VERSION "HNNBNNNYNNNNNNNNNNNNNNNNNNNNNNNNNNNNNNNNNN/4/%%%/4/'%**4NNN///"

NS_ :

BS_:

BU_: ADR_PAG_X2 BAP_Tester GW_App_PAG_PF GW_Routing_PAG_PF Klima_PAG_PF Klimakomp_Dash_PAG_PF Kombi_PAG_PF Miko_PAG_X2 OCU_PAG_PF RDK_High_PAG_PF

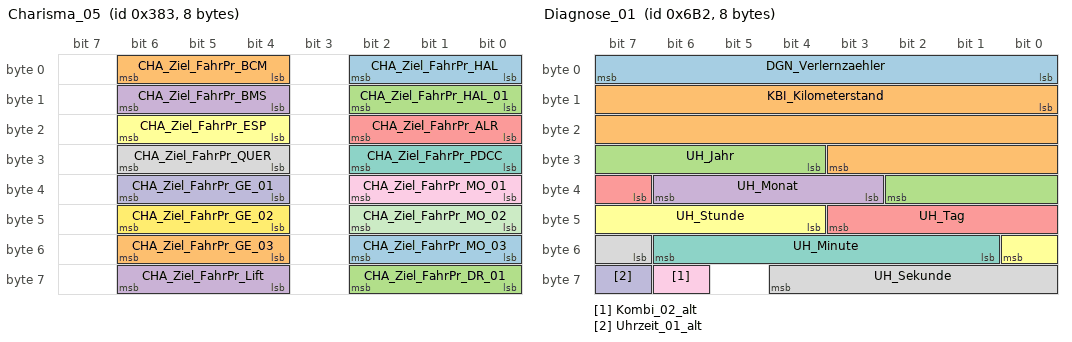
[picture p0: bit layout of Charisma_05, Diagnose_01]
BO_ 899 Charisma_05: 8 Klima_PAG_PF
 SG_ CHA_Ziel_FahrPr_HAL : 0|3@1+ (1,0) [0|7] ""  GW_Routing_PAG_PF
 SG_ CHA_Ziel_FahrPr_BCM : 4|3@1+ (1,0) [0|7] ""  GW_Routing_PAG_PF
 SG_ CHA_Ziel_FahrPr_HAL_01 : 8|3@1+ (1,0) [0|7] ""  GW_Routing_PAG_PF
 SG_ CHA_Ziel_FahrPr_BMS : 12|3@1+ (1,0) [0|7] ""  GW_Routing_PAG_PF
 SG_ CHA_Ziel_FahrPr_ALR : 16|3@1+ (1,0) [0|7] ""  GW_Routing_PAG_PF
 SG_ CHA_Ziel_FahrPr_ESP : 20|3@1+ (1,0) [0|7] ""  GW_Routing_PAG_PF
 SG_ CHA_Ziel_FahrPr_PDCC : 24|3@1+ (1,0) [0|7] ""  GW_Routing_PAG_PF
 SG_ CHA_Ziel_FahrPr_QUER : 28|3@1+ (1,0) [0|7] ""  GW_Routing_PAG_PF
 SG_ CHA_Ziel_FahrPr_MO_01 : 32|3@1+ (1,0) [0|7] ""  GW_Routing_PAG_PF
 SG_ CHA_Ziel_FahrPr_GE_01 : 36|3@1+ (1,0) [0|7] ""  GW_Routing_PAG_PF
 SG_ CHA_Ziel_FahrPr_MO_02 : 40|3@1+ (1,0) [0|7] ""  GW_Routing_PAG_PF
 SG_ CHA_Ziel_FahrPr_GE_02 : 44|3@1+ (1,0) [0|7] ""  GW_Routing_PAG_PF
 SG_ CHA_Ziel_FahrPr_MO_03 : 48|3@1+ (1,0) [0|7] ""  GW_Routing_PAG_PF
 SG_ CHA_Ziel_FahrPr_GE_03 : 52|3@1+ (1,0) [0|7] ""  GW_Routing_PAG_PF
 SG_ CHA_Ziel_FahrPr_DR_01 : 56|3@1+ (1,0) [0|7] ""  GW_Routing_PAG_PF
 SG_ CHA_Ziel_FahrPr_Lift : 60|3@1+ (1,0) [0|7] ""  GW_Routing_PAG_PF

BO_ 1335 Charisma_06: 8 GW_Routing_PAG_PF
 SG_ ALR_Charisma_FahrPr : 0|3@1+ (1,0) [0|7] "" Vector__XXX
 SG_ ALR_Charisma_Status : 3|2@1+ (1,0) [0|3] "" Vector__XXX
 SG_ ALR_Charisma_Umschaltung : 5|2@1+ (1,0) [0|3] "" Vector__XXX
 SG_ Allrad_02_alt : 7|1@1+ (1,0) [0|1] "" Vector__XXX
 SG_ ESP_Charisma_FahrPr : 8|3@1+ (1,0) [0|7] ""  Klima_PAG_PF
 SG_ ESP_Charisma_Status : 11|2@1+ (1,0) [0|3] ""  Klima_PAG_PF
 SG_ ESP_Charisma_Umschaltung : 13|2@1+ (1,0) [0|3] ""  Klima_PAG_PF
 SG_ ESP_11_alt : 15|1@1+ (1,0) [0|1] ""  Klima_PAG_PF
 SG_ PDCC_Charisma_FahrPr : 16|3@1+ (1,0) [0|7] "" Vector__XXX
 SG_ PDCC_Charisma_Status : 19|2@1+ (1,0) [0|3] "" Vector__XXX
 SG_ PDCC_Charisma_Umschaltung : 21|2@1+ (1,0) [0|3] "" Vector__XXX
 SG_ PDCC_01_PAG_alt : 23|1@1+ (1,0) [0|1] "" Vector__XXX
 SG_ QUER_Charisma_FahrPr : 24|3@1+ (1,0) [0|7] "" Vector__XXX
 SG_ QUER_Charisma_Status : 27|2@1+ (1,0) [0|3] "" Vector__XXX
 SG_ QUER_Charisma_Umschaltung : 29|2@1+ (1,0) [0|3] "" Vector__XXX
 SG_ Quersperre_02_PAG_alt : 31|1@1+ (1,0) [0|1] "" Vector__XXX
 SG_ HAL_Charisma_FahrPr : 32|3@1+ (1,0) [0|7] ""  Klima_PAG_PF
 SG_ HAL_Charisma_Status : 35|2@1+ (1,0) [0|3] ""  Klima_PAG_PF
 SG_ HAL_01_alt : 39|1@1+ (1,0) [0|1] ""  Klima_PAG_PF
 SG_ Lift_Charisma_FahrPr : 40|3@1+ (1,0) [0|7] ""  Klima_PAG_PF
 SG_ Lift_Charisma_Status : 43|2@1+ (1,0) [0|3] ""  Klima_PAG_PF
 SG_ Lift_Charisma_Umschaltung : 45|2@1+ (1,0) [0|3] ""  Klima_PAG_PF
 SG_ Lift_01_alt : 47|1@1+ (1,0) [0|1] ""  Klima_PAG_PF

BO_ 1714 Diagnose_01: 8 GW_App_PAG_PF
 SG_ DGN_Verlernzaehler : 0|8@1+ (1,0) [0|254] ""  ADR_PAG_X2,Klima_PAG_PF,Klimakomp_Dash_PAG_PF,Kombi_PAG_PF,Miko_PAG_X2,OCU_PAG_PF,RDK_High_PAG_PF
 SG_ KBI_Kilometerstand : 8|20@1+ (1,0) [0|1048573] "Unit_KiloMeter"  ADR_PAG_X2,Klima_PAG_PF,Klimakomp_Dash_PAG_PF,Miko_PAG_X2,OCU_PAG_PF,RDK_High_PAG_PF
 SG_ UH_Jahr : 28|7@1+ (1,2000) [2000|2127] "Unit_Year"  ADR_PAG_X2,Klima_PAG_PF,Klimakomp_Dash_PAG_PF,Kombi_PAG_PF,Miko_PAG_X2,OCU_PAG_PF,RDK_High_PAG_PF
 SG_ UH_Monat : 35|4@1+ (1,0) [1|12] "Unit_Month"  ADR_PAG_X2,Klima_PAG_PF,Klimakomp_Dash_PAG_PF,Kombi_PAG_PF,Miko_PAG_X2,OCU_PAG_PF,RDK_High_PAG_PF
 SG_ UH_Tag : 39|5@1+ (1,0) [1|31] "Unit_Day"  ADR_PAG_X2,Klima_PAG_PF,Klimakomp_Dash_PAG_PF,Kombi_PAG_PF,Miko_PAG_X2,OCU_PAG_PF,RDK_High_PAG_PF
 SG_ UH_Stunde : 44|5@1+ (1,0) [0|23] "Unit_Hours"  ADR_PAG_X2,Klima_PAG_PF,Klimakomp_Dash_PAG_PF,Kombi_PAG_PF,Miko_PAG_X2,OCU_PAG_PF,RDK_High_PAG_PF
 SG_ UH_Minute : 49|6@1+ (1,0) [0|59] "Unit_Minut"  ADR_PAG_X2,Klima_PAG_PF,Klimakomp_Dash_PAG_PF,Kombi_PAG_PF,Miko_PAG_X2,OCU_PAG_PF,RDK_High_PAG_PF
 SG_ UH_Sekunde : 55|6@1+ (1,0) [0|59] "Unit_Secon"  ADR_PAG_X2,Klima_PAG_PF,Klimakomp_Dash_PAG_PF,Kombi_PAG_PF,Miko_PAG_X2,OCU_PAG_PF,RDK_High_PAG_PF
 SG_ Kombi_02_alt : 62|1@1+ (1,0) [0|1] ""  ADR_PAG_X2,Klima_PAG_PF,Klimakomp_Dash_PAG_PF,Miko_PAG_X2,OCU_PAG_PF,RDK_High_PAG_PF
 SG_ Uhrzeit_01_alt : 63|1@1+ (1,0) [0|1] ""  ADR_PAG_X2,Klima_PAG_PF,Klimakomp_Dash_PAG_PF,Miko_PAG_X2,OCU_PAG_PF,RDK_High_PAG_PF

BO_ 1009 Diagnose_02_PAG: 8 GW_App_PAG_PF
 SG_ GW_STH_Anf : 0|2@1+ (1,0) [0|3] "" Vector__XXX
 SG_ FSAktivBit : 9|1@1+ (1,0) [0|1] "" Vector__XXX

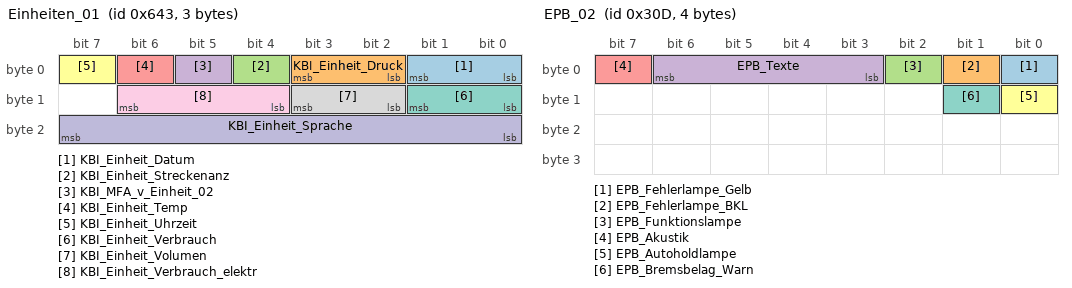
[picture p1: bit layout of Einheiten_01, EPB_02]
BO_ 1603 Einheiten_01: 3 ADR_PAG_X2
 SG_ KBI_Einheit_Datum : 0|2@1+ (1,0) [0|3] ""  GW_Routing_PAG_PF,Kombi_PAG_PF
 SG_ KBI_Einheit_Druck : 2|2@1+ (1,0) [0|3] ""  GW_Routing_PAG_PF,Kombi_PAG_PF
 SG_ KBI_Einheit_Streckenanz : 4|1@1+ (1,0) [0|1] ""  GW_Routing_PAG_PF,Kombi_PAG_PF,OCU_PAG_PF
 SG_ KBI_MFA_v_Einheit_02 : 5|1@1+ (1,0) [0|1] ""  GW_Routing_PAG_PF,Kombi_PAG_PF,OCU_PAG_PF
 SG_ KBI_Einheit_Temp : 6|1@1+ (1,0) [0|1] ""  GW_Routing_PAG_PF,Klima_PAG_PF,Kombi_PAG_PF,Miko_PAG_X2,OCU_PAG_PF
 SG_ KBI_Einheit_Uhrzeit : 7|1@1+ (1,0) [0|1] ""  GW_Routing_PAG_PF,Kombi_PAG_PF
 SG_ KBI_Einheit_Verbrauch : 8|2@1+ (1,0) [0|3] ""  GW_Routing_PAG_PF,Kombi_PAG_PF,OCU_PAG_PF
 SG_ KBI_Einheit_Volumen : 10|2@1+ (1,0) [0|3] ""  GW_Routing_PAG_PF,Kombi_PAG_PF
 SG_ KBI_Einheit_Verbrauch_elektr : 12|3@1+ (1,0) [0|7] ""  GW_Routing_PAG_PF
 SG_ KBI_Einheit_Sprache : 16|8@1+ (1,0) [0|255] ""  GW_Routing_PAG_PF,Kombi_PAG_PF,Miko_PAG_X2

BO_ 781 EPB_02: 4 GW_Routing_PAG_PF
 SG_ EPB_Fehlerlampe_Gelb : 0|1@1+ (1,0) [0|1] ""  Kombi_PAG_PF
 SG_ EPB_Fehlerlampe_BKL : 1|1@1+ (1,0) [0|1] "" Vector__XXX
 SG_ EPB_Funktionslampe : 2|1@1+ (1,0) [0|1] "" Vector__XXX
 SG_ EPB_Texte : 3|4@1+ (1,0) [0|15] ""  Kombi_PAG_PF
 SG_ EPB_Akustik : 7|1@1+ (1,0) [0|1] ""  Kombi_PAG_PF
 SG_ EPB_Autoholdlampe : 8|1@1+ (1,0) [0|1] "" Vector__XXX
 SG_ EPB_Bremsbelag_Warn : 9|1@1+ (1,0) [0|1] "" Vector__XXX

BO_ 256 ESP_01: 8 GW_Routing_PAG_PF
 SG_ ESP_01_CHK : 0|8@1+ (1,0) [0|255] "" Vector__XXX
 SG_ ESP_01_BZ : 8|4@1+ (1,0) [0|15] "" Vector__XXX
 SG_ ASR_Moment_langsam : 12|10@1+ (1,0) [0|1021] "" Vector__XXX
 SG_ ASR_MSR_Moment_schnell : 22|10@1+ (1,0) [0|1021] "" Vector__XXX
 SG_ ESP_v_Signal : 32|16@1+ (0.01,0) [0|655.32] "Unit_KiloMeterPerHour" Vector__XXX
 SG_ ASR_Tastung_passiv : 48|1@1+ (1,0) [0|1] ""  ADR_PAG_X2,Klima_PAG_PF,Kombi_PAG_PF
 SG_ ESP_Tastung_passiv : 49|1@1+ (1,0) [0|1] "" Vector__XXX
 SG_ ESP_Systemstatus : 50|1@1+ (1,0) [0|1] "" Vector__XXX
 SG_ ASR_Schalteingriff : 51|2@1+ (1,0) [0|3] "" Vector__XXX
 SG_ OBD_Schlechtweg : 53|1@1+ (1,0) [0|1] "" Vector__XXX
 SG_ OBD_QBit_Schlechtweg : 54|1@1+ (1,0) [0|1] "" Vector__XXX
 SG_ ESP_QBit_v_Signal : 55|1@1+ (1,0) [0|1] "" Vector__XXX
 SG_ ABS_Bremsung : 56|1@1+ (1,0) [0|1] "" Vector__XXX
 SG_ ASR_Anf : 57|1@1+ (1,0) [0|1] "" Vector__XXX
 SG_ MSR_Anf : 58|1@1+ (1,0) [0|1] "" Vector__XXX
 SG_ EBV_Eingriff : 59|1@1+ (1,0) [0|1] "" Vector__XXX
 SG_ EDS_Eingriff : 60|1@1+ (1,0) [0|1] "" Vector__XXX
 SG_ ESP_Eingriff : 61|1@1+ (1,0) [0|1] "" Vector__XXX
 SG_ ESP_ASP : 62|1@1+ (1,0) [0|1] "" Vector__XXX
 SG_ ESP_KD_Fehler : 63|1@1+ (1,0) [0|1] "" Vector__XXX

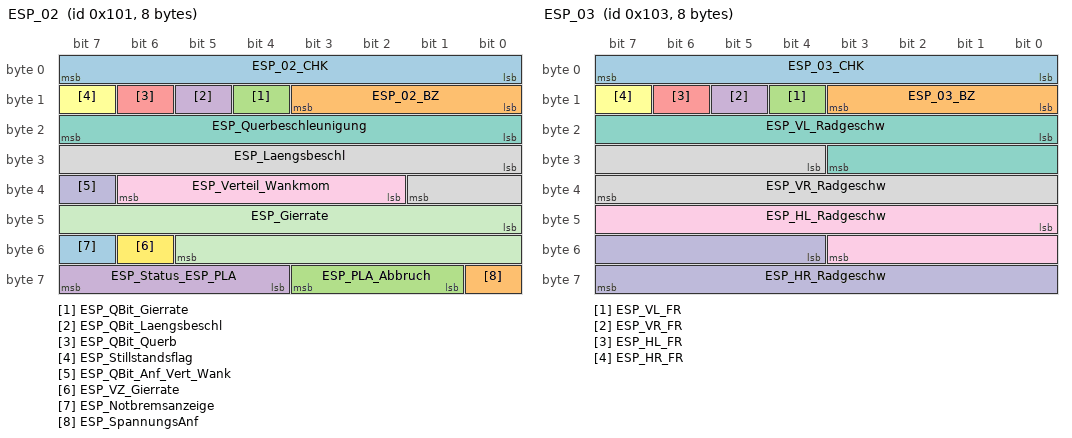
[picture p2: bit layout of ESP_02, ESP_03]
BO_ 257 ESP_02: 8 GW_Routing_PAG_PF
 SG_ ESP_02_CHK : 0|8@1+ (1,0) [0|255] "" Vector__XXX
 SG_ ESP_02_BZ : 8|4@1+ (1,0) [0|15] "" Vector__XXX
 SG_ ESP_QBit_Gierrate : 12|1@1+ (1,0) [0|1] "" Vector__XXX
 SG_ ESP_QBit_Laengsbeschl : 13|1@1+ (1,0) [0|1] "" Vector__XXX
 SG_ ESP_QBit_Querb : 14|1@1+ (1,0) [0|1] "" Vector__XXX
 SG_ ESP_Stillstandsflag : 15|1@1+ (1,0) [0|1] "" Vector__XXX
 SG_ ESP_Querbeschleunigung : 16|8@1+ (0.01,-1.27) [-1.27|1.27] "Unit_ForceOfGravi" Vector__XXX
 SG_ ESP_Laengsbeschl : 24|10@1+ (0.03125,-16) [-16|15.90625] "Unit_MeterPerSeconSquar"  ADR_PAG_X2,Kombi_PAG_PF
 SG_ ESP_Verteil_Wankmom : 34|5@1+ (0.1,-1) [-1|1] "" Vector__XXX
 SG_ ESP_QBit_Anf_Vert_Wank : 39|1@1+ (1,0) [0|1] "" Vector__XXX
 SG_ ESP_Gierrate : 40|14@1+ (0.01,0) [0|163.82] "Unit_DegreOfArcPerSecon" Vector__XXX
 SG_ ESP_VZ_Gierrate : 54|1@1+ (1,0) [0|1] "" Vector__XXX
 SG_ ESP_Notbremsanzeige : 55|1@1+ (1,0) [0|1] "" Vector__XXX
 SG_ ESP_SpannungsAnf : 56|1@1+ (1,0) [0|1] "" Vector__XXX
 SG_ ESP_PLA_Abbruch : 57|3@1+ (1,0) [0|7] "" Vector__XXX
 SG_ ESP_Status_ESP_PLA : 60|4@1+ (1,0) [0|15] "" Vector__XXX

BO_ 259 ESP_03: 8 GW_Routing_PAG_PF
 SG_ ESP_03_CHK : 0|8@1+ (1,0) [0|255] "" Vector__XXX
 SG_ ESP_03_BZ : 8|4@1+ (1,0) [0|15] "" Vector__XXX
 SG_ ESP_VL_FR : 12|1@1+ (1,0) [0|1] "" Vector__XXX
 SG_ ESP_VR_FR : 13|1@1+ (1,0) [0|1] "" Vector__XXX
 SG_ ESP_HL_FR : 14|1@1+ (1,0) [0|1] "" Vector__XXX
 SG_ ESP_HR_FR : 15|1@1+ (1,0) [0|1] "" Vector__XXX
 SG_ ESP_VL_Radgeschw : 16|12@1+ (0.1,0) [0|409.2] "Unit_KiloMeterPerHour"  Kombi_PAG_PF
 SG_ ESP_VR_Radgeschw : 28|12@1+ (0.1,0) [0|409.2] "Unit_KiloMeterPerHour"  Kombi_PAG_PF
 SG_ ESP_HL_Radgeschw : 40|12@1+ (0.1,0) [0|409.2] "Unit_KiloMeterPerHour"  Kombi_PAG_PF
 SG_ ESP_HR_Radgeschw : 52|12@1+ (0.1,0) [0|409.2] "Unit_KiloMeterPerHour"  Kombi_PAG_PF

BO_ 776 ESP_04: 8 GW_Routing_PAG_PF
 SG_ ESP_Meldungen : 0|3@1+ (1,0) [0|7] ""  Kombi_PAG_PF
 SG_ ESP_HDC_FktLampe : 3|1@1+ (1,0) [0|1] "" Vector__XXX
 SG_ ESP_Lampe : 4|1@1+ (1,0) [0|1] ""  Kombi_PAG_PF
 SG_ ABS_Lampe : 5|1@1+ (1,0) [0|1] ""  Kombi_PAG_PF
 SG_ BK_Lampe : 6|1@1+ (1,0) [0|1] ""  Kombi_PAG_PF
 SG_ ESP_Akustik : 7|2@1+ (1,0) [0|3] "" Vector__XXX
 SG_ ESP_Diagnose : 9|1@1+ (1,0) [0|1] ""  Kombi_PAG_PF
 SG_ ESP_Textanzeigen_02 : 10|5@1+ (1,0) [0|31] ""  Kombi_PAG_PF
 SG_ ESP_Off_Lampe : 15|1@1+ (1,0) [0|1] ""  Klima_PAG_PF
 SG_ ESP_m_Raddrehz : 16|15@1+ (0.002,0) [0|65.278] "Unit_Hertz" Vector__XXX
 SG_ ESP_ASR_Lampe : 31|1@1+ (1,0) [0|1] "" Vector__XXX
 SG_ ESP_Wegimp_VA : 32|11@1+ (1,0) [0|2047] ""  Kombi_PAG_PF
 SG_ ESP_Fehlerstatus_Wegimp : 43|1@1+ (1,0) [0|1] "" Vector__XXX
 SG_ ESP_Wegimp_Ueberlauf : 44|1@1+ (1,0) [0|1] ""  Kombi_PAG_PF
 SG_ ESP_QBit_Wegimp_VA : 45|1@1+ (1,0) [0|1] "" Vector__XXX
 SG_ ESP_Displaywarnungen : 46|2@1+ (1,0) [0|3] "" Vector__XXX
 SG_ ESP_HDC_Regelgeschw : 48|7@1+ (0.32,0) [0.32|39.68] "Unit_KiloMeterPerHour" Vector__XXX
 SG_ ESP_BKV_Warnung : 55|1@1+ (1,0) [0|1] ""  Kombi_PAG_PF
 SG_ ESP_Zaehnezahl : 56|8@1+ (1,0) [0|255] ""  Kombi_PAG_PF

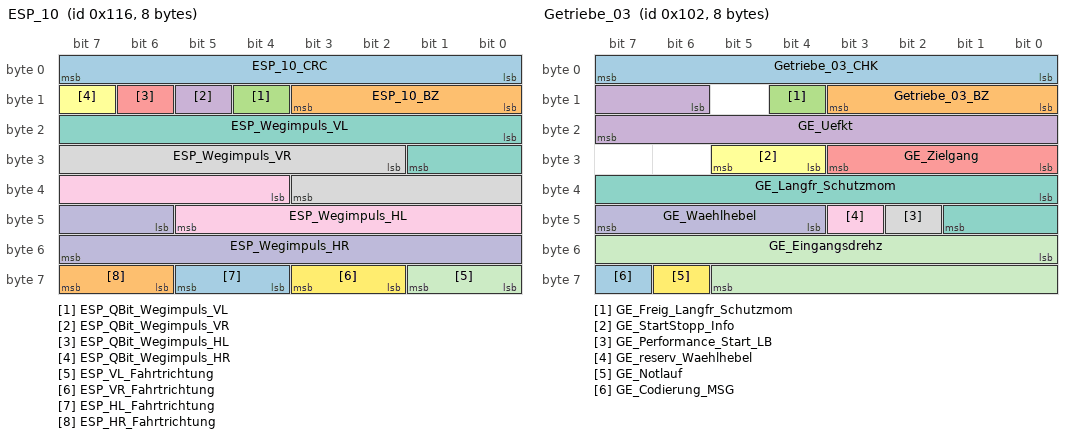
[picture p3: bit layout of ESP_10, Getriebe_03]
BO_ 278 ESP_10: 8 GW_Routing_PAG_PF
 SG_ ESP_10_CRC : 0|8@1+ (1,0) [0|255] "" Vector__XXX
 SG_ ESP_10_BZ : 8|4@1+ (1,0) [0|15] "" Vector__XXX
 SG_ ESP_QBit_Wegimpuls_VL : 12|1@1+ (1,0) [0|1] ""  ADR_PAG_X2
 SG_ ESP_QBit_Wegimpuls_VR : 13|1@1+ (1,0) [0|1] ""  ADR_PAG_X2
 SG_ ESP_QBit_Wegimpuls_HL : 14|1@1+ (1,0) [0|1] ""  ADR_PAG_X2
 SG_ ESP_QBit_Wegimpuls_HR : 15|1@1+ (1,0) [0|1] ""  ADR_PAG_X2
 SG_ ESP_Wegimpuls_VL : 16|10@1+ (1,0) [0|1000] ""  ADR_PAG_X2
 SG_ ESP_Wegimpuls_VR : 26|10@1+ (1,0) [0|1000] ""  ADR_PAG_X2
 SG_ ESP_Wegimpuls_HL : 36|10@1+ (1,0) [0|1000] ""  ADR_PAG_X2
 SG_ ESP_Wegimpuls_HR : 46|10@1+ (1,0) [0|1000] ""  ADR_PAG_X2
 SG_ ESP_VL_Fahrtrichtung : 56|2@1+ (1,0) [0|3] ""  ADR_PAG_X2
 SG_ ESP_VR_Fahrtrichtung : 58|2@1+ (1,0) [0|3] ""  ADR_PAG_X2
 SG_ ESP_HL_Fahrtrichtung : 60|2@1+ (1,0) [0|3] ""  ADR_PAG_X2
 SG_ ESP_HR_Fahrtrichtung : 62|2@1+ (1,0) [0|3] ""  ADR_PAG_X2

BO_ 963 Gateway_01: 8 GW_Routing_PAG_PF
 SG_ Motor_03_alt : 0|1@1+ (1,0) [0|1] ""  ADR_PAG_X2,Klima_PAG_PF,Kombi_PAG_PF,RDK_High_PAG_PF
 SG_ Getriebe_03_alt : 1|1@1+ (1,0) [0|1] ""  ADR_PAG_X2
 SG_ ESP_02_alt : 2|1@1+ (1,0) [0|1] "" Vector__XXX
 SG_ Motor_05_alt : 3|1@1+ (1,0) [0|1] ""  Klima_PAG_PF
 SG_ LWR_AFS_01_alt : 4|1@1+ (1,0) [0|1] "" Vector__XXX
 SG_ EPB_01_alt : 5|1@1+ (1,0) [0|1] ""  ADR_PAG_X2
 SG_ ESP_05_alt : 6|1@1+ (1,0) [0|1] "" Vector__XXX
 SG_ ESP_01_alt : 7|1@1+ (1,0) [0|1] ""  ADR_PAG_X2,Klima_PAG_PF,Kombi_PAG_PF
 SG_ ESP_v_Signal : 8|16@1+ (0.01,0) [0|655.32] "Unit_KiloMeterPerHour"  ADR_PAG_X2,Klima_PAG_PF,Kombi_PAG_PF
 SG_ ESP_Notbremsanzeige : 24|1@1+ (1,0) [0|1] "" Vector__XXX
 SG_ ECD_Bremslicht : 25|1@1+ (1,0) [0|1] "" Vector__XXX
 SG_ EPB_Status : 26|2@1+ (1,0) [0|3] ""  ADR_PAG_X2
 SG_ MO_Anf_KL75 : 28|1@1+ (1,0) [0|1] "" Vector__XXX
 SG_ MO_QBit_Fahrer_bremst : 29|1@1+ (1,0) [0|1] "" Vector__XXX
 SG_ EPB_BCM2_Motor_Wakeup : 30|1@1+ (1,0) [0|1] "" Vector__XXX
 SG_ ESP_QBit_v_Signal : 31|1@1+ (1,0) [0|1] "" Vector__XXX
 SG_ GE_Waehlhebel : 32|4@1+ (1,0) [0|15] ""  ADR_PAG_X2
 SG_ MO_Motor_laeuft : 36|1@1+ (1,0) [0|1] ""  Klima_PAG_PF,Kombi_PAG_PF
 SG_ MO_Verbot_EKP : 37|1@1+ (1,0) [0|1] "" Vector__XXX
 SG_ MO_Anf_Pruefimpuls : 38|1@1+ (1,0) [0|1] "" Vector__XXX
 SG_ LWR_Touristenmodus_aktiv : 39|1@1+ (1,0) [0|1] "" Vector__XXX
 SG_ MO_Drehzahl_01 : 40|16@1+ (0.25,0) [0|16383] "Unit_MinutInver"  ADR_PAG_X2,RDK_High_PAG_PF
 SG_ MO_Klima_Eingr : 56|2@1+ (1,0) [0|3] ""  Klima_PAG_PF
 SG_ MO_BLS : 58|1@1+ (1,0) [0|1] "" Vector__XXX
 SG_ MO_Fahrer_bremst : 59|1@1+ (1,0) [0|1] "" Vector__XXX
 SG_ MO_Aussp_Anlass : 60|1@1+ (1,0) [0|1] "" Vector__XXX
 SG_ MO_Freig_Anlass : 61|1@1+ (1,0) [0|1] "" Vector__XXX
 SG_ MO_Kuppl_schalter : 62|1@1+ (1,0) [0|1] "" Vector__XXX
 SG_ MO_Interlock : 63|1@1+ (1,0) [0|1] "" Vector__XXX

BO_ 1643 Gateway_03: 8 GW_Routing_PAG_PF
 SG_ Motor_07_alt : 0|1@1+ (1,0) [0|1] "" Vector__XXX
 SG_ Motor_Code_01_alt : 1|1@1+ (1,0) [0|1] "" Vector__XXX
 SG_ Kombi_02_alt : 2|1@1+ (1,0) [0|1] ""  RDK_High_PAG_PF
 SG_ Telefon_01_alt : 3|1@1+ (1,0) [0|1] "" Vector__XXX
 SG_ EPB_01_alt : 4|1@1+ (1,0) [0|1] "" Vector__XXX
 SG_ Motor_05_alt : 5|1@1+ (1,0) [0|1] ""  Klima_PAG_PF
 SG_ Motor_06_alt : 6|1@1+ (1,0) [0|1] ""  ADR_PAG_X2,Klima_PAG_PF
 SG_ MO_Kuehlmittel_Temp : 8|8@1+ (0.75,-48) [-48|141.75] "Unit_DegreCelsi" Vector__XXX
 SG_ KBI_Aussen_Temp_gef : 16|8@1+ (0.5,-50) [-50|75] "Unit_DegreCelsi"  RDK_High_PAG_PF
 SG_ MO_Kraftstoffart : 24|4@1+ (1,0) [0|15] "" Vector__XXX
 SG_ MO_Kennfeldk : 28|1@1+ (1,0) [0|1] "" Vector__XXX
 SG_ KBI_QBit_Aussen_Temp_gef : 29|1@1+ (1,0) [0|1] ""  RDK_High_PAG_PF
 SG_ MO_Absperrventil_oeffnen : 30|2@1+ (1,0) [0|3] "" Vector__XXX
 SG_ KBI_Standzeit : 32|15@1+ (4,0) [0|131068] "Unit_Secon" Vector__XXX
 SG_ KBI_Reset_Standzeit : 47|1@1+ (1,0) [0|1] "" Vector__XXX
 SG_ TF_Phone_mute : 48|1@1+ (1,0) [0|1] "" Vector__XXX
 SG_ EPB_QBit_Pedalweg_Kuppl : 49|1@1+ (1,0) [0|1] "" Vector__XXX
 SG_ TF_Mute_Msg_Code : 50|3@1+ (1,0) [0|7] "" Vector__XXX
 SG_ MO_HYB_Fahrbereitschaft : 53|1@1+ (1,0) [0|1] ""  ADR_PAG_X2,Klima_PAG_PF
 SG_ MO_EKlKomLeiRed : 54|2@1+ (1,0) [0|3] ""  Klima_PAG_PF
 SG_ EPB_Pedalweg_Kuppl : 56|8@1+ (0.4,0) [8|92] "Unit_PerCent" Vector__XXX

BO_ 924 Gateway_05: 8 GW_Routing_PAG_PF
 SG_ BCM1_02_alt : 0|1@1+ (1,0) [0|1] "" Vector__XXX
 SG_ Wischer_01_alt : 1|1@1+ (1,0) [0|1] "" Vector__XXX
 SG_ Klima_02_alt : 2|1@1+ (1,0) [0|1] "" Vector__XXX
 SG_ BCM1_01_alt : 3|1@1+ (1,0) [0|1] "" Vector__XXX
 SG_ ESP_07_alt : 4|1@1+ (1,0) [0|1] "" Vector__XXX
 SG_ TSG_BT_1_alt : 5|1@1+ (1,0) [0|1] "" Vector__XXX
 SG_ TSG_HL_1_alt : 6|1@1+ (1,0) [0|1] "" Vector__XXX
 SG_ TSG_HR_1_alt : 7|1@1+ (1,0) [0|1] "" Vector__XXX
 SG_ Motor_02_alt : 8|1@1+ (1,0) [0|1] "" Vector__XXX
 SG_ Klima_Sensor_02_alt : 9|1@1+ (1,0) [0|1] "" Vector__XXX
 SG_ TSG_FT_1_alt : 10|1@1+ (1,0) [0|1] "" Vector__XXX
 SG_ Motor_05_alt : 11|1@1+ (1,0) [0|1] ""  Klima_PAG_PF
 SG_ QSP_01_alt : 12|1@1+ (1,0) [0|1] "" Vector__XXX
 SG_ Parkhilfe_01_alt : 13|1@1+ (1,0) [0|1] "" Vector__XXX
 SG_ Fahrwerk_02_alt : 14|1@1+ (1,0) [0|1] "" Vector__XXX
 SG_ GW_05_va_27 : 15|1@1+ (1,0) [0|1] "" Vector__XXX
 SG_ BCM1_MH_WIV_Schalter : 16|1@1+ (1,0) [0|1] "" Vector__XXX
 SG_ Wischer_vorne_aktiv : 17|1@1+ (1,0) [0|1] "" Vector__XXX
 SG_ BCM1_Rueckfahrlicht_Schalter : 18|1@1+ (1,0) [0|1] "" Vector__XXX
 SG_ MO_Status_Normalbetrieb_01 : 19|1@1+ (1,0) [0|1] "" Vector__XXX
 SG_ KL_Zuheizer_Freigabe : 20|1@1+ (1,0) [0|1] "" Vector__XXX
 SG_ BCM1_Vorwaertsgang_eingelegt : 21|1@1+ (1,0) [0|1] "" Vector__XXX
 SG_ ESP_Codierung_ADS : 22|2@1+ (1,0) [0|3] "" Vector__XXX
 SG_ QSP_StartStopp_Info : 24|2@1+ (1,0) [0|3] "" Vector__XXX
 SG_ FA_StartStopp_Info : 26|2@1+ (1,0) [0|3] "" Vector__XXX
 SG_ PH_StartStopp_Info : 28|2@1+ (1,0) [0|3] "" Vector__XXX
 SG_ KL_Beschlagsgefahr : 30|1@1+ (1,0) [0|1] "" Vector__XXX
 SG_ BCM1_GLW_Fernlicht_Anf : 31|1@1+ (1,0) [0|1] "" Vector__XXX
 SG_ BCM1_RFahrlicht_Fzg_Anf : 32|1@1+ (1,0) [0|1] "" Vector__XXX
 SG_ FT_Tuer_geoeffnet : 33|1@1+ (1,0) [0|1] "" Vector__XXX
 SG_ MO_Handshake_STH : 34|1@1+ (1,0) [0|1] "" Vector__XXX
 SG_ FT_Sperrklinke : 35|1@1+ (1,0) [0|1] "" Vector__XXX
 SG_ BCM1_OBD_FStatus_ATemp : 36|4@1+ (1,0) [0|15] "" Vector__XXX
 SG_ BCM1_Aussen_Temp_ungef : 40|8@1+ (0.5,-50) [-50|76] "Unit_DegreCelsi" Vector__XXX
 SG_ BCM1_Oeldruck_Schalter : 48|1@1+ (1,0) [0|1] "" Vector__XXX
 SG_ BCM1_Oeldruck_Schalter_2 : 49|1@1+ (1,0) [0|1] "" Vector__XXX
 SG_ BT_Tuer_geoeffnet : 50|1@1+ (1,0) [0|1] "" Vector__XXX
 SG_ HL_Tuer_geoeffnet : 51|1@1+ (1,0) [0|1] "" Vector__XXX
 SG_ HR_Tuer_geoeffnet : 52|1@1+ (1,0) [0|1] "" Vector__XXX
 SG_ BCM1_Adaptive_Lichtvert_Anf : 53|1@1+ (1,0) [0|1] "" Vector__XXX
 SG_ BCM1_Gleitende_Leuchtw_Anf : 54|1@1+ (1,0) [0|1] "" Vector__XXX
 SG_ BCM1_Schalter_StartStopp : 55|1@1+ (1,0) [0|1] "" Vector__XXX
 SG_ ESP_Offroad_Modus : 56|1@1+ (1,0) [0|1] "" Vector__XXX
 SG_ MO_Freig_Reku : 57|2@1+ (1,0) [0|3] ""  Klima_PAG_PF
 SG_ KL_HSH_ein_Soll : 59|1@1+ (1,0) [0|1] "" Vector__XXX
 SG_ FT_Tuerkontakt_Rohsignal : 60|1@1+ (1,0) [0|1] "" Vector__XXX

BO_ 1318 Gateway_07: 8 GW_Routing_PAG_PF
 SG_ Klima_Sensor_02_alt : 0|1@1+ (1,0) [0|1] "" Vector__XXX
 SG_ Wischer_01_alt : 1|1@1+ (1,0) [0|1] "" Vector__XXX
 SG_ SMLS_01_alt : 2|1@1+ (1,0) [0|1] "" Vector__XXX
 SG_ Kessy_02_alt : 3|1@1+ (1,0) [0|1] "" Vector__XXX
 SG_ Blinkmodi_01_inaktiv : 4|1@1+ (1,0) [0|1] "" Vector__XXX
 SG_ Anhaenger_01_alt : 5|1@1+ (1,0) [0|1] "" Vector__XXX
 SG_ BCM1_01_alt : 6|1@1+ (1,0) [0|1] "" Vector__XXX
 SG_ BCM1_02_alt : 7|1@1+ (1,0) [0|1] "" Vector__XXX
 SG_ Innenlicht_01_alt : 8|1@1+ (1,0) [0|1] "" Vector__XXX
 SG_ BCM2_02_alt : 9|1@1+ (1,0) [0|1] "" Vector__XXX
 SG_ Motor_06_alt : 10|1@1+ (1,0) [0|1] ""  Klimakomp_Dash_PAG_PF
 SG_ HUD_01_alt : 11|1@1+ (1,0) [0|1] "" Vector__XXX
 SG_ TSG_FT_01_alt : 12|1@1+ (1,0) [0|1] "" Vector__XXX
 SG_ GW_07_va_25 : 13|1@1+ (1,0) [0|1] "" Vector__XXX
 SG_ GW_07_va_26 : 14|1@1+ (1,0) [0|1] "" Vector__XXX
 SG_ GW_07_va_27 : 15|1@1+ (1,0) [0|1] "" Vector__XXX
 SG_ BCM1_Aussen_Temp_ungef : 16|8@1+ (0.5,-50) [-50|76] "Unit_DegreCelsi" Vector__XXX
 SG_ BCM1_FStatus_Aussentemp_ungef : 24|1@1+ (1,0) [0|1] "" Vector__XXX
 SG_ Wischer_vorne_aktiv : 25|1@1+ (1,0) [0|1] "" Vector__XXX
 SG_ BH_Blinker_li : 26|1@1+ (1,0) [0|1] "" Vector__XXX
 SG_ BH_Blinker_re : 27|1@1+ (1,0) [0|1] "" Vector__XXX
 SG_ KY_Funkschl_Nr : 28|4@1+ (1,0) [0|15] "" Vector__XXX
 SG_ BCM1_Rueckfahrlicht_Schalter : 32|1@1+ (1,0) [0|1] "" Vector__XXX
 SG_ AAG_Anhaenger_erkannt : 33|1@1+ (1,0) [0|1] "" Vector__XXX
 SG_ BM_links : 34|1@1+ (1,0) [0|1] "" Vector__XXX
 SG_ BM_rechts : 35|1@1+ (1,0) [0|1] "" Vector__XXX
 SG_ BH_Fernlicht : 36|1@1+ (1,0) [0|1] "" Vector__XXX
 SG_ LDW_Taster : 37|1@1+ (1,0) [0|1] "" Vector__XXX
 SG_ LDW_Taster_Fehler : 38|1@1+ (1,0) [0|1] "" Vector__XXX
 SG_ LDW_Vib_Lenkrad_Fehler : 39|1@1+ (1,0) [0|1] "" Vector__XXX
 SG_ LV_Fernlicht_Anzeige : 40|1@1+ (1,0) [0|1] "" Vector__XXX
 SG_ LV_Abblendlicht_Anzeige : 41|1@1+ (1,0) [0|1] "" Vector__XXX
 SG_ LV_Nebellicht_Anzeige : 42|1@1+ (1,0) [0|1] "" Vector__XXX
 SG_ IL_Innenlicht_aktiv : 43|1@1+ (1,0) [0|1] "" Vector__XXX
 SG_ BCM1_MH_Schalter : 44|1@1+ (1,0) [0|1] "" Vector__XXX
 SG_ ZV_FT_offen : 45|1@1+ (1,0) [0|1] "" Vector__XXX
 SG_ ZV_BT_offen : 46|1@1+ (1,0) [0|1] "" Vector__XXX
 SG_ ZV_HL_offen : 47|1@1+ (1,0) [0|1] "" Vector__XXX
 SG_ ZV_HR_offen : 48|1@1+ (1,0) [0|1] "" Vector__XXX
 SG_ ZV_HD_offen : 49|1@1+ (1,0) [0|1] "" Vector__XXX
 SG_ ZV_verriegelt_extern_ist : 50|1@1+ (1,0) [0|1] "" Vector__XXX
 SG_ ZV_ist_Zustand_verfuegbar : 51|1@1+ (1,0) [0|1] "" Vector__XXX
 SG_ BCM1_NV_Taster : 52|1@1+ (1,0) [0|1] "" Vector__XXX
 SG_ MO_HYB_Fahrbereitschaft : 53|1@1+ (1,0) [0|1] ""  Klimakomp_Dash_PAG_PF
 SG_ HUD_VZE_in_Anzeige : 54|1@1+ (1,0) [0|1] "" Vector__XXX
 SG_ FT_SWA_Taster : 56|1@1+ (1,0) [0|1] "" Vector__XXX
 SG_ FT_SWA_Tasterdiagnose : 57|1@1+ (1,0) [0|1] "" Vector__XXX

BO_ 258 Getriebe_03: 8 GW_Routing_PAG_PF
 SG_ Getriebe_03_CHK : 0|8@1+ (1,0) [0|255] "" Vector__XXX
 SG_ Getriebe_03_BZ : 8|4@1+ (1,0) [0|15] "" Vector__XXX
 SG_ GE_Freig_Langfr_Schutzmom : 12|1@1+ (1,0) [0|1] "" Vector__XXX
 SG_ GE_Uefkt : 14|10@1+ (0.1,0) [0|102.2] "" Vector__XXX
 SG_ GE_Zielgang : 24|4@1+ (1,0) [0|15] ""  ADR_PAG_X2
 SG_ GE_StartStopp_Info : 28|2@1+ (1,0) [0|3] "" Vector__XXX
 SG_ GE_Langfr_Schutzmom : 32|10@1+ (1,0) [0|1021] "" Vector__XXX
 SG_ GE_Performance_Start_LB : 42|1@1+ (1,0) [0|1] "" Vector__XXX
 SG_ GE_reserv_Waehlhebel : 43|1@1+ (1,0) [0|1] "" Vector__XXX
 SG_ GE_Waehlhebel : 44|4@1+ (1,0) [0|15] "" Vector__XXX
 SG_ GE_Eingangsdrehz : 48|14@1+ (1,0) [0|16381] "Unit_MinutInver" Vector__XXX
 SG_ GE_Notlauf : 62|1@1+ (1,0) [0|1] "" Vector__XXX
 SG_ GE_Codierung_MSG : 63|1@1+ (1,0) [0|1] "" Vector__XXX

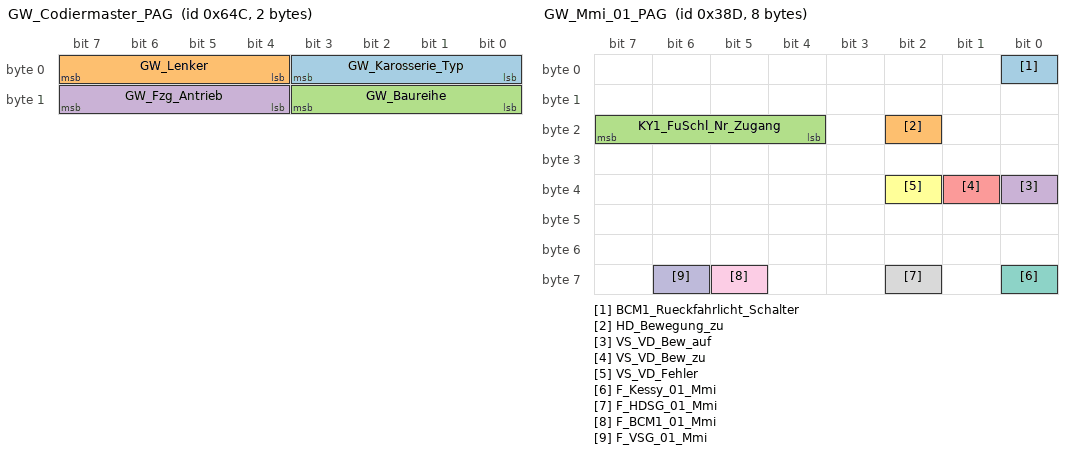
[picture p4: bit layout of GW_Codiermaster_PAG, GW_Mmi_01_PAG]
BO_ 1612 GW_Codiermaster_PAG: 2 GW_App_PAG_PF
 SG_ GW_Karosserie_Typ : 0|4@1+ (1,0) [0|15] ""  Klima_PAG_PF,OCU_PAG_PF
 SG_ GW_Lenker : 4|4@1+ (1,0) [0|15] ""  Klima_PAG_PF,OCU_PAG_PF
 SG_ GW_Baureihe : 8|4@1+ (1,0) [0|15] ""  Klima_PAG_PF,OCU_PAG_PF
 SG_ GW_Fzg_Antrieb : 12|4@1+ (1,0) [0|15] ""  OCU_PAG_PF

BO_ 909 GW_Mmi_01_PAG: 8 GW_Routing_PAG_PF
 SG_ BCM1_Rueckfahrlicht_Schalter : 0|1@1+ (1,0) [0|1] ""  ADR_PAG_X2,Klima_PAG_PF,Kombi_PAG_PF
 SG_ HD_Bewegung_zu : 18|1@1+ (1,0) [0|1] "" Vector__XXX
 SG_ KY1_FuSchl_Nr_Zugang : 20|4@1+ (1,0) [0|15] ""  Klima_PAG_PF
 SG_ VS_VD_Bew_auf : 32|1@1+ (1,0) [0|1] "" Vector__XXX
 SG_ VS_VD_Bew_zu : 33|1@1+ (1,0) [0|1] "" Vector__XXX
 SG_ VS_VD_Fehler : 34|1@1+ (1,0) [0|1] "" Vector__XXX
 SG_ F_Kessy_01_Mmi : 56|1@1+ (1,0) [0|1] ""  Klima_PAG_PF
 SG_ F_HDSG_01_Mmi : 58|1@1+ (1,0) [0|1] "" Vector__XXX
 SG_ F_BCM1_01_Mmi : 61|1@1+ (1,0) [0|1] ""  ADR_PAG_X2,Klima_PAG_PF,Kombi_PAG_PF
 SG_ F_VSG_01_Mmi : 62|1@1+ (1,0) [0|1] "" Vector__XXX

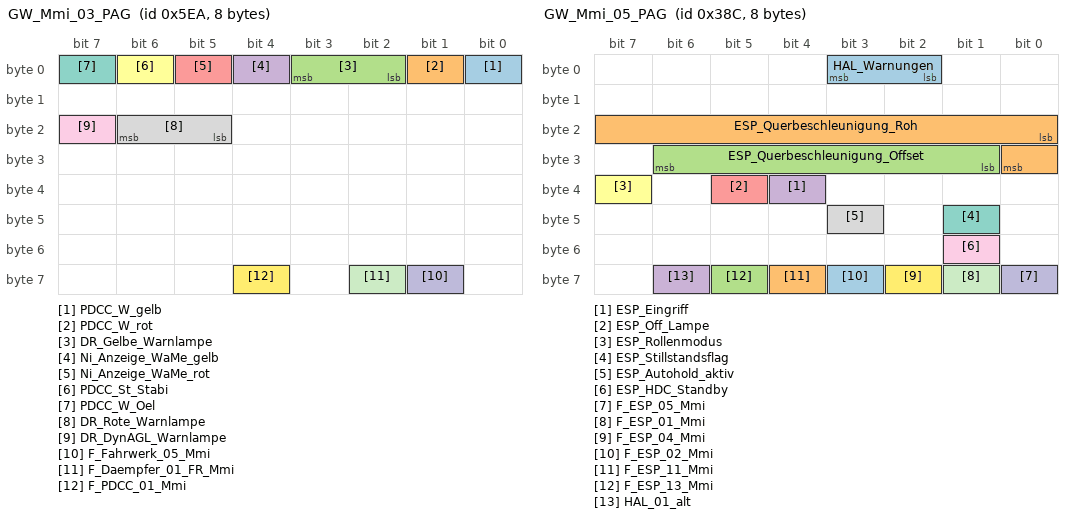
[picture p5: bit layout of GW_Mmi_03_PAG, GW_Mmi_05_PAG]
BO_ 1514 GW_Mmi_03_PAG: 8 GW_Routing_PAG_PF
 SG_ PDCC_W_gelb : 0|1@1+ (1,0) [0|1] "" Vector__XXX
 SG_ PDCC_W_rot : 1|1@1+ (1,0) [0|1] "" Vector__XXX
 SG_ DR_Gelbe_Warnlampe : 2|2@1+ (1,0) [0|3] ""  Kombi_PAG_PF
 SG_ Ni_Anzeige_WaMe_gelb : 4|1@1+ (1,0) [0|1] "" Vector__XXX
 SG_ Ni_Anzeige_WaMe_rot : 5|1@1+ (1,0) [0|1] "" Vector__XXX
 SG_ PDCC_St_Stabi : 6|1@1+ (1,0) [0|1] "" Vector__XXX
 SG_ PDCC_W_Oel : 7|1@1+ (1,0) [0|1] "" Vector__XXX
 SG_ DR_Rote_Warnlampe : 21|2@1+ (1,0) [0|3] ""  Kombi_PAG_PF
 SG_ DR_DynAGL_Warnlampe : 23|1@1+ (1,0) [0|1] ""  Kombi_PAG_PF
 SG_ F_Fahrwerk_05_Mmi : 57|1@1+ (1,0) [0|1] "" Vector__XXX
 SG_ F_Daempfer_01_FR_Mmi : 58|1@1+ (1,0) [0|1] ""  Kombi_PAG_PF
 SG_ F_PDCC_01_Mmi : 60|1@1+ (1,0) [0|1] "" Vector__XXX

BO_ 796 GW_Mmi_04_PAG: 8 GW_Routing_PAG_PF
 SG_ MO_Drehzahl_01 : 0|16@1+ (0.25,0) [0|16383] "Unit_MinutInver"  Klima_PAG_PF
 SG_ MO_Kuehlmittel_Temp : 16|8@1+ (0.75,-48) [-48|141.75] "Unit_DegreCelsi"  Klima_PAG_PF
 SG_ DR_Daempferreg_Texte : 24|4@1+ (1,0) [0|15] ""  ADR_PAG_X2,Kombi_PAG_PF
 SG_ MO_Ext_E_Fahrt_aktiv : 28|1@1+ (1,0) [0|1] "" Vector__XXX
 SG_ MO_HYB_VM_aktiv : 29|1@1+ (1,0) [0|1] ""  ADR_PAG_X2
 SG_ MO_Fehler_MSpG : 30|1@1+ (1,0) [0|1] "" Vector__XXX
 SG_ MO_Overboost : 31|1@1+ (1,0) [0|1] "" Vector__XXX
 SG_ DR_Systemstatus : 32|3@1+ (1,0) [0|7] ""  Klima_PAG_PF
 SG_ FA_Reglerstatus_Niveau : 35|4@1+ (1,0) [0|15] "" Vector__XXX
 SG_ GE_Segel_Status : 40|2@1+ (1,0) [0|3] ""  Klima_PAG_PF,Kombi_PAG_PF
 SG_ GE_Status_PaddleNeutral : 42|2@1+ (1,0) [0|3] ""  Kombi_PAG_PF
 SG_ F_Daempfer_01_FR_Mmi : 50|1@1+ (1,0) [0|1] ""  ADR_PAG_X2,Klima_PAG_PF,Kombi_PAG_PF
 SG_ F_Fahrwerk_02_Mmi : 55|1@1+ (1,0) [0|1] "" Vector__XXX
 SG_ F_Motor_03_Mmi : 56|1@1+ (1,0) [0|1] ""  Klima_PAG_PF
 SG_ F_Motor_07_Mmi : 57|1@1+ (1,0) [0|1] ""  Klima_PAG_PF
 SG_ F_Motor_15_PAG_Mmi : 60|1@1+ (1,0) [0|1] "" Vector__XXX
 SG_ F_Motor_02_Mmi : 61|1@1+ (1,0) [0|1] "" Vector__XXX
 SG_ F_Motor_Hybrid_01_Mmi : 62|1@1+ (1,0) [0|1] ""  ADR_PAG_X2
 SG_ F_Getriebe_07_PAG : 63|1@1+ (1,0) [0|1] ""  Klima_PAG_PF,Kombi_PAG_PF

BO_ 908 GW_Mmi_05_PAG: 8 GW_Routing_PAG_PF
 SG_ HAL_Warnungen : 2|2@1+ (1,0) [0|3] ""  Kombi_PAG_PF
 SG_ ESP_Querbeschleunigung_Roh : 16|9@1+ (0.01,-2.55) [-2.55|2.55] "Unit_ForceOfGravi"  ADR_PAG_X2,Kombi_PAG_PF
 SG_ ESP_Querbeschleunigung_Offset : 25|6@1+ (0.01,-0.3) [-0.3|0.31] "Unit_ForceOfGravi"  ADR_PAG_X2,Kombi_PAG_PF
 SG_ ESP_Eingriff : 36|1@1+ (1,0) [0|1] "" Vector__XXX
 SG_ ESP_Off_Lampe : 37|1@1+ (1,0) [0|1] ""  ADR_PAG_X2,Kombi_PAG_PF
 SG_ ESP_Rollenmodus : 39|1@1+ (1,0) [0|1] ""  Kombi_PAG_PF
 SG_ ESP_Stillstandsflag : 41|1@1+ (1,0) [0|1] ""  ADR_PAG_X2
 SG_ ESP_Autohold_aktiv : 43|1@1+ (1,0) [0|1] ""  Kombi_PAG_PF
 SG_ ESP_HDC_Standby : 49|1@1+ (1,0) [0|1] ""  Klima_PAG_PF
 SG_ F_ESP_05_Mmi : 56|1@1+ (1,0) [0|1] ""  Klima_PAG_PF,Kombi_PAG_PF
 SG_ F_ESP_01_Mmi : 57|1@1+ (1,0) [0|1] "" Vector__XXX
 SG_ F_ESP_04_Mmi : 58|1@1+ (1,0) [0|1] ""  ADR_PAG_X2,Kombi_PAG_PF
 SG_ F_ESP_02_Mmi : 59|1@1+ (1,0) [0|1] ""  ADR_PAG_X2
 SG_ F_ESP_11_Mmi : 60|1@1+ (1,0) [0|1] ""  Kombi_PAG_PF
 SG_ F_ESP_13_Mmi : 61|1@1+ (1,0) [0|1] ""  ADR_PAG_X2,Kombi_PAG_PF
 SG_ HAL_01_alt : 62|1@1+ (1,0) [0|1] ""  Kombi_PAG_PF

BO_ 1515 GW_Mmi_06_PAG: 8 GW_Routing_PAG_PF
 SG_ FS_MMB_storage : 0|4@1+ (1,0) [0|15] "" Vector__XXX
 SG_ FS_MMB_storage_beep : 4|1@1+ (1,0) [0|1] "" Vector__XXX
 SG_ FS_MMB_store : 5|1@1+ (1,0) [0|1] "" Vector__XXX
 SG_ FS_MMB_tipp : 6|1@1+ (1,0) [0|1] "" Vector__XXX
 SG_ FS_MMB_tast : 7|1@1+ (1,0) [0|1] "" Vector__XXX
 SG_ BFS_MMB_storage : 8|4@1+ (1,0) [0|15] "" Vector__XXX
 SG_ BFS_MMB_storage_beep : 12|1@1+ (1,0) [0|1] "" Vector__XXX
 SG_ BFS_MMB_store : 13|1@1+ (1,0) [0|1] "" Vector__XXX
 SG_ BFS_MMB_tipp : 14|1@1+ (1,0) [0|1] "" Vector__XXX
 SG_ BFS_MMB_tast : 15|1@1+ (1,0) [0|1] "" Vector__XXX
 SG_ BFS_MMB_store_LED_on : 17|1@1+ (1,0) [0|1] "" Vector__XXX
 SG_ LWI_Lenkradwinkel : 40|13@1+ (0.1,0) [0|800] "Unit_DegreOfArc"  ADR_PAG_X2,Klima_PAG_PF
 SG_ LWI_VZ_Lenkradwinkel : 53|1@1+ (1,0) [0|1] ""  ADR_PAG_X2,Klima_PAG_PF
 SG_ LWI_Sensorstatus : 54|1@1+ (1,0) [0|1] "" Vector__XXX
 SG_ LWI_QBit_Lenkradwinkel : 55|1@1+ (1,0) [0|1] "" Vector__XXX
 SG_ F_LWI_01_Mmi : 56|1@1+ (1,0) [0|1] ""  ADR_PAG_X2,Klima_PAG_PF
 SG_ F_Mem_BFS_01_Mmi : 57|1@1+ (1,0) [0|1] "" Vector__XXX
 SG_ F_Mem_FS_01_Mmi : 58|1@1+ (1,0) [0|1] "" Vector__XXX

BO_TX_BU_ 1603 : ADR_PAG_X2,Kombi_PAG_PF;
CM_ SG_ 899 CHA_Ziel_FahrPr_HAL "Anforderung Ziel-Fahrprogramm HAL (nähere Spezifikation siehe Charisma-LH PAG)";
CM_ SG_ 899 CHA_Ziel_FahrPr_BCM "Anforderung Ziel-Fahrprogramm BCM (nähere Spezifikation siehe Charisma-LH PAG)";
CM_ SG_ 899 CHA_Ziel_FahrPr_HAL_01 "Anforderung Ziel-Fahrprogramm Unterfunktion HAL_01 (nähere Spezifikation siehe Charisma-LH PAG)";
CM_ SG_ 899 CHA_Ziel_FahrPr_BMS "Anforderung Ziel-Fahrprogramm BMS (nähere Spezifikation siehe Charisma-LH PAG)";
CM_ SG_ 899 CHA_Ziel_FahrPr_ALR "Anforderung Ziel-Fahrprogramm-Allrad";
CM_ SG_ 899 CHA_Ziel_FahrPr_ESP "Anforderung Ziel-Fahrprogramm-ESP";
CM_ SG_ 899 CHA_Ziel_FahrPr_PDCC "Anforderung Ziel-Fahrprogramm-PDCC";
CM_ SG_ 899 CHA_Ziel_FahrPr_QUER "Anforderung Ziel-Fahrprogramm-Quersperre";
CM_ SG_ 899 CHA_Ziel_FahrPr_MO_01 "Anforderung Ziel-Fahrprogramm Unterfunktion MO_01 (nähere Spezifikation siehe Charisma-LH PAG)";
CM_ SG_ 899 CHA_Ziel_FahrPr_GE_01 "Anforderung Ziel-Fahrprogramm Unterfunktion GE_01 (nähere Spezifikation siehe Charisma-LH PAG)";
CM_ SG_ 899 CHA_Ziel_FahrPr_MO_02 "Anforderung Ziel-Fahrprogramm Unterfunktion MO_02 (nähere Spezifikation siehe Charisma-LH PAG)";
CM_ SG_ 899 CHA_Ziel_FahrPr_GE_02 "Anforderung Ziel-Fahrprogramm Unterfunktion GE_02 (nähere Spezifikation siehe Charisma-LH PAG)";
CM_ SG_ 899 CHA_Ziel_FahrPr_MO_03 "Anforderung Ziel-Fahrprogramm Unterfunktion MO_03 (nähere Spezifikation siehe Charisma-LH PAG)";
CM_ SG_ 899 CHA_Ziel_FahrPr_GE_03 "Anforderung Ziel-Fahrprogramm Unterfunktion GE_03 (nähere Spezifikation siehe Charisma-LH PAG)";
CM_ SG_ 899 CHA_Ziel_FahrPr_DR_01 "Anforderung Ziel-Fahrprogramm Unterfunktion DR_01 (nähere Spezifikation siehe Charisma-LH PAG)";
CM_ SG_ 899 CHA_Ziel_FahrPr_Lift "Anforderung Ziel-Fahrprogramm Lift (nähere Spezifikation siehe Charisma-LH PAG)";
CM_ SG_ 1335 ALR_Charisma_FahrPr "MLB: Aktuelles Fahrprogramm des Charisma-Teilnehmers (siehe Systemlastenheft Drive Select)
MQB: Istwert der Kennlinie (siehe Systemlastenheft MQB Charisma)";
CM_ SG_ 1335 ALR_Charisma_Status "Systemstatus des Charismateilnehmers

Wert 0x3 ist nur für Fahrzeuge ab MQB relevant
";
CM_ SG_ 1335 ALR_Charisma_Umschaltung "Erkennung  Umschaltaufforderung des Charisma-Teilnehmers";
CM_ SG_ 1335 Allrad_02_alt "Veraltet-Bit für die Signale:

Botschaft Charisma_06_PAG:
ALR_Charisma_FahrPr
ALR_Charisma_Status
ALR_Charisma_Umschaltung
";
CM_ SG_ 1335 ESP_Charisma_FahrPr "MLB: Aktuelles Fahrprogramm des Charisma-Teilnehmers (siehe Systemlastenheft Drive Select)
MQB: Istwert der Kennlinie (siehe Systemlastenheft MQB Charisma)

";
CM_ SG_ 1335 ESP_Charisma_Status "Systemstatus des Charismateilnehmers

Wert 0x3 ist nur für Fahrzeuge ab MQB relevant";
CM_ SG_ 1335 ESP_Charisma_Umschaltung "Erkennung  Umschaltaufforderung des Charisma-Teilnehmers";
CM_ SG_ 1335 ESP_11_alt "Veraltet-Bit für die Signale:

Botschaft Charisma_06_PAG:
ESP_Charisma_FahrPr
ESP_Charisma_Status
ESP_Charisma_Umschaltung
";
CM_ SG_ 1335 PDCC_Charisma_FahrPr "MLB: Aktuelles Fahrprogramm des Charisma-Teilnehmers (siehe Systemlastenheft Drive Select)
MQB: Istwert der Kennlinie (siehe Systemlastenheft MQB Charisma)

";
CM_ SG_ 1335 PDCC_Charisma_Status "Systemstatus des Charismateilnehmers

Wert 0x3 ist nur für Fahrzeuge ab MQB relevant";
CM_ SG_ 1335 PDCC_Charisma_Umschaltung "Erkennung  Umschaltaufforderung des Charisma-Teilnehmers";
CM_ SG_ 1335 PDCC_01_PAG_alt "Veraltet-Bit für die Signale:

Botschaft Charisma_06_PAG:
PDCC_Charisma_FahrPr
PDCC_Charisma_Status
PDCC_Charisma_Umschaltung
";
CM_ SG_ 1335 QUER_Charisma_FahrPr "MLB: Aktuelles Fahrprogramm des Charisma-Teilnehmers (siehe Systemlastenheft Drive Select)
MQB: Istwert der Kennlinie (siehe Systemlastenheft MQB Charisma)


";
CM_ SG_ 1335 QUER_Charisma_Status "Systemstatus des Charismateilnehmers

Wert 0x3 ist nur für Fahrzeuge ab MQB relevant
";
CM_ SG_ 1335 QUER_Charisma_Umschaltung "Erkennung Umschaltaufforderung des Charisma-Teilnehmers";
CM_ SG_ 1335 Quersperre_02_PAG_alt "Veraltet-Bit für die Signale:

Botschaft Charisma_06_PAG:
QUER_Charisma_FahrPr
QUER_Charisma_Status
QUER_Charisma_Umschaltung
";
CM_ SG_ 1335 HAL_Charisma_FahrPr "Rückmeldung des aktuellen Charisma-Status der HAL";
CM_ SG_ 1335 HAL_Charisma_Status "Rückmeldung an den Charisma-Master";
CM_ SG_ 1335 HAL_01_alt "Veraltet-Bit für die Signale:

Botschaft Charisma_06_PAG:
HAL_Charisma_FahrPr
HAL_Charisma_Status

Botschaft GW_Mmi_05_PAG:
HAL_Warnungen
";
CM_ SG_ 1335 Lift_Charisma_FahrPr "


";
CM_ SG_ 1335 Lift_Charisma_Status "Systemstatus des Charismateilnehmers

";
CM_ SG_ 1335 Lift_Charisma_Umschaltung "Erkennung Umschaltaufforderung des Charisma-Teilnehmers";
CM_ SG_ 1335 Lift_01_alt "Veraltet-Bit für die Signale:

Botschaft Charisma_06_PAG:
Lift_Charisma_FahrPr
Lift_Charisma_Status
Lift_Charisma_Umschaltung

Botschaft GW_Mmi_05_PAG:

";
CM_ SG_ 1714 DGN_Verlernzaehler "wrap around 254 --> 0";
CM_ SG_ 1714 KBI_Kilometerstand "Fehler wird ausgegeben, falls Kilometerstand nicht restaurierbar
";
CM_ SG_ 1714 UH_Monat "0x0D, 0xF =  Werte ungültig
0x0E = reserviert (nur VW)";
CM_ SG_ 1714 UH_Tag "0x0: reserviert bei VW";
CM_ SG_ 1714 UH_Stunde "0x18 - 0x1F = Werte ungültig";
CM_ SG_ 1714 UH_Minute "0x3C- 0x3f = Werte ungültig";
CM_ SG_ 1714 UH_Sekunde "0x3C- 0x3f = Werte ungültig";
CM_ SG_ 1714 Kombi_02_alt "Veraltet Bit für die Signale:

Botschaft Diagnose_01:
KBI_Kilometerstand

Botschaft Gateway_03:
KBI_Aussen_Temp_gef
KBI_QBit_Aussen_Temp_gef
KBI_Standzeit
KBI_Reset_Standzeit
";
CM_ SG_ 1714 Uhrzeit_01_alt "Veraltet Bit für die Signale:

Botschaft Diagnose_01:
UH_Jahr
UH_Monat
UH_Tag
UH_Stunde
UH_Minute
UH_Sekunde
";
CM_ SG_ 1009 GW_STH_Anf "Anforerung 'EIN/AUS' bzw. Wecken der Standheizung durch Gateway
";
CM_ SG_ 1009 FSAktivBit "Fehlerspeicheraktivierungsbit
";
CM_ BO_ 1603 "MLB 3Byte";
CM_ SG_ 1603 KBI_Einheit_Datum "Anzeigevariante des Datums";
CM_ SG_ 1603 KBI_Einheit_Druck "Einheit des Druckes";
CM_ SG_ 1603 KBI_Einheit_Streckenanz "Einheit der Streckenanzeige";
CM_ SG_ 1603 KBI_MFA_v_Einheit_02 "Einheit der Geschwindigkeit, die vom Fahrer im Car-Menü gewählt wurde. Veränderliche Grösse, im Gegensatz zur Einheit des Tachokranzes.

Redundant in der Einheiten_01 Botschaft definiert, um Konsistenz zur BAP-Festlegung zu haben.";
CM_ SG_ 1603 KBI_Einheit_Temp "Einheit der Temperatur";
CM_ SG_ 1603 KBI_Einheit_Uhrzeit "Anzeigevariante der Uhrzeit";
CM_ SG_ 1603 KBI_Einheit_Verbrauch "Einheit der Verbrauchs";
CM_ SG_ 1603 KBI_Einheit_Volumen "Einheit des Volumens";
CM_ SG_ 1603 KBI_Einheit_Verbrauch_elektr "Einheit elektrischer Verbrauch";
CM_ SG_ 1603 KBI_Einheit_Sprache "Siehe BAP-Datenfestlegung UnitMaster";
CM_ SG_ 781 EPB_Fehlerlampe_Gelb "Fehlerlampe für nicht liegenbleiberreleavante Fehler";
CM_ SG_ 781 EPB_Fehlerlampe_BKL "Die BKL dient als rote Fehlerlampe für die EPB. Sie wird vom EPB-SG aktiv ausgeschaltet.";
CM_ SG_ 781 EPB_Funktionslampe "Bit wird nur gesetzt, wenn volle Spannkraft auf beiden Seiten erreicht. PQ46: Bit wird gesetzt, wenn BKL direkt vom EPB-SG als Funktionslampe angesteuert wird.

Bei Audi: Rote Lampe (rotes P) im Kombiinstrument
";
CM_ SG_ 781 EPB_Texte "EPB-Texte für Kombi
0x9 bei Audi nicht bedient.
0xA - 0xF = tbd.";
CM_ SG_ 781 EPB_Akustik "Bit wird gesetzt, wenn bei v > 0 eine Fahreran-forderung schließen vorhanden ist (ECD angefordert). PQ46-Kombi sendet Warnton (600Hz) solange dieses Bit gesetzt ist.
Anzeige eines Warntextes
";
CM_ SG_ 781 EPB_Autoholdlampe "Autoholdlampe im Kombi, grünes P
";
CM_ SG_ 781 EPB_Bremsbelag_Warn "Mindestens ein Bremsbelag an der Hinterachse am Fahrzeug ist unter Minimum";
CM_ SG_ 256 ESP_01_CHK "Berechnung siehe Lastenheft 'Kommunikationsabsicherung für FlexRay und CAN'
Endwerte siehe 'Kommunikationsabsicherung für FlexRay und CAN / Anhang C: Tabelle S-PDU Kennungen'";
CM_ SG_ 256 ASR_Moment_langsam "Achtung:
Einheitenloser CAN-Wert.
Faktor in MO_Faktor_Momente in Motor_Code_01 beachten!

Langsame reduzierende (ASR) Momentenanforderung an der Motor";
CM_ SG_ 256 ASR_MSR_Moment_schnell "Achtung:
Einheitenloser CAN-Wert.
Faktor in MO_Faktor_Momente in Motor_Code_01 beachten!

Schnelle reduzierende (ASR) oder erhöhende (MSR) Momentanforderung an den Motor, Eingriffsart wird über das Signal 'ASR_MSR_Eingriffsart' qualifiziert";
CM_ SG_ 256 ESP_v_Signal "Geschwindigkeitssignal vom ABS/ASR oder ESP. Mittelwert der angetriebenen Räder.
Bei MSR oder ABS Eingriffen wird die ABS-Referenzgeschwindigkeit für >= 200ms eingespiegelt (Zeit wird mit Aktiv-Flanke der Funktionsbits getriggert)

MQB: Bei Frontantrie";
CM_ SG_ 256 ASR_Tastung_passiv "ASR deaktiviert oder Schwellen geändert (projektabhängig)
Weiterführende Informationen im Lastenheft spezifiziert und in der entsprechenden Fachabteilung zu erfragen.
";
CM_ SG_ 256 ESP_Tastung_passiv "ESP deaktiviert oder Schwellen geändert (projektabhängig)
Weiterführende Informationen im Lastenheft spezifiziert und in der entsprechenden Fachabteilung zu erfragen.";
CM_ SG_ 256 ESP_Systemstatus "Fehler steht für Stillegung ESP mit Fehlereintrag.

MLB: Flag wird bei Unterspannung im Stand bis einmalig 6km/h (AU48x) oder 10 km/h (AU641, AU57x) überschritten nicht gesetzt (Ausblendung Startvorgang)
Im AU64x, AU57x gilt ESP D4 Funktionsanforderung";
CM_ SG_ 256 ASR_Schalteingriff "Wunsch an das Getriebe während einer ASR Regelung

MLB: Es wird nur 0x0 und 0x1 genutzt

";
CM_ SG_ 256 OBD_Schlechtweg "Für Ausblendung der Zündaussetzererkennung im Motorsteuergerät (Otto). Bit wird gesetzt, wenn Rad-Drehbeschleunigung im ESP > Grenzwert ist. Vorteil gegenüber Radgeschwindigkeiten, dass ESP alle 2 ms dynamisch die Rad-Drehbeschleunigung errechnet und dem ";
CM_ SG_ 256 ESP_QBit_v_Signal "Geschwindigkeit wird vom ABS/ASR oder ESP aus Ersatzwerten errechnet, wenn Bit gesetzt ist. Güte des Signals ist verändert.";
CM_ SG_ 256 ABS_Bremsung "Antiblockiersystem, Bit zeigt auch Druckabbau an (z.B. ESP hat zuviel Druck aufgebaut oder ungebremste Regelung auf Bahnübergang)
Weiterführende Informationen im Lastenheft spezifiziert und in der entsprechenden Fachabteilung zu erfragen.";
CM_ SG_ 256 ASR_Anf "MLB: Die Momentenanforderung 'ASR_MSR_Moment_schnell' und 'ASR_Moment_langsam' sind auszuführen
MQB: Die Momentenanforderung 'BR_Eingriffsmoment' ist auszuführen";
CM_ SG_ 256 MSR_Anf "MLB: Die Momentenanforderung 'ASR_MSR_Moment_schnell' ist auszuführen.
MQB: Die Momentenanforderung 'BR_Eingriffsmoment' ist auszuführen";
CM_ SG_ 256 EBV_Eingriff "Elektronische Bremskraftverteilung, aktueller Eingriff (Druckhalten, Druckabbau)

Im MLB: kein ABS / ESP-Eingriff ???";
CM_ SG_ 256 EDS_Eingriff "Elektronische Differentialsperre";
CM_ SG_ 256 ESP_Eingriff "Eingriff des Fahrdynamikreglers";
CM_ SG_ 256 ESP_ASP "MLB: Anhaenger-Stabilisierungs-Programm
MQB: Gespannstabilisierung";
CM_ SG_ 257 ESP_02_CHK "Berechnung siehe Lastenheft 'Kommunikationsabsicherung für FlexRay und CAN'
Endwerte siehe 'Kommunikationsabsicherung für FlexRay und CAN / Anhang C: Tabelle S-PDU Kennungen'";
CM_ SG_ 257 ESP_QBit_Gierrate "QBit der Gierrate. Gesetzt bei Ersatzwert, Init oder Fehler. 
";
CM_ SG_ 257 ESP_QBit_Laengsbeschl "QBit der Längsbeschleunigung. Gesetzt bei Ersatzwert, Init oder Fehler. 
";
CM_ SG_ 257 ESP_QBit_Querb "QBit der Querbeschleunigung. Gesetzt bei Ersatzwert, Init oder Fehler. ";
CM_ SG_ 257 ESP_Stillstandsflag "Bei RB-Projekten wird das Stillstandsflag gesetzt, wenn der absolute Stillstand der Raddrehzahlsensoren erkannt wurde, d.h. kein Zahn bewegt sich mehr. Dieses Bit wird bspw. im MOST für TV-Tuner-Abschaltung Australien verwendet, d.h. leichte Erschütterung";
CM_ SG_ 257 ESP_Querbeschleunigung "Beschleunigungswert in y-Achse

MLB: Gemessener Wert
0xFF = Fehler (wie bereits im Wertebereich spezifizert)
Bei ESP-Abschaltung durch modellgestützte Überwachung wird das Signal weiterhin ausgegeben.
Im AU64x und AU57x erfolgt die Bereitstellung der";
CM_ SG_ 257 ESP_Laengsbeschl "Beschleunigungswert in x-Achse

MLB: Im AU64x und AU57x erfolgt die Bereitstellung der Sensorwerte durch SARA-SG! Im AU64x und AU57x wird bei ESP-Abschaltung durch modellgestützte Überwachung das Signal weiterhin ausgegeben.

MQB: Sensorrohwert Längsb";
CM_ SG_ 257 ESP_Verteil_Wankmom "Anforderung einer Wankmomentenverteilung an CDC (Exklusivnutzung!)

-1...-0,1 = Fahrzeug untersteuernd (Anforderung Dämpfer vorne weich / hinten hart)
0 = Fahrzeug neutral, keine Dämpferansteuerung erforderlich
+0,1...+1 = Fahrzeug übersteuernd: Anfor";
CM_ SG_ 257 ESP_QBit_Anf_Vert_Wank "QBit der Wankmomentenverteilung. Gesetzt bei Ersatzwert, Init oder Fehler.";
CM_ SG_ 257 ESP_Gierrate "Winkelgeschwindigkeit um die z-Achse, ESP_VZ_Gierrate & ESP_QBit_Gierrate beachten !!!

MLB: gemessener Wert
tatsächliche Auflösung Bosch ESP: 0,27 Grad/s

Ab AU64x Auflösung wie die tatsächliche Skalierung 0,01. Im AU64x und AU57x wird bei ESP-Absch";
CM_ SG_ 257 ESP_VZ_Gierrate "Vorzeichen der Gierrate";
CM_ SG_ 257 ESP_Notbremsanzeige "ABS/ASR oder ESP hat Notbremssituation erkannt.
Weiterführende Informationen im Lastenheft spezifiziert und in der entsprechenden Fachabteilung zu erfragen.

";
CM_ SG_ 257 ESP_SpannungsAnf "Die Rekuperation kann mit der Anforderung einer höheren Spannung eingeschränkt werden.";
CM_ SG_ 257 ESP_PLA_Abbruch "Wenn der Bremseingriff abgebrochen wurde, wird in diesem Signal der Grund des Abbruchs dargestellt.
Dies ist nur gültig, wenn der Status ESP_Status_ESP_PLA = '0xA' ist.";
CM_ SG_ 257 ESP_Status_ESP_PLA "Zustand der Statusmaschine der Bremse für die korrespondierende Statusmaschine in dem PLA-SG";
CM_ SG_ 259 ESP_03_CHK "Berechnung siehe Lastenheft 'Kommunikationsabsicherung für FlexRay und CAN'
Endwerte siehe 'Kommunikationsabsicherung für FlexRay und CAN / Anhang C: Tabelle S-PDU Kennungen'";
CM_ SG_ 259 ESP_VL_FR "Fahrtrichtungserkennung Rad Vorne Links
";
CM_ SG_ 259 ESP_VR_FR "Fahrtrichtungserkennung Rad Vorne Rechts

";
CM_ SG_ 259 ESP_HL_FR "Fahrtrichtungserkennung Rad Hinten Links
";
CM_ SG_ 259 ESP_HR_FR "Fahrtrichtungserkennung Rad Hinten Rechts
";
CM_ SG_ 259 ESP_VL_Radgeschw "Radgeschwindigkeit vorne links";
CM_ SG_ 259 ESP_VR_Radgeschw "Radgeschwindigkeit vorne rechts";
CM_ SG_ 259 ESP_HL_Radgeschw "Radgeschwindigkeit hinten links";
CM_ SG_ 259 ESP_HR_Radgeschw "Radgeschwindigkeit hinten rechts";
CM_ BO_ 776 "im B8 mit 50ms
";
CM_ SG_ 776 ESP_Meldungen "Verwendung/Bedienung ab D4
ESP sendet im Hinweis- /Störungsfall an das Kombi Informationen zum Anzeigen (Text + Akustik)

- die Signalinhalte wurden aus dem Signal ESP_Textanzeigen_02 (Wert 0x10, 0xE, 0x9) extrahiert 
und werden zukünftig über dieses ";
CM_ SG_ 776 ESP_HDC_FktLampe "Funktionslampe Bergabfahrassistent.
(Sender blinkt mit dem Bit 3,3Hz)";
CM_ SG_ 776 ESP_Lampe "Zustand der Fahrdynamikregelungslampe (MLB: ASR und/oder ESP, MQB: nur ESP)

Weiterführende Informationen im Lastenheft spezifiziert und in der entsprechenden Fachabteilung zu erfragen.";
CM_ SG_ 776 ABS_Lampe "Sicherheitswarnlampe

Weiterführende Informationen im Lastenheft spezifiziert und in der entsprechenden Fachabteilung zu erfragen.";
CM_ SG_ 776 BK_Lampe "Sicherheitswarnlampe signalisiert EBV-Ausfall

MLB: 
Blinktakt wird vom Kombi generiert. Separate Bremskontroll-Lampe wird als Sicherheitswarnlampe aufgeprüft.

MQB: wird auch bei HBV-Ausfall verwendet

Weiterführende Informationen im Lastenheft sp";
CM_ SG_ 776 ESP_Akustik "Akustik der Fahrdynamikregelung im Kombiinstrument

Im B8 gilt LAH 8T0.907.B.pdf - Warn-Anzeigekonzept Bremssysteme

Im D4 gilt die Spezifikation Warn-Anzeige-LH D4

Im MQB wird dieses Signal nicht unterstützt!
";
CM_ SG_ 776 ESP_Diagnose "MLB: Nach Diagnoseende wird ein SW-Reset ausgelöst welcher einen Kommunikatiosausfall für max. 150ms verursacht. Dies ist bei SG mit verschärfter Timeoutüberwachung (nicht nach Konzern-LH) zu beachten.

MQB: Weiterführende Informationen im Lastenheft sp";
CM_ SG_ 776 ESP_Textanzeigen_02 "Textanzeigen der Fahrdynamikregelung im Kombiinstrument

Weiterführende Informationen im Lastenheft spezifiziert und in der entsprechenden Fachabteilung zu erfragen.

Nur im VW526 werden die Werte 0x15 und 0x17 für die Verlassenswarnung (1. Anlauf) ge";
CM_ SG_ 776 ESP_Off_Lampe "Bit zur Ansteuerung der separaten ESP-off-Lampe im Kombi (Gesetzesforderung USA)

MLB:
Verwendung/Bedienung ab D4";
CM_ SG_ 776 ESP_m_Raddrehz "Radumdrehungen pro Sekunde sind Eingangsgröße für die Geschwindigkeitsberechnung im Kombi. Aus dieser Raddrehzahl und dem Radumfang wird die Fahrzeuggeschwindigkeit errechnet.

MLB: Exklusiver Empfänger ist das Kombiinstrument!
MQB: Bei Frontantrieb un";
CM_ SG_ 776 ESP_ASR_Lampe "Signal wir nur im B8/Q5 verwendet um den Fehlerzustand des ESPs darzustellen.
In allen nachfolge Projekten werden für diese Funktion die alten Signale verwendet und dieses Signal ist ungültig. 

ESP_ASR_Lampe == 0
kein Stabilisierungseingriff, kein Fe";
CM_ SG_ 776 ESP_Wegimp_VA "Weiterführende Informationen im Lastenheft spezifiziert und in der entsprechenden Fachabteilung zu erfragen.

MLB: Die Wegimpulse Vorderachse sind die gemittelten Werte (reine mathematische Operation: Addition und Division durch zwei, keine Filterung) d";
CM_ SG_ 776 ESP_Fehlerstatus_Wegimp "Weiterführende Informationen im Lastenheft spezifiziert und in der entsprechenden Fachabteilung zu erfragen.

MLB: Fehler wird gesetzt, wenn beide ESP-Drehzahlfühler an der Vorderachse defekt sind.

MQB: Fehler wird gesetzt, wenn beide Raddrehzahlfühl";
CM_ SG_ 776 ESP_Wegimp_Ueberlauf "Der Wegimpulszähler ist pro Zündungslauf mindestens einmal übergelaufen

Weiterführende Informationen im Lastenheft spezifiziert und in der entsprechenden Fachabteilung zu erfragen.";
CM_ SG_ 776 ESP_QBit_Wegimp_VA "Gesetzt bei Ersatzwert, Init oder Fehler.";
CM_ SG_ 776 ESP_Displaywarnungen "Prio1-Warnungen
Automatisch gekoppelt an diese Bremsenwarnung ist ein dreimaliger Warnton, der durch das Kombi selbstständig angesteuert wird, sobald eines der belegten Bits gesetzt ist (nicht VW526!).

Im B8 gilt LAH 8T0.907.B.pdf - Warn-Anzeigekonzep";
CM_ SG_ 776 ESP_HDC_Regelgeschw "Verwendung/Bedienung nur im AU57x Allroad:
HDC-Geschwindigkeit
Dient der Anzeige der HDC-Geschwindigkeit und eines Bergabfahrsymbols im Kombi.
HDC-Standby wird gesetzt sobald der Fahrer den HDC-Taster aktiviert hat.
Bei HDC-Off oder während der Initia";
CM_ SG_ 776 ESP_BKV_Warnung "Verwendung/Bedienung ab D4
ESP sendet im Hinweis- /Störungsfall an das Kombi Informationen zum Anzeigen (Text + Akustik)

- der Signalwert 1 wurde aus dem Signal ESP_Textanzeigen_02 (Wert 0xA) extrahiert und soll 
zukünftig über dieses Signal angezeig";
CM_ SG_ 776 ESP_Zaehnezahl "Konstanter Wert der Zähnezahl des verwendeten Impulsrades wird ausgegeben, jeder Empfänger der Wegimpulse muss die Zähnezahl einlesen, um eine volle Umdrehung des Rades zu erkennen. 

Weiterführende Informationen im Lastenheft spezifiziert und in der en";
CM_ SG_ 278 ESP_10_CRC "Für MLB:
'Berechnung siehe Lastenheft 'Kommunikationsabsicherung für FlexRay und CAN''

Ab MQB und MLBevo:
'Berechnung siehe Lastenheft 'End-to-End Kommunikationsabsicherung''

Endwerte siehe Begleitdokument 'S-PDU Kennungsfolgen'

Wird im Projekt";
CM_ SG_ 278 ESP_10_BZ "MQB: ACHTUNG: Systematische Botschaftszählersprünge im I- und KCAN durch asynchrones Routing der ESP_10 (Originalsender 20ms zyklisch) vom FCAN

Wird im Projekt D4 und D4Hybrid nicht verwendet!  Wird im D4 PA verwendet";
CM_ SG_ 278 ESP_QBit_Wegimpuls_VL "Qualifizierungsbit Wegimpulszähler VL

Wird im Projekt D4 und D4Hybrid nicht verwendet!  Wird im D4 PA verwendet";
CM_ SG_ 278 ESP_QBit_Wegimpuls_VR "Qualifizierungsbit Wegimpulszähler VR

Wird im Projekt D4 und D4Hybrid nicht verwendet!  Wird im D4 PA verwendet";
CM_ SG_ 278 ESP_QBit_Wegimpuls_HL "Qualifizierungsbit Wegimpulszähler HL

Wird im Projekt D4 und D4Hybrid nicht verwendet!  Wird im D4 PA verwendet";
CM_ SG_ 278 ESP_QBit_Wegimpuls_HR "Qualifizierungsbit Wegimpulszähler HR

Wird im Projekt D4 und D4Hybrid nicht verwendet!  Wird im D4 PA verwendet";
CM_ SG_ 278 ESP_Wegimpuls_VL "Wegimpulszähler VL.
Anzahl der Wegimpulse Vorderrad links (steigende und fallende Flanke)
Zähler läuft grundsätzlich vorwärts, auch bei Rückwärtsfahrt.
Nach SG-Reset ist immer, ohne Ausnahme, 1mal der Init Wert 1021 zu senden.

Wird im Projekt D4 und";
CM_ SG_ 278 ESP_Wegimpuls_VR "Wegimpulszähler VR.
Anzahl der Wegimpulse Vorderrad rechts (steigende und fallende Flanke)
Zähler läuft grundsätzlich vorwärts, auch bei Rückwärtsfahrt.
Nach SG-Reset ist immer, ohne Ausnahme, 1mal der Init Wert 1021 zu senden.

Wird im Projekt D4 un";
CM_ SG_ 278 ESP_Wegimpuls_HL "Wegimpulszähler HL.
Anzahl der Wegimpulse Hinterrad links (steigende und fallende Flanke)
Zähler läuft grundsätzlich vorwärts, auch bei Rückwärtsfahrt.
Nach SG-Reset ist immer, ohne Ausnahme, 1mal der Init Wert 1021 zu senden.

Wird im Projekt D4 und";
CM_ SG_ 278 ESP_Wegimpuls_HR "Wegimpulszähler HR.
Anzahl der Wegimpulse Hinterrad rechts (steigende und fallende Flanke)
Zähler läuft grundsätzlich vorwärts, auch bei Rückwärtsfahrt.
Nach SG-Reset ist immer, ohne Ausnahme, 1mal der Init Wert 1021 zu senden.

Wird im Projekt D4 un";
CM_ SG_ 278 ESP_VL_Fahrtrichtung "Drehrichtung Rad VL

Weiterführende Informationen im Lastenheft spezifiziert und in der entsprechenden Fachabteilung zu erfragen.

Wird im Projekt D4 und D4Hybrid nicht verwendet!  Wird im D4 PA verwendet";
CM_ SG_ 278 ESP_VR_Fahrtrichtung "Drehrichtung Rad VR

Weiterführende Informationen im Lastenheft spezifiziert und in der entsprechenden Fachabteilung zu erfragen.

Wird im Projekt D4 und D4Hybrid nicht verwendet!  Wird im D4 PA verwendet";
CM_ SG_ 278 ESP_HL_Fahrtrichtung "Drehrichtung Rad HL

Weiterführende Informationen im Lastenheft spezifiziert und in der entsprechenden Fachabteilung zu erfragen.

Wird im Projekt D4 und D4Hybrid nicht verwendet!  Wird im D4 PA verwendet";
CM_ SG_ 278 ESP_HR_Fahrtrichtung "Drehrichtung Rad HR

Weiterführende Informationen im Lastenheft spezifiziert und in der entsprechenden Fachabteilung zu erfragen.

Wird im Projekt D4 und D4Hybrid nicht verwendet!  Wird im D4 PA verwendet";
CM_ BO_ 963 "Schnelle Gateway-Botschaft für schnelle Größen aus dem High-Speed";
CM_ SG_ 963 Motor_03_alt "Veraltet Bit für die Signale:

Botschaft Gateway_01:
MO_QBit_Fahrer_bremst
MO_Motor_laeuft
MO_Drehzahl_01
MO_BLS
MO_Fahrer_bremst
MO_Kuppl_schalter
MO_Interlock

Botschaft Gateway_09:
MO_Drehzahl_01
";
CM_ SG_ 963 Getriebe_03_alt "Veraltet Bit für die Signale:

Botschaft Gateway_01:
GE_Waehlhebel
";
CM_ SG_ 963 ESP_02_alt "Veraltet Bit für die Signale:

Botschaft Gateway_01:
ESP_Notbremsanzeige

Botschaft Gateway_02:
ESP_Stillstandsflag

";
CM_ SG_ 963 Motor_05_alt "Veraltet-Bit für die Signale:

Botschaft Gateway_01:
MO_Anf_KL75
MO_Verbot_EKP
MO_Anf_Pruefimpuls
MO_Klima_Eingr
MO_Aussp_Anlass
MO_Freig_Anlass

Botschaft Gateway_03:
MO_EKlKomLeiRed

Botschaft Gateway_05:
MO_Handshake_STH
MO_Freig_Reku
";
CM_ SG_ 963 LWR_AFS_01_alt "Veraltet-Bit für die Signale:

Botschaft Gateway_01:
LWR_Touristenmodus_aktiv

Botschaft Gateway_02:
AFS_Allwetterlicht
AFS_Abbiegelicht_li_Anf
AFS_Abbiegelicht_re_Anf
AFS_Abbiegelicht_Dimm_Anf
AFS_Verfuegbarkeit_GLW
AFS_Status_Adaptive_LV
AFS";
CM_ SG_ 963 EPB_01_alt "Veraltet-Bit für die Signale:

Botschaft Gateway_01:
EPB_Status
EPB_BCM2_Motor_Wakeup

Botschaft Gateway_03:
EPB_QBit_Pedalweg_Kuppl
EPB_Pedalweg_Kuppl

Botschaft Gateway_71:
EPB_Status
EPB_BCM2_Motor_Wakeup
EPB_QBit_Pedalweg_Kuppl
EPB_Pedal";
CM_ SG_ 963 ESP_05_alt "Veraltet-Bit für die Signale:

Botschaft Gateway_01:
ECD_Bremslicht

Botschaft Gateway_04:
ESP_HDC_Standby

Botschaft Gateway_71:
ECD_Bremslicht";
CM_ SG_ 963 ESP_01_alt "Veraltet-Bit für die Signale:

Botschaft Gateway_01:
ESP_v_Signal
ESP_QBit_v_Signal

Botschaft Gateway_09:
ESP_v_Signal
";
CM_ SG_ 963 ESP_v_Signal "Geschwindigkeitssignal vom ABS/ASR oder ESP. Mittelwert der angetriebenen Räder.
Bei MSR oder ABS Eingriffen wird die ABS-Referenzgeschwindigkeit für >= 200ms eingespiegelt (Zeit wird mit Aktiv-Flanke der Funktionsbits getriggert)

MQB: Bei Frontantrie";
CM_ SG_ 963 ESP_Notbremsanzeige "ABS/ASR oder ESP hat Notbremssituation erkannt.
Weiterführende Informationen im Lastenheft spezifiziert und in der entsprechenden Fachabteilung zu erfragen.

";
CM_ SG_ 963 ECD_Bremslicht "Bremslichtansteuerung durch ECD-Funktion";
CM_ SG_ 963 EPB_Status "Gibt den Zustand der EPB-Aktuatoren an.

Nur VW526/PAG E2: Wert 0x3 bedeutet 'unbekannt'

";
CM_ SG_ 963 MO_Anf_KL75 "Information wann die Kl. 75 während des Startvorgangs abgeschaltet werden soll. Umsetzung durch BCM2.";
CM_ SG_ 963 MO_QBit_Fahrer_bremst "AUDI D4: Zykluszeit: 10ms (siehe Zykluszeit schnell/Cycletime Fast)

Achtung:
Reduktion der Zykluszeit Motor_03 auf 10ms geplant.
Projektabhängig soll künftig mit 10ms gesendet werden.
Empfänger die in weiteren Konzern-Projekten eingesetzt werden müs";
CM_ SG_ 963 EPB_BCM2_Motor_Wakeup "EPB setzt dieses Bit, wenn EPB ein Nachwecken des ACAN fordert. Die Wakeup-Ursache des Car-Wakeup wird im NM high von den SG nicht ausgewertet, weswegen die Car-Wakeup-Information in einer konventionellen Applikationsbotschaft zum BCM2 gesendet werden. Da";
CM_ SG_ 963 ESP_QBit_v_Signal "Geschwindigkeit wird vom ABS/ASR oder ESP aus Ersatzwerten errechnet, wenn Bit gesetzt ist. Güte des Signals ist verändert.";
CM_ SG_ 963 GE_Waehlhebel "Fahrprogramm des Getriebes
0xD: Bedienung AL ab D4";
CM_ SG_ 963 MO_Motor_laeuft "Das Motorsteuergerät gibt die Information aus, ab wann der Motor verbrennungsbedingt autark läuft und durch zuschaltbare Nebenaggregate mechanisch belastbar ist (z.B. durch Generator, Klimakompressor, etc.).

Die 'Motor läuft' Information wird ausgegebe";
CM_ SG_ 963 MO_Verbot_EKP "Es gilt: Signalspec MO_Verbot_EKP V1.1

MSG sendet Verbot der EKP-Ansteuerung an das BCM";
CM_ SG_ 963 MO_Anf_Pruefimpuls "Es gilt: Signalspec MO_Anf_Pruefimpuls v1.1

Anforderung des MSG an das BCM  zum Senden eines Prüfimpulses zur Diagnose der Wakeup-Leitung auf Dauerlow";
CM_ SG_ 963 LWR_Touristenmodus_aktiv "Über MMI sendet BCM1 eine Anforderung Touristenmodus an die LWR. Diese sendet als Rückmeldung an BCM1, dass der Touristenmodus aktiv geschaltet wurde";
CM_ SG_ 963 MO_Drehzahl_01 "Im Fehlerfall wird die Motordrehzahl über die Nockenwellendrehzahl als Ersatzgrösse ausgegeben

Bei Parallelhybrid: Getriebeeingangsdrehzahl (=E-Maschinen Drehzahl)";
CM_ SG_ 963 MO_Klima_Eingr "Eingriffe des Motor bei der Klima";
CM_ SG_ 963 MO_BLS "AUDI D4: Zykluszeit: 10ms (siehe Zykluszeit schnell/Cycletime Fast)

Ungefiltertes Rohsignal des Bremslichtschalters, nur wenn HW-Eingang bestückt und ausgewertet wird. Bei Motoren ohne genutzten HW-Eingang wird kein Ersatzwert (bspw. SW-Signal über CAN";
CM_ SG_ 963 MO_Fahrer_bremst "AUDI D4: Zykluszeit: 10ms (siehe Zykluszeit schnell/Cycletime Fast)

Redundante Bremsinformation vom Motor. Im B8 wird in diesem Bit der Wert der ESP-CAN-Information 'ESP_Fahrer_bremst' ausgegeben.

Achtung:
Reduktion der Zykluszeit Motor_03 auf 10ms";
CM_ SG_ 963 MO_Aussp_Anlass "Das Signal zeigt an, ob die Wiederholstartsperre aktiv ist. D. h. eine Ansteuerung des Anlassers wird auch bei erfüllten Startvoraussetzungen (HS: Interlock betätigt bzw. AT: P/N eingelegt und Bremse betätigt) nicht erfolgen.";
CM_ SG_ 963 MO_Freig_Anlass "Bit wird gesetzt, wenn der Motor beim Automatikstart gestartet werden darf (Motorstillstand, Emissionsmaßnahmen sind erfüllt).";
CM_ SG_ 963 MO_Kuppl_schalter "Das Motorsteuergerät gibt die Information aus, ab wann der Kupplungsschalter durch das Motorsteuergerät als getreten gesehen wird";
CM_ SG_ 963 MO_Interlock "Das Motorsteuergerät gibt die Information aus, ab wann der Kupplungsschalter durch das Motorsteuergerät als getreten gesehen wird.
Bei Systemen für Start Stopp muss das Interlocksignal für einen Start durch das MSG generiert werden, sobald der Schalthebe";
CM_ BO_ 1643 "Langsame Gateway-Botschaft für Konstanten und Temperaturen";
CM_ SG_ 1643 Motor_07_alt "Veraltet Bit für die Signale:

Botschaft Gateway_03:
MO_Kuehlmittel_Temp
MO_Kennfeldk
MO_Absperrventil_oeffnen";
CM_ SG_ 1643 Motor_Code_01_alt "Veraltet Bit für die Signale:

Botschaft Gateway_03:
MO_Kraftstoffart
";
CM_ SG_ 1643 Kombi_02_alt "Veraltet Bit für die Signale:

Botschaft Diagnose_01:
KBI_Kilometerstand

Botschaft Gateway_03:
KBI_Aussen_Temp_gef
KBI_QBit_Aussen_Temp_gef
KBI_Standzeit
KBI_Reset_Standzeit
";
CM_ SG_ 1643 Telefon_01_alt "Veraltet Bit für die Signale:

Botschaft Gateway_03:
TF_Phone_mute";
CM_ SG_ 1643 EPB_01_alt "Veraltet-Bit für die Signale:

Botschaft Gateway_01:
EPB_Status
EPB_BCM2_Motor_Wakeup

Botschaft Gateway_03:
EPB_QBit_Pedalweg_Kuppl
EPB_Pedalweg_Kuppl

Botschaft Gateway_71:
EPB_Status
EPB_BCM2_Motor_Wakeup
EPB_QBit_Pedalweg_Kuppl
EPB_Pedal";
CM_ SG_ 1643 Motor_05_alt "Veraltet-Bit für die Signale:

Botschaft Gateway_01:
MO_Anf_KL75
MO_Verbot_EKP
MO_Anf_Pruefimpuls
MO_Klima_Eingr
MO_Aussp_Anlass
MO_Freig_Anlass

Botschaft Gateway_03:
MO_EKlKomLeiRed

Botschaft Gateway_05:
MO_Handshake_STH
MO_Freig_Reku
";
CM_ SG_ 1643 Motor_06_alt "Veraltet-Bit für die Signale:

Botschaft Gateway_03:
MO_HYB_Fahrbereitschaft

Botschaft Gateway_07:
MO_HYB_Fahrbereitschaft

Botschaft Gateway_10:
WIV_Unterfuell_Warn
WIV_Oelstand_nicht_vorhanden
WIV_Oil_ok
WIV_Check_Oil
WIV_Oelmenge
WIV_nic";
CM_ SG_ 1643 MO_Kuehlmittel_Temp "Kuehlmitteltemperatur";
CM_ SG_ 1643 MO_Kraftstoffart "Primärkraftstoff zum Antrieb des Fahrzeugs";
CM_ SG_ 1643 MO_Kennfeldk "Die Kennfeldkühlung ist in diesem Fahrzeug verbaut und hat keinen Systemfehler";
CM_ SG_ 1643 KBI_QBit_Aussen_Temp_gef "0x0 = gültiger Wert
0x1 = Ersatz-, Init- oder Fehlerwert";
CM_ SG_ 1643 MO_Absperrventil_oeffnen "Signal an Klima-SG das Absperrrventil anzusteuern. Ab D4 auch 0x3 Ventil_schließen.

Im MQB wird hier der Soll-Status des Absperrventils ausgegeben.
Achtung: bei z. B. klemmendem Ventil entspricht das Signal nicht dem tatsächlichen Status!";
CM_ SG_ 1643 KBI_Standzeit "Low Byte 4, High Byte 5;
Standzeit in 4 Sekunden Auflösung; mit diesen 15 Bits läßt sich eine Zeit bis 36 Stunden, 24 Minuten und 28 Sekunden darstellen; 
Der Standzeitzähler wird mit KL15_Aus gestartet, er bleibt 2 Minuten vor einem Überlauf stehen, di";
CM_ SG_ 1643 TF_Phone_mute "Request to mute audio
0 = Audio active 
1 = Mute (TF_Mute_Msg_Code tells the reason) 
";
CM_ SG_ 1643 TF_Mute_Msg_Code "Tells the mute reason
0 = Phonecall (Telephone voive)
1 = Speech Recognition active (SDS active e.g. voice prompts)
2 = Emergency Call
3 = beep-signal (Signal tone)
4 = Operator Call
5 = Ringing
6 = Phonecall wideband voice
    (e.g. UMTS min 100H";
CM_ SG_ 1643 MO_HYB_Fahrbereitschaft "Signal steuert u.a. in der Lenkhilfe zusammen mit weiteren Informationen den Modewechsel in den 'Drivemode'
Grüne Anzeige im Kombiinstrument zur Signalisierung der Bereitschaft des Hybridsystems.";
CM_ SG_ 1643 MO_EKlKomLeiRed "Anforderung an die Klimasteuerung, die Leistungsaufnahme des E-Kompressors bei schlechtem SOC und in bestimmten Fahrsituationen zu begrenzen. (Das bereits bestehende Signal 'Klimakompressor aus' als stets umzusetzende Anforderung bleibt unverändert besteh";
CM_ SG_ 1643 EPB_Pedalweg_Kuppl "Signal entspricht Tastverhältnis des PWM. Gesamtweg Kupplungspedal 10% bis 90%, damit zu erwartende Werte 25 bis 225. 25 bei Kupplungspedal nicht getreten, 225 bei Kupplungspedal voll durchgetreten.
2% Toleranz wird im Wertebereich ermöglicht (8%-92%).
";
CM_ BO_ 924 "
Botschaft für Antriebs- und Fahrwerks-/Kombi-CAN";
CM_ SG_ 924 BCM1_02_alt "Veraltet Bit für die Signale:

Botschaft Gateway_05:
BCM1_MH_WIV_Schalter
BCM1_Oeldruck_Schalter
BCM1_Oeldruck_Schalter_2

Botschaft Gateway_11:
LV_Abblendlicht_Anzeige
LV_Abblendlicht_li_def
LV_Abblendlicht_re_def

Botschaft Gateway_07:
LV_F";
CM_ SG_ 924 Wischer_01_alt "Veraltet Bit für die Signale:

Botschaft Gateway_04:
Wischer_vorne_defekt

Botschaft Gateway_05:
Wischer_vorne_aktiv

Botschaft Gateway_07:
Wischer_vorne_aktiv

Botschaft Gateway_72:
Wischer_vorne_aktiv
Waschen_vorne_aktiv
WWSs_01_alt";
CM_ SG_ 924 Klima_02_alt "Veraltet Bit für die Signale:

Botschaft Gateway_05:
KL_Zuheizer_Freigabe
KL_HSH_ein_Soll 

Botschaft Gateway_09:
KL_I_Geblaese";
CM_ SG_ 924 BCM1_01_alt "Veraltet Bit für die Signale:

Botschaft Gateway_04:
BCM1_Charisma_Text_1
BCM1_Charisma_Text_2

Botschaft Gateway_05:
BCM1_Rueckfahrlicht_Schalter
BCM1_Vorwaertsgang_eingelegt
BCM1_RFahrlicht_Fzg_Anf
BCM1_Schalter_StartStopp

Botschaft Gateway";
CM_ SG_ 924 ESP_07_alt "Veraltet Bit für die Signale:

Botschaft Gateway_05:
ESP_Codierung_ADS
ESP_Offroad_Modus

Botschaft Gateway_06:
ESP_Codierung_ADS
ESP_Rollenmodus_deaktivieren

Botschaft Gateway_73:
ESP_Rollenmodus_Deaktivieren
";
CM_ SG_ 924 TSG_BT_1_alt "Veraltet Bit für die Signale:

Botschaft Gateway_05:
BT_Tuer_geoeffnet";
CM_ SG_ 924 TSG_HL_1_alt "Veraltet Bit für die Signale:

Botschaft Gateway_05:
HL_Tuer_geoeffnet";
CM_ SG_ 924 TSG_HR_1_alt "Veraltet Bit für die Signale:

Botschaft Gateway_05:
HR_Tuer_geoeffnet

MOST:";
CM_ SG_ 924 Motor_02_alt "Veraltet Bit für die Signale:

Botschaft Gateway_05:
MO_Status_Normalbetrieb_01";
CM_ SG_ 924 Klima_Sensor_02_alt "Veraltet Bit für die Signale:

Botschaft Gateway_04:
BCM1_FStatus_Aussentemp_ungef
BCM1_Aussen_Temp_ungef

Botschaft Gateway_05:
BCM1_FStatus_Aussentemp_ungef
BCM1_Aussen_Temp_ungef
BCM1_OBD_FStatus_ATemp

Botschaft Gateway_07:
BCM1_Aussen_Tem";
CM_ SG_ 924 TSG_FT_1_alt "Veraltet Bit für die Signale:

Botschaft Gateway_04:
FT_Kisi_Fehler

Botschaft Gateway_05:
FT_Tuer_geoeffnet
FT_Sperrklinke

Botschaft Gateway_09:
FT_Tuer_geoeffnet";
CM_ SG_ 924 Motor_05_alt "Veraltet-Bit für die Signale:

Botschaft Gateway_01:
MO_Anf_KL75
MO_Verbot_EKP
MO_Anf_Pruefimpuls
MO_Klima_Eingr
MO_Aussp_Anlass
MO_Freig_Anlass

Botschaft Gateway_03:
MO_EKlKomLeiRed

Botschaft Gateway_05:
MO_Handshake_STH
MO_Freig_Reku
";
CM_ SG_ 924 QSP_01_alt "Veraltet-Bit für die Signale:

Botschaft Charisma_02:
QS_Charisma_FahrPr
QS_Charisma_Status
QS_Charisma_Umschaltung

Botschaft Gateway_05:
QSP_StartStopp_Info

Botschaft Gateway_13:
QSP_Warnlampe";
CM_ SG_ 924 Parkhilfe_01_alt "Veraltet Bit für die Signale:

Botschaft Gateway_09:
PH_Anf_Audioabsenkung

Botschaft Gateway_05:
PH_StartStopp_Info

Botschaft Gateway_71:
PH_Anf_Audioabsenkung
PH_Systemzustand
PH_Taster

Botschaft Gateway_74:
PH_StartStopp_Info
PH_nachtr";
CM_ SG_ 924 Fahrwerk_02_alt "Veraltet-Bit für die Signale:

Botschaft Charisma_02:
QS_Charisma_FahrPr
QS_Charisma_Status
QS_Charisma_Umschaltung";
CM_ SG_ 924 GW_05_va_27 "
Platzhalter für veraltet Bit in Gatewaybotschaften

GWxx_va_yz

xx: Index der Gatewaybotschaft
y: Byteposition des veraltet Bits
z: Bitposition des veraltet Bits";
CM_ SG_ 924 BCM1_MH_WIV_Schalter "Bewerteter Motorhaubenkontakt fuer WIV";
CM_ SG_ 924 Wischer_vorne_aktiv "Status: Wischer vorne ";
CM_ SG_ 924 BCM1_Rueckfahrlicht_Schalter "Rückfahrlichtschalter
";
CM_ SG_ 924 MO_Status_Normalbetrieb_01 "Das Motorsteuergerät sendet das Informationsbit, wenn die Initialisierungsphase des Steuergerätes abgeschlossen ist. Zusätzlich muss die Klemme 15 eingeschalten sein und eine applizierbare Mindestdrehzahlschwelle (Kennlinie in Abh. von der Kühlwassertempe";
CM_ SG_ 924 KL_Zuheizer_Freigabe "Freigabe Zuheizer
";
CM_ SG_ 924 BCM1_Vorwaertsgang_eingelegt "Erkennung Vorwärtsgang eingelegt (1. / 2. Gang)";
CM_ SG_ 924 ESP_Codierung_ADS "ESP gibt für Empfänger im Fahrzeug aus, ob ADS verbaut/nicht verbaut ist.

Im MQB wird das Signal nicht unterstützt!
";
CM_ SG_ 924 QSP_StartStopp_Info "Stopp-Freigabe und Start-Anforderung an den Start-Stopp-Koordinator";
CM_ SG_ 924 FA_StartStopp_Info "Stopp-Freigabe und Start-Anforderung an den Start-Stopp-Koordinator";
CM_ SG_ 924 PH_StartStopp_Info "Stopp-Freigabe und Start-Anforderung an den Start-Stopp-Koordinator";
CM_ SG_ 924 KL_Beschlagsgefahr "Beschlagsgefahr auf der Frontscheibe im Bereich des Spiegelfusses. Dient zur präventiven Ansteuerung der  Kamera-Scheibenheizung, um Kamera-Blindheit zu vermeiden
PHEV: volle Leistungsfreigabe 
HV Heizer und HV EKK bei Scheibenbeschlag ";
CM_ SG_ 924 BCM1_GLW_Fernlicht_Anf "Harte Fernlichtanforderung von BCM1 an die Funktion 'gleitende Leuchtweite' im AFS-SG";
CM_ SG_ 924 BCM1_RFahrlicht_Fzg_Anf "Anforderung: Rückfahrlicht Fahrzeug (Sollzustand)";
CM_ SG_ 924 MO_Handshake_STH "Es gilt: Signalspec MO_Handshake v1.0

Handshake zwischen MSG und STH. Wenn das MSG die EKP aufgrund einer STH-Anforderung ansteuert und kein Fehlereintrag bzgl. EKP/KPE/NDR vorliegt, wird das Bit gesetzt.";
CM_ SG_ 924 FT_Sperrklinke "Vorraste für Schloß

zwischen Vor- und Hauptraste Signal kurz auf 1, danach wieder auf 0 wenn Tür in Hauptraste (Tür ist sicher zu wenn Sperrklinke und Türkontakt auf 0 sind)";
CM_ SG_ 924 BCM1_OBD_FStatus_ATemp "Fehlerstatus Umgebungstemperatursensor (OBD relevanter Sensor)
";
CM_ SG_ 924 BCM1_Aussen_Temp_ungef "ungefilterter Wert des Aussentemperatursensors
";
CM_ SG_ 924 BCM1_Oeldruck_Schalter "Schalter Oeldruck vorhanden --> nur im B8, nicht im D4 verwendet


";
CM_ SG_ 924 BCM1_Oeldruck_Schalter_2 "Vorhalt Schalter Oeldruck 

nicht im B8 und D4 verwendet

";
CM_ SG_ 924 BT_Tuer_geoeffnet "
";
CM_ SG_ 924 BCM1_Adaptive_Lichtvert_Anf "Funktion 'Adaptive Lichtverteilung' im AFS-SG  Ein- und Ausschalten";
CM_ SG_ 924 BCM1_Gleitende_Leuchtw_Anf "Funktion 'Gleitende Leuchtweite' im AFS-SG  freischalten";
CM_ SG_ 924 BCM1_Schalter_StartStopp "Deaktivierung Start/Stopp über Fahrer";
CM_ SG_ 924 ESP_Offroad_Modus "Nur VW526: Bei Offroad-Fahrzeugen kann über einen Schalter ein Offroadmodus gewählt werden, dieser wird hier angezeigt. Bei Offroad Plus- Fahrzeugen wird hier der Offroadmodus indirekt durch das Verteilergetriebe vorgegeben (ALR_Offroad = 1) und eingespie";
CM_ SG_ 924 MO_Freig_Reku "Empfehlung des Motor-SG's zur Spannungsabsenkung/-anhebung für den Rekuperationsbetrieb";
CM_ SG_ 924 KL_HSH_ein_Soll "Fahrerwunsch (Anforderung) Heckscheibenheizung
";
CM_ SG_ 924 FT_Tuerkontakt_Rohsignal "Logischer Pegel der HW-Leitung des Türkontaktes, welche vom TSG eingelesen wird.
0 > Schalter geschlossen (Tür  auf) 
1 > Schalter offen (Tür zu)

Ungefilterter und unplausibilisierter Status der HW-Leitung vom Türkontakt Fahrertür.";
CM_ SG_ 1318 Klima_Sensor_02_alt "Veraltet Bit für die Signale:

Botschaft Gateway_04:
BCM1_FStatus_Aussentemp_ungef
BCM1_Aussen_Temp_ungef

Botschaft Gateway_05:
BCM1_FStatus_Aussentemp_ungef
BCM1_Aussen_Temp_ungef
BCM1_OBD_FStatus_ATemp

Botschaft Gateway_07:
BCM1_Aussen_Tem";
CM_ SG_ 1318 Wischer_01_alt "Veraltet Bit für die Signale:

Botschaft Gateway_04:
Wischer_vorne_defekt

Botschaft Gateway_05:
Wischer_vorne_aktiv

Botschaft Gateway_07:
Wischer_vorne_aktiv

Botschaft Gateway_72:
Wischer_vorne_aktiv
Waschen_vorne_aktiv
WWSs_01_alt";
CM_ SG_ 1318 SMLS_01_alt "Veraltet Bit für die Signale:

Botschaft Gateway_07:
BH_Blinker_li
BH_Blinker_re
LDW_Taster
LDW_Taster_Fehler
LDW_Vib_Lenkrad_Fehler
BH_Fernlicht

Botschaft Gateway_11:
BH_Blinker_li
BH_Blinker_re

Botschaft Gateway_72:
BH_Blinker_li
BH_Bl";
CM_ SG_ 1318 Kessy_02_alt "Veraltet Bit für die Signale:

Botschaft Gateway_07:
KY_Funkschl_Nr";
CM_ SG_ 1318 Blinkmodi_01_inaktiv "
ACHTUNG: Signal funktioniert wie ein veraltet Bit, ist jedoch auf eine BAF Botschaft bezogen => NICHT FÜR NEUE ROUTINGS ZULASSEN

Veraltet Bit für die Signale:

Botschaft Gateway_07:
BM_links
BM_rechts";
CM_ SG_ 1318 Anhaenger_01_alt "Veraltet Bit für die Signale:

Botschaft Gateway_MED9_01:
AAG_Botschaftszaehler
AAG_Bremsl_durch_ECD
AAG_Bremslicht_H_def

MOST Botschaft K_Gateway_01:
AAG_Anhaenger_erkannt

Botschaft Gateway_72:
AAG_Anhaenger_erkannt

Botschaft Gateway_76:";
CM_ SG_ 1318 BCM1_01_alt "Veraltet Bit für die Signale:

Botschaft Gateway_04:
BCM1_Charisma_Text_1
BCM1_Charisma_Text_2

Botschaft Gateway_05:
BCM1_Rueckfahrlicht_Schalter
BCM1_Vorwaertsgang_eingelegt
BCM1_RFahrlicht_Fzg_Anf
BCM1_Schalter_StartStopp

Botschaft Gateway";
CM_ SG_ 1318 BCM1_02_alt "Veraltet Bit für die Signale:

Botschaft Gateway_05:
BCM1_MH_WIV_Schalter
BCM1_Oeldruck_Schalter
BCM1_Oeldruck_Schalter_2

Botschaft Gateway_11:
LV_Abblendlicht_Anzeige
LV_Abblendlicht_li_def
LV_Abblendlicht_re_def

Botschaft Gateway_07:
LV_F";
CM_ SG_ 1318 Innenlicht_01_alt "Veraltet Bit für die Signale:

Botschaft Gateway_07:
IL_Innenlicht_aktiv";
CM_ SG_ 1318 BCM2_02_alt "Veraltet Bit für die Signale:

Botschaft Gateway_11:
BCM2_P_verriegelt
ZV_verriegelt_extern_ist
BCM_Tankwunsch
ZV_Tankklappe_offen               ";
CM_ SG_ 1318 Motor_06_alt "Veraltet-Bit für die Signale:

Botschaft Gateway_03:
MO_HYB_Fahrbereitschaft

Botschaft Gateway_07:
MO_HYB_Fahrbereitschaft

Botschaft Gateway_10:
WIV_Unterfuell_Warn
WIV_Oelstand_nicht_vorhanden
WIV_Oil_ok
WIV_Check_Oil
WIV_Oelmenge
WIV_nic";
CM_ SG_ 1318 HUD_01_alt "veraltet Bit für Botschaft HUD_01 
	in Gateway_11 & Gateway_07

Folgende Signale sind damit auf Botschaftsempfang überwacht:
	HUD_NV_in_Anzeige 
	HUD_Anzeigefehler_NV";
CM_ SG_ 1318 TSG_FT_01_alt "Veraltet Bit für Signale der Botschaft TSG_FT_01
      HSP: 
            - (HSPe_01): FT_Schluesselschalter_auf, FT_Schluesselschalter_zu
      LIM: 
            - (LIMe_02): FT_Kisi_li_aktiv, FT_Kisi_re_aktiv
      MD1, MD3, MRollo, MRollo2:
      ";
CM_ SG_ 1318 GW_07_va_25 "
Platzhalter für veraltet Bit in Gatewaybotschaften

GWxx_va_yz

xx: Index der Gatewaybotschaft
y: Byteposition des veraltet Bits
z: Bitposition des veraltet Bits";
CM_ SG_ 1318 GW_07_va_26 "
Platzhalter für veraltet Bit in Gatewaybotschaften

GWxx_va_yz

xx: Index der Gatewaybotschaft
y: Byteposition des veraltet Bits
z: Bitposition des veraltet Bits";
CM_ SG_ 1318 GW_07_va_27 "
Platzhalter für veraltet Bit in Gatewaybotschaften

GWxx_va_yz

xx: Index der Gatewaybotschaft
y: Byteposition des veraltet Bits
z: Bitposition des veraltet Bits";
CM_ SG_ 1318 BCM1_Aussen_Temp_ungef "ungefilterter Wert des Aussentemperatursensors
";
CM_ SG_ 1318 BCM1_FStatus_Aussentemp_ungef "Fehlerstatus für Aussentemperatur (Kombianzeige)";
CM_ SG_ 1318 Wischer_vorne_aktiv "Status: Wischer vorne ";
CM_ SG_ 1318 BH_Blinker_li "Blinkerhebel Richtung links
";
CM_ SG_ 1318 BH_Blinker_re "Blinkerhebel Richtung rechts
";
CM_ SG_ 1318 KY_Funkschl_Nr "Funkschlüsselnummer gültig für die Fahrerberechtigung
";
CM_ SG_ 1318 BCM1_Rueckfahrlicht_Schalter "Rückfahrlichtschalter
";
CM_ SG_ 1318 AAG_Anhaenger_erkannt "Erkennung Anhaenger ";
CM_ SG_ 1318 BM_links "Richtungsblinken links

";
CM_ SG_ 1318 BM_rechts "Richtungsblinken rechts

";
CM_ SG_ 1318 BH_Fernlicht "Betaetigung Fernlicht
";
CM_ SG_ 1318 LDW_Taster "Betaetigung LDW Taster
";
CM_ SG_ 1318 LDW_Taster_Fehler "Fehlerstatus LDW Taster
";
CM_ SG_ 1318 LDW_Vib_Lenkrad_Fehler "Fehler Vibrationslenkrad LDW
";
CM_ SG_ 1318 LV_Fernlicht_Anzeige "Fernlicht_aktiv";
CM_ SG_ 1318 LV_Abblendlicht_Anzeige "Abblendlicht aktiv";
CM_ SG_ 1318 LV_Nebellicht_Anzeige "Nebellicht_aktiv
";
CM_ SG_ 1318 IL_Innenlicht_aktiv "Status Innenlicht";
CM_ SG_ 1318 BCM1_MH_Schalter "Motorhaubenkontakt";
CM_ SG_ 1318 ZV_FT_offen "gespiegeltes Bit FT_Tuer_geoeffnet TSG_FT_1 Botschaft";
CM_ SG_ 1318 ZV_BT_offen "gespiegeltes Bit BT_Tuer_geoeffnet TSG_BT_1 Botschaft";
CM_ SG_ 1318 ZV_HL_offen "gespiegeltes Bit HL_Tuer_geoeffnet TSG_HL_1 Botschaft";
CM_ SG_ 1318 ZV_HR_offen "gespiegeltes Bit HR_Tuer_geoeffnet TSG_HR_1 Botschaft";
CM_ SG_ 1318 ZV_HD_offen "Status Heckdeckel
";
CM_ SG_ 1318 ZV_verriegelt_extern_ist "Istzustand: Verriegelung Fahrzeug aussen
";
CM_ SG_ 1318 ZV_ist_Zustand_verfuegbar "Verfügbarkeit IST-Zustand ZV

";
CM_ SG_ 1318 BCM1_NV_Taster "BCM1_NV_Taster gibt an, ob der NightVision-Taster im Lichtdrehschalter-Modul aktuell betaetigt wird.";
CM_ SG_ 1318 MO_HYB_Fahrbereitschaft "Signal steuert u.a. in der Lenkhilfe zusammen mit weiteren Informationen den Modewechsel in den 'Drivemode'
Grüne Anzeige im Kombiinstrument zur Signalisierung der Bereitschaft des Hybridsystems.";
CM_ SG_ 1318 HUD_VZE_in_Anzeige "Rückmeldung,ob VZE-Inhalte im HUD angezeigt werden.";
CM_ SG_ 1318 FT_SWA_Taster "SWA Taster Fahrertür";
CM_ SG_ 1318 FT_SWA_Tasterdiagnose "SWA Taster Diagnose - Kontrolle auf gültigen Wert";
CM_ SG_ 258 Getriebe_03_CHK "Berechnung siehe Lastenheft 'Kommunikationsabsicherung für FlexRay und CAN'
Endwerte siehe 'Kommunikationsabsicherung für FlexRay und CAN / Anhang C: Tabelle S-PDU Kennungen'";
CM_ SG_ 258 GE_Freig_Langfr_Schutzmom "Freigabeflag für das langfristige Schutzmoment für
MLB: GE_Langfr_Schutzmom
MQB: GE_Langfr_Schutzmom_02";
CM_ SG_ 258 GE_Uefkt "Übertragungsfunktion des Getriebes
Drehzahlverhältnis = Eingangsdrehzahl / Ausgangsdrehzahl

AL: Wandlerverstärkung x Drehzahlverhältnis
VL: Drehzahlverhältnis
DL: Drehzahlverhältnis der aktiven und kraftschluß führenden Welle zum Abtrieb, bei Schalt";
CM_ SG_ 258 GE_Zielgang "VL-Getriebe:
Signalisiert den Zielgang im manuellen Modus während eines Schaltvorgangs bzw. die momentane simulierte Gangstufe wenn kein Schaltvorgang aktiv ist. In den Fahrprogrammen 'D' und 'S' ist die Übersetzung variabel und somit wird dauerhaft 'Ist";
CM_ SG_ 258 GE_StartStopp_Info "Stopp-Freigabe und Start-Anforderung an den Start-Stopp-Koordinator";
CM_ SG_ 258 GE_Langfr_Schutzmom "Begrenzung des Motormomentes aus Getriebeschutzgründen. Der langzeitige Motormomenteneingriff ist nur negativ (reduzierend), positiver Mmo-Eingriff wird nicht unterstützt. Ist kein Motormomenteneingriff erforderlich wird der Initwert gesendet. Das Signal ";
CM_ SG_ 258 GE_Performance_Start_LB "Die Bereitschaft zum 'Jump Start' wird mit diesem Signal signalisiert. ";
CM_ SG_ 258 GE_reserv_Waehlhebel "reserviert falls künftig Erweiterung von GE_Waehlhebel nötig";
CM_ SG_ 258 GE_Waehlhebel "Fahrprogramm des Getriebes
0xD: Bedienung AL ab D4";
CM_ SG_ 258 GE_Eingangsdrehz "Wird gesendet, um das Lastschlagverhalten bei Schaltvorgängen zu verbessern.";
CM_ SG_ 258 GE_Notlauf "AL/DL: Signalisiert wenn sich das Getriebe (bei DL ein Teilgetriebe) im Notlauf befindet.
VL: Wird gesetzt wenn kein Kraftschluss möglich ist.";
CM_ SG_ 258 GE_Codierung_MSG "Statusausgabe der Diagnose für Falschverbau. Plausibilisierung der empfangenen Motor- und Getriebevariante mit der erwarteten Motor- und Getriebevarianten.";
CM_ SG_ 1612 GW_Lenker "Rechts-/Linkslenkerinfo
";
CM_ SG_ 1612 GW_Baureihe "Baureihe
";
CM_ SG_ 909 BCM1_Rueckfahrlicht_Schalter "Rückfahrlichtschalter
";
CM_ SG_ 909 HD_Bewegung_zu "Bewegung HD (schließen)
";
CM_ SG_ 909 KY1_FuSchl_Nr_Zugang "Funkschlüsselnummer gueltig für den Fahrzeugzugang

";
CM_ SG_ 909 VS_VD_Bew_auf "



";
CM_ SG_ 909 VS_VD_Bew_zu "


";
CM_ SG_ 909 VS_VD_Fehler "

";
CM_ SG_ 909 F_Kessy_01_Mmi "Ungueltige Signale: KY1_FuSchl_Nr_Zugang";
CM_ SG_ 909 F_HDSG_01_Mmi "Ungueltige Signale: HD_Endstellung_unten, HD_Endstellung_zu
";
CM_ SG_ 909 F_BCM1_01_Mmi "Ungueltige Signale: BCM1_Rueckfahrlicht_Schalter";
CM_ SG_ 909 F_VSG_01_Mmi "Ungueltige Signale: VS_Bew_auf, VS_Bew_zu, VS_VD_Fehler";
CM_ SG_ 1514 PDCC_W_gelb "Anforderung Kombiwarnlampe gelb";
CM_ SG_ 1514 PDCC_W_rot "Anforderung Warnlampe rot
";
CM_ SG_ 1514 DR_Gelbe_Warnlampe "Bit wird gesetzt, wenn während des Betriebes ein Fehler erkannt wird.";
CM_ SG_ 1514 Ni_Anzeige_WaMe_gelb "Eingeschraenkte Funktion: Gelbe Warnmeldung Niveauregelanlage ";
CM_ SG_ 1514 Ni_Anzeige_WaMe_rot "Funktionsausfall: Rote Warnmeldung Niveauregelanlage";
CM_ SG_ 1514 PDCC_St_Stabi "Warntext: 'PDCC Stabilisator passiv'";
CM_ SG_ 1514 DR_Rote_Warnlampe "Bit wird gesetzt, wenn während des Betriebes ein schwerwiegender Fehler erkannt wird.
Darf im VW526 nicht verwendet werden";
CM_ SG_ 1514 DR_DynAGL_Warnlampe "Warnlampe für dynamische Aggregate-Lagerung
Darf im VW526 und PAG E2 nicht verwendet werden";
CM_ SG_ 1514 F_Fahrwerk_05_Mmi "ungueltige Signale: Ni_Anzeige_WaMe_rot,Ni_Anzeige_WaMe_gelb
";
CM_ SG_ 1514 F_Daempfer_01_FR_Mmi "ungueltige Signale: DR_Systemstatus, DR_Gelbe_Warnlampe, DR_Rote_Warnlampe, DR_DynAGL_Warnlampe, DR_Daempferreg_Texte";
CM_ SG_ 1514 F_PDCC_01_Mmi "Ungueltige Signale: PDCC_WaLa_gelb,PDCC_WaLa_rot, PDCC_W_Oel";
CM_ SG_ 796 MO_Drehzahl_01 "Im Fehlerfall wird die Motordrehzahl über die Nockenwellendrehzahl als Ersatzgrösse ausgegeben

Bei Parallelhybrid: Getriebeeingangsdrehzahl (=E-Maschinen Drehzahl)";
CM_ SG_ 796 MO_Kuehlmittel_Temp "Kuehlmitteltemperatur";
CM_ SG_ 796 DR_Daempferreg_Texte "Die Textbits werden verwendet, um im Kombi Texte oder Bilder für die Dämpferregelung darzustellen

0x4 - 0xE tbd.

";
CM_ SG_ 796 MO_Ext_E_Fahrt_aktiv "MLB: Funktionsrückmeldung zum erw. E-Fahr-Betrieb über Lampe/LED im E-Mode-Taster";
CM_ SG_ 796 MO_HYB_VM_aktiv "0 = VMotor wird nicht aktiv gehalten (nVM < n_min und keine LL-Regelung aktiv)
1 = VMotor aktiv (ab der ersten Einspritzung; gilt auch für Schubbetrieb, wenn VMotor spätestens durch LLRegelung befeuert würde)
Verwendet zur Bestimmung des Ist-Zustandes";
CM_ SG_ 796 MO_Fehler_MSpG "Wenn das Motorraumspülgebläse defekt ist, oder die Motorraumtemperatur zu hoch sendet die DME Info ans Kombiinstrument. Dieses gibt Textmeldung aus. Und blinkende Heissleuchte.";
CM_ SG_ 796 MO_Overboost "Nur Turbo. Anzeige eines Overboostpfeils im Kombi während Overboostzustand der Ladedruckregelung.";
CM_ SG_ 796 DR_Systemstatus "Bei Statusänderung wird der Soll-Zustand ausgegeben. Der Status beschreibt einen Parametersatz: Temporäre Änderung der Dämpfereinstellungen werden hier nicht abgebildet. 
";
CM_ SG_ 796 FA_Reglerstatus_Niveau "Anzeige des auszuregelnden Sollniveaus (wird bei Beginn der Regelung auf entsprechenden Wert gesetzt)";
CM_ SG_ 796 GE_Segel_Status "Aktivitätsstatus Segel-Koordinator
HYBRID:
Wenn MO_Hybridfahrzeug = 1 gilt:
Signal bezieht sich nur auf den Verbrennungsmotor, nicht auf den Hybridantrieb";
CM_ SG_ 796 GE_Status_PaddleNeutral "Status Ablauf der Paddle Neutral Funktion";
CM_ SG_ 796 F_Daempfer_01_FR_Mmi "ungueltige Signale: DR_Systemstatus, DR_Gelbe_Warnlampe, DR_Rote_Warnlampe, DR_DynAGL_Warnlampe, DR_Daempferreg_Texte";
CM_ SG_ 796 F_Fahrwerk_02_Mmi "ungueltige Signale: FA_Reglerstatus_Niveau

";
CM_ SG_ 796 F_Motor_03_Mmi "ungueltiges Signal fuer: Mo_Drehzahl_01";
CM_ SG_ 796 F_Motor_07_Mmi "ungueltiges Signal fuer: MO_Kuehlmittel_Temp";
CM_ SG_ 796 F_Motor_15_PAG_Mmi "ungueltiges Signal fuer: MO_Fehler_MSpG, MO_Overboost";
CM_ SG_ 796 F_Motor_02_Mmi "ungueltige Signale: MO_ext_E_Fahrt_aktiv


";
CM_ SG_ 796 F_Motor_Hybrid_01_Mmi "ungueltiges Signal fuer: Mo_HYB_VM_aktiv

";
CM_ SG_ 796 F_Getriebe_07_PAG "ungueltiges Signal fuer:
GE_Segel_Status
GE_Status_PaddleNeutral";
CM_ SG_ 908 HAL_Warnungen "Warnmeldungsanforderung von der Hinterachslenkung an das Kombiinstrumnent";
CM_ SG_ 908 ESP_Querbeschleunigung_Roh "Rohwert der Querbeschleunigung
In ESP-Projekten bspw. ContiTEVES und RB wird ein Sensor-Cluster verwendet, welcher den gemessenen Sensorwert ausgibt. 0x1FF bedeutet hier die Größe kann nicht errechnet werden.
Im D4 erfolgt die Bereitstellung der Sensorw";
CM_ SG_ 908 ESP_Querbeschleunigung_Offset "Offset der Querbeschleunigung
Querbeschleunigung = Rohwert - Offset
";
CM_ SG_ 908 ESP_Eingriff "Eingriff des Fahrdynamikreglers";
CM_ SG_ 908 ESP_Off_Lampe "Bit zur Ansteuerung der separaten ESP-off-Lampe im Kombi (Gesetzesforderung USA)

MLB:
Verwendung/Bedienung ab D4";
CM_ SG_ 908 ESP_Rollenmodus "Signal zeigt an ob sich das ESP im Rollenmodus befindet. Für Porsche gilt: ESP stellt diese Info als Master SG zur Verfügung. 

";
CM_ SG_ 908 ESP_Stillstandsflag "Bei RB-Projekten wird das Stillstandsflag gesetzt, wenn der absolute Stillstand der Raddrehzahlsensoren erkannt wurde, d.h. kein Zahn bewegt sich mehr. Dieses Bit wird bspw. im MOST für TV-Tuner-Abschaltung Australien verwendet, d.h. leichte Erschütterung";
CM_ SG_ 908 ESP_Autohold_aktiv "Rückmeldung an EPB, dass Autohold aktiv ist.";
CM_ SG_ 908 ESP_HDC_Standby "Verwendung/Bedienung im MQB und AU57x Allroad:
Flag wird vom ESP gesetzt, wenn über den HDC-Taster die HDC-Funktion eingeschalten wurde";
CM_ SG_ 908 F_ESP_05_Mmi "ungültige Signale: ESP_autohold_activ, ESP_HDC_Standby
";
CM_ SG_ 908 F_ESP_01_Mmi "ungültige Signale: ESP_Eingriff

";
CM_ SG_ 908 F_ESP_04_Mmi "ungültige Signale: ESP_off_Lampe

";
CM_ SG_ 908 F_ESP_02_Mmi "ungueltige Signale: ESP_Stillstandsflag
";
CM_ SG_ 908 F_ESP_11_Mmi "ungueltige Signale: ESP_Rollenmodus, ESP_F_Sport
";
CM_ SG_ 908 F_ESP_13_Mmi "ungueltige Signale: ESP_Querbeschleunigung_Roh, ESP_Querbeschleunigung_Offset
";
CM_ SG_ 908 HAL_01_alt "Veraltet-Bit für die Signale:

Botschaft Charisma_06_PAG:
HAL_Charisma_FahrPr
HAL_Charisma_Status

Botschaft GW_Mmi_05_PAG:
HAL_Warnungen
";
CM_ SG_ 1515 FS_MMB_storage_beep "Quittierungston Sitzmemory FS (Anforderung Kombi)";
CM_ SG_ 1515 BFS_MMB_storage_beep "Quittierungston Sitzmemory BFS (Anforderung Kombi)

";
CM_ SG_ 1515 BFS_MMB_store "Speichern der Sitzposition
";
CM_ SG_ 1515 BFS_MMB_tast "
";
CM_ SG_ 1515 BFS_MMB_store_LED_on "LED für Speichern
";
CM_ SG_ 1515 LWI_Lenkradwinkel "Wertebereich = +/- 800 Grad
Auflösung = 0,1 Grad
ACHTUNG: spezifizierte Interne Auflösung des Sensors beträgt aber nur Schrittweite 0,5 Grad!

Hinweis:
MLB: Zusätzlich gestellte Winkel bei Dynamiklenkung beachten !
MQB: Nicht konstante Lenkübersetzu";
CM_ SG_ 1515 LWI_VZ_Lenkradwinkel "Vorzeichen Lenkradwinkel gemäss DIN70000; 
Nullstellung = +0";
CM_ SG_ 1515 LWI_QBit_Lenkradwinkel "Das QBit wird auch bei nicht abgeglichenem Lenkradwinkelsensor gesetzt";
CM_ SG_ 1515 F_LWI_01_Mmi "Ungueltige Signale: LWI_Lenkradwinkel, LWI_VZ_Lenkradwinkel,LWI_Sensorstatus,LWI_QBit_Lenkradwinkel";
CM_ SG_ 1515 F_Mem_BFS_01_Mmi "Ungueltige Signale: BFS_Fond_Bed_Ack, BFS_MBB_storage_beep, BFS_MMB_storage,BFS_MMB_store,BFS_MMB_store_LED_on,BFS_MMB_tipp,BFS_MMB_tast";
CM_ SG_ 1515 F_Mem_FS_01_Mmi "Ungueltige Signale: FS_MBB_storage_beep, FS_MMB_storage,FS_MMB_store,FS_MMB_tipp,FS_MMB_tast";
BA_DEF_ BO_  "DiagRequest" ENUM  "No","Yes";
BA_DEF_ BO_  "DiagResponse" ENUM  "No","Yes";
BA_DEF_ BO_  "DiagState" ENUM  "No","Yes";
BA_DEF_ BO_  "GenMsgChkConstant" HEX 0 4095;
BA_DEF_ BO_  "GenMsgCycleTime" INT 0 65535;
BA_DEF_ BO_  "GenMsgCycleTimeFast" INT 0 65535;
BA_DEF_ BO_  "GenMsgDelayTime" INT 0 100000;
BA_DEF_ BO_  "GenMsgILSupport" ENUM  "No","Yes";
BA_DEF_ BO_  "GenMsgNrOfRepetition" INT 0 100;
BA_DEF_ BO_  "GenMsgPDUConstants" STRING ;
BA_DEF_ BO_  "GenMsgSendType" ENUM  "Cyclic","not_used","not_used","not_used","not_used","not_used","not_used","IfActive","NoMsgSendType";
BA_DEF_ BO_  "GenMsgStartDelayTime" INT 0 100000;
BA_DEF_ BO_  "NmMessage" ENUM  "No","Yes";
BA_DEF_ BO_  "NmhMessage" ENUM  "No","Yes";
BA_DEF_ BO_  "MsgType" ENUM  "Application","NM ","NMH","TP2.0","ISO-TP ","BAP","EID";
BA_DEF_ BO_  "VAGTP20_API" HEX 0 255;
BA_DEF_ BO_  "VAGTP20_DynConnection" ENUM  "No","Yes";
BA_DEF_ BO_  "VAGTP20_DynSetup" ENUM  "No","Yes";
BA_DEF_ BO_  "VAGTP20_StatConnection" ENUM  "No","Yes";
BA_DEF_ SG_  "GenSigActiveRepetitions" INT -2147483648 2147483647;
BA_DEF_ SG_  "GenSigInactiveValue" INT -2147483648 2147483647;
BA_DEF_ SG_  "GenSigSendType" ENUM  "Cyclic","OnWrite","OnWriteWithRepetition","OnChange","OnChangeWithRepetition","IfActive","IfActiveWithRepetition","NoSigSendType","OnChangeAndIfActive","OnChangeAndIfActiveWithRepetition";
BA_DEF_ SG_  "GenSigStartValue" INT -2147483648 2147483647;
BA_DEF_ SG_  "NWM-WakeupAllowed" ENUM  "No","Yes";
BA_DEF_ SG_  "GenSigFuncType" ENUM  "NoFunction","MsgCounter","CRC-8","XOR","XOR-2","DatedBit","SW-Kl15","CHK","Constant","Protocol","CRC-8-SAE_J1850";
BA_DEF_ SG_  "GenSigSwitchedByIgnition" ENUM  "No","Yes";
BA_DEF_ SG_  "Fehlerwert" HEX 0 2147483647;
BA_DEF_ SG_  "GenSigMissingSourceValue" HEX 0 2147483647;
BA_DEF_REL_ BU_SG_REL_  "GenSigTimeoutTime" INT 0 65535;
BA_DEF_DEF_REL_ "GenSigTimeoutTime" 0;
BA_DEF_DEF_  "DiagRequest" "No";
BA_DEF_DEF_  "DiagResponse" "No";
BA_DEF_DEF_  "DiagState" "No";
BA_DEF_DEF_  "GenMsgChkConstant" 0;
BA_DEF_DEF_  "GenMsgCycleTime" 0;
BA_DEF_DEF_  "GenMsgCycleTimeFast" 0;
BA_DEF_DEF_  "GenMsgDelayTime" 0;
BA_DEF_DEF_  "GenMsgILSupport" "No";
BA_DEF_DEF_  "GenMsgNrOfRepetition" 0;
BA_DEF_DEF_  "GenMsgPDUConstants" "";
BA_DEF_DEF_  "GenMsgSendType" "NoMsgSendType";
BA_DEF_DEF_  "GenMsgStartDelayTime" 0;
BA_DEF_DEF_  "NmMessage" "No";
BA_DEF_DEF_  "NmhMessage" "No";
BA_DEF_DEF_  "MsgType" "Application";
BA_DEF_DEF_  "VAGTP20_API" 0;
BA_DEF_DEF_  "VAGTP20_DynConnection" "No";
BA_DEF_DEF_  "VAGTP20_DynSetup" "No";
BA_DEF_DEF_  "VAGTP20_StatConnection" "No";
BA_DEF_DEF_  "GenSigActiveRepetitions" 0;
BA_DEF_DEF_  "GenSigInactiveValue" 0;
BA_DEF_DEF_  "GenSigSendType" "NoSigSendType";
BA_DEF_DEF_  "GenSigStartValue" 0;
BA_DEF_DEF_  "NWM-WakeupAllowed" "No";
BA_DEF_DEF_  "GenSigFuncType" "NoFunction";
BA_DEF_DEF_  "GenSigSwitchedByIgnition" "Yes";
BA_DEF_DEF_  "Fehlerwert" 0;
BA_DEF_DEF_  "GenSigMissingSourceValue" 0;
BA_ "GenMsgNrOfRepetition" BO_ 899 5;
BA_ "GenMsgILSupport" BO_ 899 1;
BA_ "GenMsgDelayTime" BO_ 899 10;
BA_ "GenMsgCycleTimeFast" BO_ 899 100;
BA_ "GenMsgSendType" BO_ 1335 0;
BA_ "GenMsgILSupport" BO_ 1335 1;
BA_ "GenMsgCycleTime" BO_ 1335 200;
BA_ "GenMsgSendType" BO_ 1714 0;
BA_ "GenMsgILSupport" BO_ 1714 1;
BA_ "GenMsgCycleTime" BO_ 1714 1000;
BA_ "GenMsgSendType" BO_ 1009 0;
BA_ "GenMsgILSupport" BO_ 1009 1;
BA_ "GenMsgDelayTime" BO_ 1009 10;
BA_ "GenMsgCycleTime" BO_ 1009 100;
BA_ "GenMsgSendType" BO_ 1603 0;
BA_ "GenMsgILSupport" BO_ 1603 1;
BA_ "GenMsgDelayTime" BO_ 1603 100;
BA_ "GenMsgCycleTime" BO_ 1603 1000;
BA_ "GenMsgSendType" BO_ 781 0;
BA_ "GenMsgILSupport" BO_ 781 1;
BA_ "GenMsgDelayTime" BO_ 781 5;
BA_ "GenMsgCycleTime" BO_ 781 50;
BA_ "GenMsgSendType" BO_ 256 0;
BA_ "GenMsgILSupport" BO_ 256 1;
BA_ "GenMsgCycleTime" BO_ 256 20;
BA_ "GenMsgChkConstant" BO_ 256 171;
BA_ "GenMsgSendType" BO_ 257 0;
BA_ "GenMsgILSupport" BO_ 257 1;
BA_ "GenMsgCycleTime" BO_ 257 20;
BA_ "GenMsgChkConstant" BO_ 257 170;
BA_ "GenMsgSendType" BO_ 259 0;
BA_ "GenMsgILSupport" BO_ 259 1;
BA_ "GenMsgCycleTime" BO_ 259 20;
BA_ "GenMsgChkConstant" BO_ 259 2;
BA_ "GenMsgSendType" BO_ 776 0;
BA_ "GenMsgILSupport" BO_ 776 1;
BA_ "GenMsgCycleTime" BO_ 776 50;
BA_ "GenMsgSendType" BO_ 278 0;
BA_ "GenMsgPDUConstants" BO_ 278 "0xac,0xac,0xac,0xac,0xac,0xac,0xac,0xac,0xac,0xac,0xac,0xac,0xac,0xac,0xac,0xac";
BA_ "GenMsgILSupport" BO_ 278 1;
BA_ "GenMsgCycleTime" BO_ 278 20;
BA_ "GenMsgChkConstant" BO_ 278 172;
BA_ "GenMsgSendType" BO_ 963 0;
BA_ "GenMsgILSupport" BO_ 963 1;
BA_ "GenMsgCycleTime" BO_ 963 100;
BA_ "GenMsgSendType" BO_ 1643 0;
BA_ "GenMsgILSupport" BO_ 1643 1;
BA_ "GenMsgDelayTime" BO_ 1643 50;
BA_ "GenMsgCycleTime" BO_ 1643 500;
BA_ "GenMsgSendType" BO_ 924 0;
BA_ "GenMsgILSupport" BO_ 924 1;
BA_ "GenMsgDelayTime" BO_ 924 10;
BA_ "GenMsgCycleTime" BO_ 924 100;
BA_ "GenMsgSendType" BO_ 1318 0;
BA_ "GenMsgNrOfRepetition" BO_ 1318 5;
BA_ "GenMsgILSupport" BO_ 1318 1;
BA_ "GenMsgDelayTime" BO_ 1318 20;
BA_ "GenMsgCycleTimeFast" BO_ 1318 50;
BA_ "GenMsgCycleTime" BO_ 1318 200;
BA_ "GenMsgSendType" BO_ 258 0;
BA_ "GenMsgILSupport" BO_ 258 1;
BA_ "GenMsgCycleTime" BO_ 258 20;
BA_ "GenMsgChkConstant" BO_ 258 3;
BA_ "GenMsgSendType" BO_ 1612 0;
BA_ "GenMsgILSupport" BO_ 1612 1;
BA_ "GenMsgCycleTime" BO_ 1612 1000;
BA_ "GenMsgSendType" BO_ 909 0;
BA_ "GenMsgILSupport" BO_ 909 1;
BA_ "GenMsgDelayTime" BO_ 909 10;
BA_ "GenMsgCycleTime" BO_ 909 100;
BA_ "GenMsgSendType" BO_ 1514 0;
BA_ "GenMsgILSupport" BO_ 1514 1;
BA_ "GenMsgDelayTime" BO_ 1514 50;
BA_ "GenMsgCycleTime" BO_ 1514 500;
BA_ "GenMsgSendType" BO_ 796 0;
BA_ "GenMsgILSupport" BO_ 796 1;
BA_ "GenMsgCycleTime" BO_ 796 50;
BA_ "GenMsgSendType" BO_ 908 0;
BA_ "GenMsgILSupport" BO_ 908 1;
BA_ "GenMsgCycleTime" BO_ 908 100;
BA_ "GenMsgSendType" BO_ 1515 0;
BA_ "GenMsgILSupport" BO_ 1515 1;
BA_ "GenMsgDelayTime" BO_ 1515 50;
BA_ "GenMsgCycleTime" BO_ 1515 500;
BA_ "GenSigSwitchedByIgnition" SG_ 899 CHA_Ziel_FahrPr_HAL 0;
BA_ "GenSigSendType" SG_ 899 CHA_Ziel_FahrPr_HAL 2;
BA_ "GenSigActiveRepetitions" SG_ 899 CHA_Ziel_FahrPr_HAL 5;
BA_ "GenSigSwitchedByIgnition" SG_ 899 CHA_Ziel_FahrPr_BCM 0;
BA_ "GenSigSendType" SG_ 899 CHA_Ziel_FahrPr_BCM 2;
BA_ "GenSigActiveRepetitions" SG_ 899 CHA_Ziel_FahrPr_BCM 5;
BA_ "GenSigSwitchedByIgnition" SG_ 899 CHA_Ziel_FahrPr_HAL_01 0;
BA_ "GenSigSendType" SG_ 899 CHA_Ziel_FahrPr_HAL_01 2;
BA_ "GenSigActiveRepetitions" SG_ 899 CHA_Ziel_FahrPr_HAL_01 5;
BA_ "GenSigSwitchedByIgnition" SG_ 899 CHA_Ziel_FahrPr_BMS 0;
BA_ "GenSigSendType" SG_ 899 CHA_Ziel_FahrPr_BMS 2;
BA_ "GenSigActiveRepetitions" SG_ 899 CHA_Ziel_FahrPr_BMS 5;
BA_ "GenSigSwitchedByIgnition" SG_ 899 CHA_Ziel_FahrPr_ALR 0;
BA_ "GenSigSendType" SG_ 899 CHA_Ziel_FahrPr_ALR 2;
BA_ "GenSigActiveRepetitions" SG_ 899 CHA_Ziel_FahrPr_ALR 5;
BA_ "GenSigSwitchedByIgnition" SG_ 899 CHA_Ziel_FahrPr_ESP 0;
BA_ "GenSigSendType" SG_ 899 CHA_Ziel_FahrPr_ESP 2;
BA_ "GenSigActiveRepetitions" SG_ 899 CHA_Ziel_FahrPr_ESP 5;
BA_ "GenSigSwitchedByIgnition" SG_ 899 CHA_Ziel_FahrPr_PDCC 0;
BA_ "GenSigSendType" SG_ 899 CHA_Ziel_FahrPr_PDCC 2;
BA_ "GenSigActiveRepetitions" SG_ 899 CHA_Ziel_FahrPr_PDCC 5;
BA_ "GenSigSwitchedByIgnition" SG_ 899 CHA_Ziel_FahrPr_QUER 0;
BA_ "GenSigSendType" SG_ 899 CHA_Ziel_FahrPr_QUER 2;
BA_ "GenSigActiveRepetitions" SG_ 899 CHA_Ziel_FahrPr_QUER 5;
BA_ "GenSigSwitchedByIgnition" SG_ 899 CHA_Ziel_FahrPr_MO_01 0;
BA_ "GenSigSendType" SG_ 899 CHA_Ziel_FahrPr_MO_01 2;
BA_ "GenSigActiveRepetitions" SG_ 899 CHA_Ziel_FahrPr_MO_01 5;
BA_ "GenSigSwitchedByIgnition" SG_ 899 CHA_Ziel_FahrPr_GE_01 0;
BA_ "GenSigSendType" SG_ 899 CHA_Ziel_FahrPr_GE_01 2;
BA_ "GenSigActiveRepetitions" SG_ 899 CHA_Ziel_FahrPr_GE_01 5;
BA_ "GenSigSwitchedByIgnition" SG_ 899 CHA_Ziel_FahrPr_MO_02 0;
BA_ "GenSigSendType" SG_ 899 CHA_Ziel_FahrPr_MO_02 2;
BA_ "GenSigActiveRepetitions" SG_ 899 CHA_Ziel_FahrPr_MO_02 5;
BA_ "GenSigSwitchedByIgnition" SG_ 899 CHA_Ziel_FahrPr_GE_02 0;
BA_ "GenSigSendType" SG_ 899 CHA_Ziel_FahrPr_GE_02 2;
BA_ "GenSigActiveRepetitions" SG_ 899 CHA_Ziel_FahrPr_GE_02 5;
BA_ "GenSigSwitchedByIgnition" SG_ 899 CHA_Ziel_FahrPr_MO_03 0;
BA_ "GenSigSendType" SG_ 899 CHA_Ziel_FahrPr_MO_03 2;
BA_ "GenSigActiveRepetitions" SG_ 899 CHA_Ziel_FahrPr_MO_03 5;
BA_ "GenSigSwitchedByIgnition" SG_ 899 CHA_Ziel_FahrPr_GE_03 0;
BA_ "GenSigSendType" SG_ 899 CHA_Ziel_FahrPr_GE_03 2;
BA_ "GenSigActiveRepetitions" SG_ 899 CHA_Ziel_FahrPr_GE_03 5;
BA_ "GenSigSwitchedByIgnition" SG_ 899 CHA_Ziel_FahrPr_DR_01 0;
BA_ "GenSigSendType" SG_ 899 CHA_Ziel_FahrPr_DR_01 2;
BA_ "GenSigActiveRepetitions" SG_ 899 CHA_Ziel_FahrPr_DR_01 5;
BA_ "GenSigSwitchedByIgnition" SG_ 899 CHA_Ziel_FahrPr_Lift 0;
BA_ "GenSigSendType" SG_ 899 CHA_Ziel_FahrPr_Lift 2;
BA_ "GenSigActiveRepetitions" SG_ 899 CHA_Ziel_FahrPr_Lift 5;
BA_ "GenSigSendType" SG_ 1335 ALR_Charisma_FahrPr 0;
BA_ "GenSigSendType" SG_ 1335 ALR_Charisma_Status 0;
BA_ "GenSigSendType" SG_ 1335 ALR_Charisma_Umschaltung 0;
BA_ "GenSigFuncType" SG_ 1335 Allrad_02_alt 5;
BA_ "GenSigStartValue" SG_ 1335 Allrad_02_alt 1;
BA_ "GenSigSendType" SG_ 1335 Allrad_02_alt 0;
BA_ "GenSigSwitchedByIgnition" SG_ 1335 ESP_Charisma_FahrPr 0;
BA_ "GenSigSendType" SG_ 1335 ESP_Charisma_FahrPr 3;
BA_ "GenSigSwitchedByIgnition" SG_ 1335 ESP_Charisma_Status 0;
BA_ "GenSigSendType" SG_ 1335 ESP_Charisma_Status 0;
BA_ "GenSigSwitchedByIgnition" SG_ 1335 ESP_Charisma_Umschaltung 0;
BA_ "GenSigSendType" SG_ 1335 ESP_Charisma_Umschaltung 3;
BA_ "GenSigSwitchedByIgnition" SG_ 1335 ESP_11_alt 0;
BA_ "GenSigFuncType" SG_ 1335 ESP_11_alt 5;
BA_ "GenSigStartValue" SG_ 1335 ESP_11_alt 1;
BA_ "GenSigSendType" SG_ 1335 ESP_11_alt 0;
BA_ "GenSigSendType" SG_ 1335 PDCC_Charisma_FahrPr 3;
BA_ "GenSigSendType" SG_ 1335 PDCC_Charisma_Status 0;
BA_ "GenSigSendType" SG_ 1335 PDCC_Charisma_Umschaltung 3;
BA_ "GenSigFuncType" SG_ 1335 PDCC_01_PAG_alt 5;
BA_ "GenSigStartValue" SG_ 1335 PDCC_01_PAG_alt 1;
BA_ "GenSigSendType" SG_ 1335 PDCC_01_PAG_alt 0;
BA_ "GenSigSwitchedByIgnition" SG_ 1335 QUER_Charisma_FahrPr 0;
BA_ "GenSigSendType" SG_ 1335 QUER_Charisma_FahrPr 3;
BA_ "GenSigSwitchedByIgnition" SG_ 1335 QUER_Charisma_Status 0;
BA_ "GenSigSendType" SG_ 1335 QUER_Charisma_Status 0;
BA_ "GenSigSwitchedByIgnition" SG_ 1335 QUER_Charisma_Umschaltung 0;
BA_ "GenSigSendType" SG_ 1335 QUER_Charisma_Umschaltung 3;
BA_ "GenSigSwitchedByIgnition" SG_ 1335 Quersperre_02_PAG_alt 0;
BA_ "GenSigFuncType" SG_ 1335 Quersperre_02_PAG_alt 5;
BA_ "GenSigStartValue" SG_ 1335 Quersperre_02_PAG_alt 1;
BA_ "GenSigSendType" SG_ 1335 Quersperre_02_PAG_alt 0;
BA_ "GenSigSwitchedByIgnition" SG_ 1335 HAL_Charisma_FahrPr 0;
BA_ "GenSigSendType" SG_ 1335 HAL_Charisma_FahrPr 3;
BA_ "GenSigSwitchedByIgnition" SG_ 1335 HAL_Charisma_Status 0;
BA_ "GenSigSendType" SG_ 1335 HAL_Charisma_Status 0;
BA_ "GenSigSwitchedByIgnition" SG_ 1335 HAL_01_alt 0;
BA_ "GenSigFuncType" SG_ 1335 HAL_01_alt 5;
BA_ "GenSigStartValue" SG_ 1335 HAL_01_alt 1;
BA_ "GenSigSendType" SG_ 1335 HAL_01_alt 0;
BA_ "GenSigSwitchedByIgnition" SG_ 1335 Lift_Charisma_FahrPr 0;
BA_ "GenSigSendType" SG_ 1335 Lift_Charisma_FahrPr 3;
BA_ "GenSigSwitchedByIgnition" SG_ 1335 Lift_Charisma_Status 0;
BA_ "GenSigSendType" SG_ 1335 Lift_Charisma_Status 0;
BA_ "GenSigSwitchedByIgnition" SG_ 1335 Lift_Charisma_Umschaltung 0;
BA_ "GenSigSendType" SG_ 1335 Lift_Charisma_Umschaltung 3;
BA_ "GenSigSwitchedByIgnition" SG_ 1335 Lift_01_alt 0;
BA_ "GenSigFuncType" SG_ 1335 Lift_01_alt 5;
BA_ "GenSigStartValue" SG_ 1335 Lift_01_alt 1;
BA_ "GenSigSendType" SG_ 1335 Lift_01_alt 0;
BA_ "GenSigSwitchedByIgnition" SG_ 1714 DGN_Verlernzaehler 0;
BA_ "GenSigSendType" SG_ 1714 DGN_Verlernzaehler 0;
BA_ "Fehlerwert" SG_ 1714 KBI_Kilometerstand 1048575;
BA_ "GenSigSwitchedByIgnition" SG_ 1714 KBI_Kilometerstand 0;
BA_ "GenSigStartValue" SG_ 1714 KBI_Kilometerstand 1048574;
BA_ "GenSigSendType" SG_ 1714 KBI_Kilometerstand 0;
BA_ "GenSigSwitchedByIgnition" SG_ 1714 UH_Jahr 0;
BA_ "GenSigSendType" SG_ 1714 UH_Jahr 0;
BA_ "GenSigSwitchedByIgnition" SG_ 1714 UH_Monat 0;
BA_ "GenSigSendType" SG_ 1714 UH_Monat 0;
BA_ "GenSigSwitchedByIgnition" SG_ 1714 UH_Tag 0;
BA_ "GenSigSendType" SG_ 1714 UH_Tag 0;
BA_ "GenSigSwitchedByIgnition" SG_ 1714 UH_Stunde 0;
BA_ "GenSigSendType" SG_ 1714 UH_Stunde 0;
BA_ "GenSigSwitchedByIgnition" SG_ 1714 UH_Minute 0;
BA_ "GenSigSendType" SG_ 1714 UH_Minute 0;
BA_ "GenSigSwitchedByIgnition" SG_ 1714 UH_Sekunde 0;
BA_ "GenSigSendType" SG_ 1714 UH_Sekunde 0;
BA_ "GenSigSwitchedByIgnition" SG_ 1714 Kombi_02_alt 0;
BA_ "GenSigFuncType" SG_ 1714 Kombi_02_alt 5;
BA_ "GenSigStartValue" SG_ 1714 Kombi_02_alt 1;
BA_ "GenSigSendType" SG_ 1714 Kombi_02_alt 0;
BA_ "GenSigSwitchedByIgnition" SG_ 1714 Uhrzeit_01_alt 0;
BA_ "GenSigFuncType" SG_ 1714 Uhrzeit_01_alt 5;
BA_ "GenSigStartValue" SG_ 1714 Uhrzeit_01_alt 1;
BA_ "GenSigSendType" SG_ 1714 Uhrzeit_01_alt 0;
BA_ "GenSigSwitchedByIgnition" SG_ 1009 GW_STH_Anf 0;
BA_ "NWM-WakeupAllowed" SG_ 1009 GW_STH_Anf 1;
BA_ "GenSigSendType" SG_ 1009 GW_STH_Anf 0;
BA_ "GenSigSwitchedByIgnition" SG_ 1009 FSAktivBit 0;
BA_ "NWM-WakeupAllowed" SG_ 1009 FSAktivBit 1;
BA_ "GenSigSendType" SG_ 1009 FSAktivBit 3;
BA_ "GenSigSwitchedByIgnition" SG_ 1603 KBI_Einheit_Datum 0;
BA_ "GenSigSendType" SG_ 1603 KBI_Einheit_Datum 3;
BA_ "GenSigSwitchedByIgnition" SG_ 1603 KBI_Einheit_Druck 0;
BA_ "GenSigSendType" SG_ 1603 KBI_Einheit_Druck 3;
BA_ "GenSigSwitchedByIgnition" SG_ 1603 KBI_Einheit_Streckenanz 0;
BA_ "GenSigSendType" SG_ 1603 KBI_Einheit_Streckenanz 3;
BA_ "GenSigSwitchedByIgnition" SG_ 1603 KBI_MFA_v_Einheit_02 0;
BA_ "GenSigSendType" SG_ 1603 KBI_MFA_v_Einheit_02 3;
BA_ "GenSigSwitchedByIgnition" SG_ 1603 KBI_Einheit_Temp 0;
BA_ "GenSigSendType" SG_ 1603 KBI_Einheit_Temp 3;
BA_ "GenSigSwitchedByIgnition" SG_ 1603 KBI_Einheit_Uhrzeit 0;
BA_ "GenSigSendType" SG_ 1603 KBI_Einheit_Uhrzeit 3;
BA_ "GenSigSwitchedByIgnition" SG_ 1603 KBI_Einheit_Verbrauch 0;
BA_ "GenSigSendType" SG_ 1603 KBI_Einheit_Verbrauch 3;
BA_ "GenSigSwitchedByIgnition" SG_ 1603 KBI_Einheit_Volumen 0;
BA_ "GenSigSendType" SG_ 1603 KBI_Einheit_Volumen 3;
BA_ "GenSigSwitchedByIgnition" SG_ 1603 KBI_Einheit_Verbrauch_elektr 0;
BA_ "GenSigSendType" SG_ 1603 KBI_Einheit_Verbrauch_elektr 3;
BA_ "GenSigSwitchedByIgnition" SG_ 1603 KBI_Einheit_Sprache 0;
BA_ "GenSigSendType" SG_ 1603 KBI_Einheit_Sprache 3;
BA_ "GenSigSwitchedByIgnition" SG_ 781 EPB_Fehlerlampe_Gelb 0;
BA_ "GenSigSendType" SG_ 781 EPB_Fehlerlampe_Gelb 3;
BA_ "GenSigSwitchedByIgnition" SG_ 781 EPB_Fehlerlampe_BKL 0;
BA_ "GenSigSendType" SG_ 781 EPB_Fehlerlampe_BKL 3;
BA_ "GenSigSwitchedByIgnition" SG_ 781 EPB_Funktionslampe 0;
BA_ "GenSigSendType" SG_ 781 EPB_Funktionslampe 3;
BA_ "GenSigSwitchedByIgnition" SG_ 781 EPB_Texte 0;
BA_ "GenSigSendType" SG_ 781 EPB_Texte 3;
BA_ "GenSigSwitchedByIgnition" SG_ 781 EPB_Akustik 0;
BA_ "GenSigSendType" SG_ 781 EPB_Akustik 3;
BA_ "GenSigSwitchedByIgnition" SG_ 781 EPB_Autoholdlampe 0;
BA_ "GenSigSendType" SG_ 781 EPB_Autoholdlampe 3;
BA_ "GenSigSwitchedByIgnition" SG_ 781 EPB_Bremsbelag_Warn 0;
BA_ "GenSigSendType" SG_ 781 EPB_Bremsbelag_Warn 0;
BA_ "GenSigSwitchedByIgnition" SG_ 256 ESP_01_CHK 0;
BA_ "GenSigFuncType" SG_ 256 ESP_01_CHK 4;
BA_ "GenSigSendType" SG_ 256 ESP_01_CHK 0;
BA_ "GenSigSwitchedByIgnition" SG_ 256 ESP_01_BZ 0;
BA_ "GenSigFuncType" SG_ 256 ESP_01_BZ 1;
BA_ "GenSigSendType" SG_ 256 ESP_01_BZ 0;
BA_ "Fehlerwert" SG_ 256 ASR_Moment_langsam 1023;
BA_ "GenSigSwitchedByIgnition" SG_ 256 ASR_Moment_langsam 0;
BA_ "GenSigStartValue" SG_ 256 ASR_Moment_langsam 1022;
BA_ "GenSigSendType" SG_ 256 ASR_Moment_langsam 0;
BA_ "Fehlerwert" SG_ 256 ASR_MSR_Moment_schnell 1023;
BA_ "GenSigSwitchedByIgnition" SG_ 256 ASR_MSR_Moment_schnell 0;
BA_ "GenSigStartValue" SG_ 256 ASR_MSR_Moment_schnell 1022;
BA_ "GenSigSendType" SG_ 256 ASR_MSR_Moment_schnell 0;
BA_ "GenSigMissingSourceValue" SG_ 256 ESP_v_Signal 65534;
BA_ "Fehlerwert" SG_ 256 ESP_v_Signal 65535;
BA_ "GenSigSwitchedByIgnition" SG_ 256 ESP_v_Signal 0;
BA_ "GenSigStartValue" SG_ 256 ESP_v_Signal 65534;
BA_ "GenSigSendType" SG_ 256 ESP_v_Signal 0;
BA_ "GenSigSwitchedByIgnition" SG_ 256 ASR_Tastung_passiv 0;
BA_ "GenSigSendType" SG_ 256 ASR_Tastung_passiv 0;
BA_ "GenSigSwitchedByIgnition" SG_ 256 ESP_Tastung_passiv 0;
BA_ "GenSigSendType" SG_ 256 ESP_Tastung_passiv 0;
BA_ "GenSigSwitchedByIgnition" SG_ 256 ESP_Systemstatus 0;
BA_ "GenSigSendType" SG_ 256 ESP_Systemstatus 0;
BA_ "GenSigSwitchedByIgnition" SG_ 256 ASR_Schalteingriff 0;
BA_ "GenSigSendType" SG_ 256 ASR_Schalteingriff 0;
BA_ "GenSigSwitchedByIgnition" SG_ 256 OBD_Schlechtweg 0;
BA_ "GenSigSendType" SG_ 256 OBD_Schlechtweg 0;
BA_ "GenSigSwitchedByIgnition" SG_ 256 OBD_QBit_Schlechtweg 0;
BA_ "GenSigStartValue" SG_ 256 OBD_QBit_Schlechtweg 1;
BA_ "GenSigSendType" SG_ 256 OBD_QBit_Schlechtweg 0;
BA_ "GenSigSwitchedByIgnition" SG_ 256 ESP_QBit_v_Signal 0;
BA_ "GenSigStartValue" SG_ 256 ESP_QBit_v_Signal 1;
BA_ "GenSigSendType" SG_ 256 ESP_QBit_v_Signal 0;
BA_ "GenSigSwitchedByIgnition" SG_ 256 ABS_Bremsung 0;
BA_ "GenSigSendType" SG_ 256 ABS_Bremsung 0;
BA_ "GenSigSwitchedByIgnition" SG_ 256 ASR_Anf 0;
BA_ "GenSigSendType" SG_ 256 ASR_Anf 0;
BA_ "GenSigSwitchedByIgnition" SG_ 256 MSR_Anf 0;
BA_ "GenSigSendType" SG_ 256 MSR_Anf 0;
BA_ "GenSigSwitchedByIgnition" SG_ 256 EBV_Eingriff 0;
BA_ "GenSigSendType" SG_ 256 EBV_Eingriff 0;
BA_ "GenSigSwitchedByIgnition" SG_ 256 EDS_Eingriff 0;
BA_ "GenSigSendType" SG_ 256 EDS_Eingriff 0;
BA_ "GenSigSwitchedByIgnition" SG_ 256 ESP_Eingriff 0;
BA_ "GenSigSendType" SG_ 256 ESP_Eingriff 0;
BA_ "GenSigSwitchedByIgnition" SG_ 256 ESP_ASP 0;
BA_ "GenSigSendType" SG_ 256 ESP_ASP 0;
BA_ "GenSigSwitchedByIgnition" SG_ 256 ESP_KD_Fehler 0;
BA_ "GenSigSendType" SG_ 256 ESP_KD_Fehler 0;
BA_ "GenSigSwitchedByIgnition" SG_ 257 ESP_02_CHK 0;
BA_ "GenSigFuncType" SG_ 257 ESP_02_CHK 4;
BA_ "GenSigSendType" SG_ 257 ESP_02_CHK 0;
BA_ "GenSigSwitchedByIgnition" SG_ 257 ESP_02_BZ 0;
BA_ "GenSigFuncType" SG_ 257 ESP_02_BZ 1;
BA_ "GenSigSendType" SG_ 257 ESP_02_BZ 0;
BA_ "GenSigSwitchedByIgnition" SG_ 257 ESP_QBit_Gierrate 0;
BA_ "GenSigStartValue" SG_ 257 ESP_QBit_Gierrate 1;
BA_ "GenSigSendType" SG_ 257 ESP_QBit_Gierrate 0;
BA_ "GenSigSwitchedByIgnition" SG_ 257 ESP_QBit_Laengsbeschl 0;
BA_ "GenSigStartValue" SG_ 257 ESP_QBit_Laengsbeschl 1;
BA_ "GenSigSendType" SG_ 257 ESP_QBit_Laengsbeschl 0;
BA_ "GenSigSwitchedByIgnition" SG_ 257 ESP_QBit_Querb 0;
BA_ "GenSigStartValue" SG_ 257 ESP_QBit_Querb 1;
BA_ "GenSigSendType" SG_ 257 ESP_QBit_Querb 0;
BA_ "GenSigSwitchedByIgnition" SG_ 257 ESP_Stillstandsflag 0;
BA_ "GenSigSendType" SG_ 257 ESP_Stillstandsflag 0;
BA_ "Fehlerwert" SG_ 257 ESP_Querbeschleunigung 255;
BA_ "GenSigSwitchedByIgnition" SG_ 257 ESP_Querbeschleunigung 0;
BA_ "GenSigStartValue" SG_ 257 ESP_Querbeschleunigung 127;
BA_ "GenSigSendType" SG_ 257 ESP_Querbeschleunigung 0;
BA_ "Fehlerwert" SG_ 257 ESP_Laengsbeschl 1023;
BA_ "GenSigSwitchedByIgnition" SG_ 257 ESP_Laengsbeschl 0;
BA_ "GenSigStartValue" SG_ 257 ESP_Laengsbeschl 512;
BA_ "GenSigSendType" SG_ 257 ESP_Laengsbeschl 0;
BA_ "Fehlerwert" SG_ 257 ESP_Verteil_Wankmom 31;
BA_ "GenSigSwitchedByIgnition" SG_ 257 ESP_Verteil_Wankmom 0;
BA_ "GenSigStartValue" SG_ 257 ESP_Verteil_Wankmom 30;
BA_ "GenSigSendType" SG_ 257 ESP_Verteil_Wankmom 0;
BA_ "GenSigSwitchedByIgnition" SG_ 257 ESP_QBit_Anf_Vert_Wank 0;
BA_ "GenSigStartValue" SG_ 257 ESP_QBit_Anf_Vert_Wank 1;
BA_ "GenSigSendType" SG_ 257 ESP_QBit_Anf_Vert_Wank 0;
BA_ "Fehlerwert" SG_ 257 ESP_Gierrate 16383;
BA_ "GenSigSwitchedByIgnition" SG_ 257 ESP_Gierrate 0;
BA_ "GenSigSendType" SG_ 257 ESP_Gierrate 0;
BA_ "GenSigSwitchedByIgnition" SG_ 257 ESP_VZ_Gierrate 0;
BA_ "GenSigSendType" SG_ 257 ESP_VZ_Gierrate 0;
BA_ "GenSigSwitchedByIgnition" SG_ 257 ESP_Notbremsanzeige 0;
BA_ "GenSigSendType" SG_ 257 ESP_Notbremsanzeige 0;
BA_ "GenSigSwitchedByIgnition" SG_ 257 ESP_SpannungsAnf 0;
BA_ "GenSigSendType" SG_ 257 ESP_SpannungsAnf 0;
BA_ "GenSigSwitchedByIgnition" SG_ 257 ESP_PLA_Abbruch 0;
BA_ "GenSigSendType" SG_ 257 ESP_PLA_Abbruch 0;
BA_ "GenSigSwitchedByIgnition" SG_ 257 ESP_Status_ESP_PLA 0;
BA_ "GenSigSendType" SG_ 257 ESP_Status_ESP_PLA 0;
BA_ "GenSigSwitchedByIgnition" SG_ 259 ESP_03_CHK 0;
BA_ "GenSigFuncType" SG_ 259 ESP_03_CHK 3;
BA_ "GenSigSendType" SG_ 259 ESP_03_CHK 0;
BA_ "GenSigSwitchedByIgnition" SG_ 259 ESP_03_BZ 0;
BA_ "GenSigFuncType" SG_ 259 ESP_03_BZ 1;
BA_ "GenSigSendType" SG_ 259 ESP_03_BZ 0;
BA_ "GenSigSwitchedByIgnition" SG_ 259 ESP_VL_FR 0;
BA_ "GenSigSendType" SG_ 259 ESP_VL_FR 0;
BA_ "GenSigSwitchedByIgnition" SG_ 259 ESP_VR_FR 0;
BA_ "GenSigSendType" SG_ 259 ESP_VR_FR 0;
BA_ "GenSigSwitchedByIgnition" SG_ 259 ESP_HL_FR 0;
BA_ "GenSigSendType" SG_ 259 ESP_HL_FR 0;
BA_ "GenSigSwitchedByIgnition" SG_ 259 ESP_HR_FR 0;
BA_ "GenSigSendType" SG_ 259 ESP_HR_FR 0;
BA_ "Fehlerwert" SG_ 259 ESP_VL_Radgeschw 4095;
BA_ "GenSigSwitchedByIgnition" SG_ 259 ESP_VL_Radgeschw 0;
BA_ "GenSigStartValue" SG_ 259 ESP_VL_Radgeschw 4094;
BA_ "GenSigSendType" SG_ 259 ESP_VL_Radgeschw 0;
BA_ "Fehlerwert" SG_ 259 ESP_VR_Radgeschw 4095;
BA_ "GenSigSwitchedByIgnition" SG_ 259 ESP_VR_Radgeschw 0;
BA_ "GenSigStartValue" SG_ 259 ESP_VR_Radgeschw 4094;
BA_ "GenSigSendType" SG_ 259 ESP_VR_Radgeschw 0;
BA_ "Fehlerwert" SG_ 259 ESP_HL_Radgeschw 4095;
BA_ "GenSigSwitchedByIgnition" SG_ 259 ESP_HL_Radgeschw 0;
BA_ "GenSigStartValue" SG_ 259 ESP_HL_Radgeschw 4094;
BA_ "GenSigSendType" SG_ 259 ESP_HL_Radgeschw 0;
BA_ "Fehlerwert" SG_ 259 ESP_HR_Radgeschw 4095;
BA_ "GenSigSwitchedByIgnition" SG_ 259 ESP_HR_Radgeschw 0;
BA_ "GenSigStartValue" SG_ 259 ESP_HR_Radgeschw 4094;
BA_ "GenSigSendType" SG_ 259 ESP_HR_Radgeschw 0;
BA_ "GenSigSwitchedByIgnition" SG_ 776 ESP_Meldungen 0;
BA_ "GenSigSendType" SG_ 776 ESP_Meldungen 0;
BA_ "GenSigSwitchedByIgnition" SG_ 776 ESP_HDC_FktLampe 0;
BA_ "GenSigSendType" SG_ 776 ESP_HDC_FktLampe 0;
BA_ "GenSigSwitchedByIgnition" SG_ 776 ESP_Lampe 0;
BA_ "GenSigStartValue" SG_ 776 ESP_Lampe 1;
BA_ "GenSigSendType" SG_ 776 ESP_Lampe 0;
BA_ "GenSigSwitchedByIgnition" SG_ 776 ABS_Lampe 0;
BA_ "GenSigStartValue" SG_ 776 ABS_Lampe 1;
BA_ "GenSigSendType" SG_ 776 ABS_Lampe 0;
BA_ "GenSigSwitchedByIgnition" SG_ 776 BK_Lampe 0;
BA_ "GenSigStartValue" SG_ 776 BK_Lampe 1;
BA_ "GenSigSendType" SG_ 776 BK_Lampe 0;
BA_ "GenSigSwitchedByIgnition" SG_ 776 ESP_Akustik 0;
BA_ "GenSigSendType" SG_ 776 ESP_Akustik 0;
BA_ "GenSigSwitchedByIgnition" SG_ 776 ESP_Diagnose 0;
BA_ "GenSigSendType" SG_ 776 ESP_Diagnose 0;
BA_ "GenSigSwitchedByIgnition" SG_ 776 ESP_Textanzeigen_02 0;
BA_ "GenSigSendType" SG_ 776 ESP_Textanzeigen_02 0;
BA_ "GenSigSwitchedByIgnition" SG_ 776 ESP_Off_Lampe 0;
BA_ "GenSigSendType" SG_ 776 ESP_Off_Lampe 0;
BA_ "Fehlerwert" SG_ 776 ESP_m_Raddrehz 32767;
BA_ "GenSigSwitchedByIgnition" SG_ 776 ESP_m_Raddrehz 0;
BA_ "GenSigStartValue" SG_ 776 ESP_m_Raddrehz 32766;
BA_ "GenSigSendType" SG_ 776 ESP_m_Raddrehz 0;
BA_ "GenSigSwitchedByIgnition" SG_ 776 ESP_ASR_Lampe 0;
BA_ "GenSigSendType" SG_ 776 ESP_ASR_Lampe 0;
BA_ "GenSigSwitchedByIgnition" SG_ 776 ESP_Wegimp_VA 0;
BA_ "GenSigSendType" SG_ 776 ESP_Wegimp_VA 0;
BA_ "GenSigSwitchedByIgnition" SG_ 776 ESP_Fehlerstatus_Wegimp 0;
BA_ "GenSigSendType" SG_ 776 ESP_Fehlerstatus_Wegimp 0;
BA_ "GenSigSwitchedByIgnition" SG_ 776 ESP_Wegimp_Ueberlauf 0;
BA_ "GenSigSendType" SG_ 776 ESP_Wegimp_Ueberlauf 0;
BA_ "GenSigSwitchedByIgnition" SG_ 776 ESP_QBit_Wegimp_VA 0;
BA_ "GenSigStartValue" SG_ 776 ESP_QBit_Wegimp_VA 1;
BA_ "GenSigSendType" SG_ 776 ESP_QBit_Wegimp_VA 0;
BA_ "GenSigSwitchedByIgnition" SG_ 776 ESP_Displaywarnungen 0;
BA_ "GenSigSendType" SG_ 776 ESP_Displaywarnungen 0;
BA_ "Fehlerwert" SG_ 776 ESP_HDC_Regelgeschw 127;
BA_ "GenSigSwitchedByIgnition" SG_ 776 ESP_HDC_Regelgeschw 0;
BA_ "GenSigStartValue" SG_ 776 ESP_HDC_Regelgeschw 126;
BA_ "GenSigSendType" SG_ 776 ESP_HDC_Regelgeschw 0;
BA_ "GenSigSwitchedByIgnition" SG_ 776 ESP_BKV_Warnung 0;
BA_ "GenSigSendType" SG_ 776 ESP_BKV_Warnung 0;
BA_ "GenSigSwitchedByIgnition" SG_ 776 ESP_Zaehnezahl 0;
BA_ "GenSigFuncType" SG_ 776 ESP_Zaehnezahl 8;
BA_ "GenSigSendType" SG_ 776 ESP_Zaehnezahl 0;
BA_ "GenSigSwitchedByIgnition" SG_ 278 ESP_10_CRC 0;
BA_ "GenSigFuncType" SG_ 278 ESP_10_CRC 2;
BA_ "GenSigSendType" SG_ 278 ESP_10_CRC 0;
BA_ "GenSigSwitchedByIgnition" SG_ 278 ESP_10_BZ 0;
BA_ "GenSigFuncType" SG_ 278 ESP_10_BZ 1;
BA_ "GenSigSendType" SG_ 278 ESP_10_BZ 0;
BA_ "GenSigSwitchedByIgnition" SG_ 278 ESP_QBit_Wegimpuls_VL 0;
BA_ "GenSigStartValue" SG_ 278 ESP_QBit_Wegimpuls_VL 1;
BA_ "GenSigSendType" SG_ 278 ESP_QBit_Wegimpuls_VL 0;
BA_ "GenSigSwitchedByIgnition" SG_ 278 ESP_QBit_Wegimpuls_VR 0;
BA_ "GenSigStartValue" SG_ 278 ESP_QBit_Wegimpuls_VR 1;
BA_ "GenSigSendType" SG_ 278 ESP_QBit_Wegimpuls_VR 0;
BA_ "GenSigSwitchedByIgnition" SG_ 278 ESP_QBit_Wegimpuls_HL 0;
BA_ "GenSigStartValue" SG_ 278 ESP_QBit_Wegimpuls_HL 1;
BA_ "GenSigSendType" SG_ 278 ESP_QBit_Wegimpuls_HL 0;
BA_ "GenSigSwitchedByIgnition" SG_ 278 ESP_QBit_Wegimpuls_HR 0;
BA_ "GenSigStartValue" SG_ 278 ESP_QBit_Wegimpuls_HR 1;
BA_ "GenSigSendType" SG_ 278 ESP_QBit_Wegimpuls_HR 0;
BA_ "Fehlerwert" SG_ 278 ESP_Wegimpuls_VL 1023;
BA_ "GenSigSwitchedByIgnition" SG_ 278 ESP_Wegimpuls_VL 0;
BA_ "GenSigStartValue" SG_ 278 ESP_Wegimpuls_VL 1021;
BA_ "GenSigSendType" SG_ 278 ESP_Wegimpuls_VL 0;
BA_ "Fehlerwert" SG_ 278 ESP_Wegimpuls_VR 1023;
BA_ "GenSigSwitchedByIgnition" SG_ 278 ESP_Wegimpuls_VR 0;
BA_ "GenSigStartValue" SG_ 278 ESP_Wegimpuls_VR 1021;
BA_ "GenSigSendType" SG_ 278 ESP_Wegimpuls_VR 0;
BA_ "Fehlerwert" SG_ 278 ESP_Wegimpuls_HL 1023;
BA_ "GenSigSwitchedByIgnition" SG_ 278 ESP_Wegimpuls_HL 0;
BA_ "GenSigStartValue" SG_ 278 ESP_Wegimpuls_HL 1021;
BA_ "GenSigSendType" SG_ 278 ESP_Wegimpuls_HL 0;
BA_ "Fehlerwert" SG_ 278 ESP_Wegimpuls_HR 1023;
BA_ "GenSigSwitchedByIgnition" SG_ 278 ESP_Wegimpuls_HR 0;
BA_ "GenSigStartValue" SG_ 278 ESP_Wegimpuls_HR 1021;
BA_ "GenSigSendType" SG_ 278 ESP_Wegimpuls_HR 0;
BA_ "GenSigSwitchedByIgnition" SG_ 278 ESP_VL_Fahrtrichtung 0;
BA_ "GenSigStartValue" SG_ 278 ESP_VL_Fahrtrichtung 2;
BA_ "GenSigSendType" SG_ 278 ESP_VL_Fahrtrichtung 0;
BA_ "GenSigSwitchedByIgnition" SG_ 278 ESP_VR_Fahrtrichtung 0;
BA_ "GenSigStartValue" SG_ 278 ESP_VR_Fahrtrichtung 2;
BA_ "GenSigSendType" SG_ 278 ESP_VR_Fahrtrichtung 0;
BA_ "GenSigSwitchedByIgnition" SG_ 278 ESP_HL_Fahrtrichtung 0;
BA_ "GenSigStartValue" SG_ 278 ESP_HL_Fahrtrichtung 2;
BA_ "GenSigSendType" SG_ 278 ESP_HL_Fahrtrichtung 0;
BA_ "GenSigSwitchedByIgnition" SG_ 278 ESP_HR_Fahrtrichtung 0;
BA_ "GenSigStartValue" SG_ 278 ESP_HR_Fahrtrichtung 2;
BA_ "GenSigSendType" SG_ 278 ESP_HR_Fahrtrichtung 0;
BA_ "GenSigSwitchedByIgnition" SG_ 963 Motor_03_alt 0;
BA_ "GenSigFuncType" SG_ 963 Motor_03_alt 5;
BA_ "GenSigStartValue" SG_ 963 Motor_03_alt 1;
BA_ "GenSigSendType" SG_ 963 Motor_03_alt 0;
BA_ "GenSigSwitchedByIgnition" SG_ 963 Getriebe_03_alt 0;
BA_ "GenSigFuncType" SG_ 963 Getriebe_03_alt 5;
BA_ "GenSigStartValue" SG_ 963 Getriebe_03_alt 1;
BA_ "GenSigSendType" SG_ 963 Getriebe_03_alt 0;
BA_ "GenSigSwitchedByIgnition" SG_ 963 ESP_02_alt 0;
BA_ "GenSigFuncType" SG_ 963 ESP_02_alt 5;
BA_ "GenSigStartValue" SG_ 963 ESP_02_alt 1;
BA_ "GenSigSendType" SG_ 963 ESP_02_alt 0;
BA_ "GenSigSwitchedByIgnition" SG_ 963 Motor_05_alt 0;
BA_ "GenSigFuncType" SG_ 963 Motor_05_alt 5;
BA_ "GenSigStartValue" SG_ 963 Motor_05_alt 1;
BA_ "GenSigSendType" SG_ 963 Motor_05_alt 0;
BA_ "GenSigSwitchedByIgnition" SG_ 963 LWR_AFS_01_alt 0;
BA_ "GenSigFuncType" SG_ 963 LWR_AFS_01_alt 5;
BA_ "GenSigStartValue" SG_ 963 LWR_AFS_01_alt 1;
BA_ "GenSigSendType" SG_ 963 LWR_AFS_01_alt 0;
BA_ "GenSigSwitchedByIgnition" SG_ 963 EPB_01_alt 0;
BA_ "GenSigFuncType" SG_ 963 EPB_01_alt 5;
BA_ "GenSigStartValue" SG_ 963 EPB_01_alt 1;
BA_ "GenSigSendType" SG_ 963 EPB_01_alt 0;
BA_ "GenSigSwitchedByIgnition" SG_ 963 ESP_05_alt 0;
BA_ "GenSigFuncType" SG_ 963 ESP_05_alt 5;
BA_ "GenSigStartValue" SG_ 963 ESP_05_alt 1;
BA_ "GenSigSendType" SG_ 963 ESP_05_alt 0;
BA_ "GenSigSwitchedByIgnition" SG_ 963 ESP_01_alt 0;
BA_ "GenSigFuncType" SG_ 963 ESP_01_alt 5;
BA_ "GenSigStartValue" SG_ 963 ESP_01_alt 1;
BA_ "GenSigSendType" SG_ 963 ESP_01_alt 0;
BA_ "GenSigMissingSourceValue" SG_ 963 ESP_v_Signal 65534;
BA_ "Fehlerwert" SG_ 963 ESP_v_Signal 65535;
BA_ "GenSigSwitchedByIgnition" SG_ 963 ESP_v_Signal 0;
BA_ "GenSigStartValue" SG_ 963 ESP_v_Signal 65534;
BA_ "GenSigSendType" SG_ 963 ESP_v_Signal 0;
BA_ "GenSigSwitchedByIgnition" SG_ 963 ESP_Notbremsanzeige 0;
BA_ "GenSigSendType" SG_ 963 ESP_Notbremsanzeige 0;
BA_ "GenSigSwitchedByIgnition" SG_ 963 ECD_Bremslicht 0;
BA_ "GenSigSendType" SG_ 963 ECD_Bremslicht 0;
BA_ "GenSigSwitchedByIgnition" SG_ 963 EPB_Status 0;
BA_ "GenSigSendType" SG_ 963 EPB_Status 0;
BA_ "GenSigSwitchedByIgnition" SG_ 963 MO_Anf_KL75 0;
BA_ "GenSigStartValue" SG_ 963 MO_Anf_KL75 1;
BA_ "GenSigSendType" SG_ 963 MO_Anf_KL75 0;
BA_ "GenSigSwitchedByIgnition" SG_ 963 MO_QBit_Fahrer_bremst 0;
BA_ "GenSigStartValue" SG_ 963 MO_QBit_Fahrer_bremst 1;
BA_ "GenSigSendType" SG_ 963 MO_QBit_Fahrer_bremst 0;
BA_ "GenSigSwitchedByIgnition" SG_ 963 EPB_BCM2_Motor_Wakeup 0;
BA_ "GenSigSendType" SG_ 963 EPB_BCM2_Motor_Wakeup 0;
BA_ "GenSigSwitchedByIgnition" SG_ 963 ESP_QBit_v_Signal 0;
BA_ "GenSigStartValue" SG_ 963 ESP_QBit_v_Signal 1;
BA_ "GenSigSendType" SG_ 963 ESP_QBit_v_Signal 0;
BA_ "Fehlerwert" SG_ 963 GE_Waehlhebel 15;
BA_ "GenSigSwitchedByIgnition" SG_ 963 GE_Waehlhebel 0;
BA_ "GenSigStartValue" SG_ 963 GE_Waehlhebel 1;
BA_ "GenSigSendType" SG_ 963 GE_Waehlhebel 0;
BA_ "GenSigSwitchedByIgnition" SG_ 963 MO_Motor_laeuft 0;
BA_ "GenSigSendType" SG_ 963 MO_Motor_laeuft 0;
BA_ "GenSigSwitchedByIgnition" SG_ 963 MO_Verbot_EKP 0;
BA_ "GenSigSendType" SG_ 963 MO_Verbot_EKP 0;
BA_ "GenSigSwitchedByIgnition" SG_ 963 MO_Anf_Pruefimpuls 0;
BA_ "GenSigSendType" SG_ 963 MO_Anf_Pruefimpuls 0;
BA_ "GenSigSendType" SG_ 963 LWR_Touristenmodus_aktiv 0;
BA_ "Fehlerwert" SG_ 963 MO_Drehzahl_01 65535;
BA_ "GenSigSwitchedByIgnition" SG_ 963 MO_Drehzahl_01 0;
BA_ "GenSigSendType" SG_ 963 MO_Drehzahl_01 0;
BA_ "GenSigSwitchedByIgnition" SG_ 963 MO_Klima_Eingr 0;
BA_ "GenSigSendType" SG_ 963 MO_Klima_Eingr 0;
BA_ "GenSigSwitchedByIgnition" SG_ 963 MO_BLS 0;
BA_ "GenSigSendType" SG_ 963 MO_BLS 0;
BA_ "GenSigSwitchedByIgnition" SG_ 963 MO_Fahrer_bremst 0;
BA_ "GenSigSendType" SG_ 963 MO_Fahrer_bremst 0;
BA_ "GenSigSwitchedByIgnition" SG_ 963 MO_Aussp_Anlass 0;
BA_ "GenSigSendType" SG_ 963 MO_Aussp_Anlass 0;
BA_ "GenSigSwitchedByIgnition" SG_ 963 MO_Freig_Anlass 0;
BA_ "GenSigSendType" SG_ 963 MO_Freig_Anlass 0;
BA_ "GenSigSwitchedByIgnition" SG_ 963 MO_Kuppl_schalter 0;
BA_ "GenSigSendType" SG_ 963 MO_Kuppl_schalter 0;
BA_ "GenSigSwitchedByIgnition" SG_ 963 MO_Interlock 0;
BA_ "GenSigSendType" SG_ 963 MO_Interlock 0;
BA_ "GenSigSwitchedByIgnition" SG_ 1643 Motor_07_alt 0;
BA_ "GenSigFuncType" SG_ 1643 Motor_07_alt 5;
BA_ "GenSigStartValue" SG_ 1643 Motor_07_alt 1;
BA_ "GenSigSendType" SG_ 1643 Motor_07_alt 0;
BA_ "GenSigSwitchedByIgnition" SG_ 1643 Motor_Code_01_alt 0;
BA_ "GenSigFuncType" SG_ 1643 Motor_Code_01_alt 5;
BA_ "GenSigStartValue" SG_ 1643 Motor_Code_01_alt 1;
BA_ "GenSigSendType" SG_ 1643 Motor_Code_01_alt 0;
BA_ "GenSigSwitchedByIgnition" SG_ 1643 Kombi_02_alt 0;
BA_ "GenSigFuncType" SG_ 1643 Kombi_02_alt 5;
BA_ "GenSigStartValue" SG_ 1643 Kombi_02_alt 1;
BA_ "GenSigSendType" SG_ 1643 Kombi_02_alt 0;
BA_ "GenSigFuncType" SG_ 1643 Telefon_01_alt 5;
BA_ "GenSigStartValue" SG_ 1643 Telefon_01_alt 1;
BA_ "GenSigSendType" SG_ 1643 Telefon_01_alt 0;
BA_ "GenSigSwitchedByIgnition" SG_ 1643 EPB_01_alt 0;
BA_ "GenSigFuncType" SG_ 1643 EPB_01_alt 5;
BA_ "GenSigStartValue" SG_ 1643 EPB_01_alt 1;
BA_ "GenSigSendType" SG_ 1643 EPB_01_alt 0;
BA_ "GenSigSwitchedByIgnition" SG_ 1643 Motor_05_alt 0;
BA_ "GenSigFuncType" SG_ 1643 Motor_05_alt 5;
BA_ "GenSigStartValue" SG_ 1643 Motor_05_alt 1;
BA_ "GenSigSendType" SG_ 1643 Motor_05_alt 0;
BA_ "GenSigSwitchedByIgnition" SG_ 1643 Motor_06_alt 0;
BA_ "GenSigFuncType" SG_ 1643 Motor_06_alt 5;
BA_ "GenSigStartValue" SG_ 1643 Motor_06_alt 1;
BA_ "GenSigSendType" SG_ 1643 Motor_06_alt 0;
BA_ "Fehlerwert" SG_ 1643 MO_Kuehlmittel_Temp 255;
BA_ "GenSigSwitchedByIgnition" SG_ 1643 MO_Kuehlmittel_Temp 0;
BA_ "GenSigStartValue" SG_ 1643 MO_Kuehlmittel_Temp 254;
BA_ "GenSigSendType" SG_ 1643 MO_Kuehlmittel_Temp 0;
BA_ "Fehlerwert" SG_ 1643 KBI_Aussen_Temp_gef 255;
BA_ "GenSigSwitchedByIgnition" SG_ 1643 KBI_Aussen_Temp_gef 0;
BA_ "GenSigStartValue" SG_ 1643 KBI_Aussen_Temp_gef 254;
BA_ "GenSigSendType" SG_ 1643 KBI_Aussen_Temp_gef 0;
BA_ "GenSigSwitchedByIgnition" SG_ 1643 MO_Kraftstoffart 0;
BA_ "GenSigFuncType" SG_ 1643 MO_Kraftstoffart 8;
BA_ "GenSigSendType" SG_ 1643 MO_Kraftstoffart 0;
BA_ "GenSigSwitchedByIgnition" SG_ 1643 MO_Kennfeldk 0;
BA_ "GenSigSendType" SG_ 1643 MO_Kennfeldk 0;
BA_ "GenSigSwitchedByIgnition" SG_ 1643 KBI_QBit_Aussen_Temp_gef 0;
BA_ "GenSigStartValue" SG_ 1643 KBI_QBit_Aussen_Temp_gef 1;
BA_ "GenSigSendType" SG_ 1643 KBI_QBit_Aussen_Temp_gef 0;
BA_ "GenSigSwitchedByIgnition" SG_ 1643 MO_Absperrventil_oeffnen 0;
BA_ "GenSigSendType" SG_ 1643 MO_Absperrventil_oeffnen 0;
BA_ "GenSigSwitchedByIgnition" SG_ 1643 KBI_Standzeit 0;
BA_ "GenSigSendType" SG_ 1643 KBI_Standzeit 0;
BA_ "GenSigSwitchedByIgnition" SG_ 1643 KBI_Reset_Standzeit 0;
BA_ "GenSigSendType" SG_ 1643 KBI_Reset_Standzeit 0;
BA_ "GenSigSendType" SG_ 1643 TF_Phone_mute 3;
BA_ "GenSigSwitchedByIgnition" SG_ 1643 EPB_QBit_Pedalweg_Kuppl 0;
BA_ "GenSigStartValue" SG_ 1643 EPB_QBit_Pedalweg_Kuppl 1;
BA_ "GenSigSendType" SG_ 1643 EPB_QBit_Pedalweg_Kuppl 0;
BA_ "GenSigSendType" SG_ 1643 TF_Mute_Msg_Code 3;
BA_ "GenSigSwitchedByIgnition" SG_ 1643 MO_HYB_Fahrbereitschaft 0;
BA_ "GenSigSendType" SG_ 1643 MO_HYB_Fahrbereitschaft 0;
BA_ "GenSigSwitchedByIgnition" SG_ 1643 MO_EKlKomLeiRed 0;
BA_ "GenSigSendType" SG_ 1643 MO_EKlKomLeiRed 0;
BA_ "Fehlerwert" SG_ 1643 EPB_Pedalweg_Kuppl 255;
BA_ "GenSigSwitchedByIgnition" SG_ 1643 EPB_Pedalweg_Kuppl 0;
BA_ "GenSigSendType" SG_ 1643 EPB_Pedalweg_Kuppl 0;
BA_ "GenSigSwitchedByIgnition" SG_ 924 BCM1_02_alt 0;
BA_ "GenSigFuncType" SG_ 924 BCM1_02_alt 5;
BA_ "GenSigStartValue" SG_ 924 BCM1_02_alt 1;
BA_ "GenSigSendType" SG_ 924 BCM1_02_alt 0;
BA_ "GenSigSwitchedByIgnition" SG_ 924 Wischer_01_alt 0;
BA_ "GenSigFuncType" SG_ 924 Wischer_01_alt 5;
BA_ "GenSigStartValue" SG_ 924 Wischer_01_alt 1;
BA_ "GenSigSendType" SG_ 924 Wischer_01_alt 0;
BA_ "GenSigSwitchedByIgnition" SG_ 924 Klima_02_alt 0;
BA_ "GenSigFuncType" SG_ 924 Klima_02_alt 5;
BA_ "GenSigStartValue" SG_ 924 Klima_02_alt 1;
BA_ "GenSigSendType" SG_ 924 Klima_02_alt 0;
BA_ "GenSigSwitchedByIgnition" SG_ 924 BCM1_01_alt 0;
BA_ "GenSigFuncType" SG_ 924 BCM1_01_alt 5;
BA_ "GenSigStartValue" SG_ 924 BCM1_01_alt 1;
BA_ "GenSigSendType" SG_ 924 BCM1_01_alt 0;
BA_ "GenSigSwitchedByIgnition" SG_ 924 ESP_07_alt 0;
BA_ "GenSigFuncType" SG_ 924 ESP_07_alt 5;
BA_ "GenSigStartValue" SG_ 924 ESP_07_alt 1;
BA_ "GenSigSendType" SG_ 924 ESP_07_alt 0;
BA_ "GenSigSwitchedByIgnition" SG_ 924 TSG_BT_1_alt 0;
BA_ "GenSigFuncType" SG_ 924 TSG_BT_1_alt 5;
BA_ "GenSigStartValue" SG_ 924 TSG_BT_1_alt 1;
BA_ "GenSigSendType" SG_ 924 TSG_BT_1_alt 0;
BA_ "GenSigFuncType" SG_ 924 TSG_HL_1_alt 5;
BA_ "GenSigStartValue" SG_ 924 TSG_HL_1_alt 1;
BA_ "GenSigSendType" SG_ 924 TSG_HL_1_alt 0;
BA_ "GenSigFuncType" SG_ 924 TSG_HR_1_alt 5;
BA_ "GenSigStartValue" SG_ 924 TSG_HR_1_alt 1;
BA_ "GenSigSendType" SG_ 924 TSG_HR_1_alt 0;
BA_ "GenSigSwitchedByIgnition" SG_ 924 Motor_02_alt 0;
BA_ "GenSigFuncType" SG_ 924 Motor_02_alt 5;
BA_ "GenSigStartValue" SG_ 924 Motor_02_alt 1;
BA_ "GenSigSendType" SG_ 924 Motor_02_alt 0;
BA_ "GenSigSwitchedByIgnition" SG_ 924 Klima_Sensor_02_alt 0;
BA_ "GenSigFuncType" SG_ 924 Klima_Sensor_02_alt 5;
BA_ "GenSigStartValue" SG_ 924 Klima_Sensor_02_alt 1;
BA_ "GenSigSendType" SG_ 924 Klima_Sensor_02_alt 0;
BA_ "GenSigSwitchedByIgnition" SG_ 924 TSG_FT_1_alt 0;
BA_ "GenSigFuncType" SG_ 924 TSG_FT_1_alt 5;
BA_ "GenSigStartValue" SG_ 924 TSG_FT_1_alt 1;
BA_ "GenSigSendType" SG_ 924 TSG_FT_1_alt 0;
BA_ "GenSigSwitchedByIgnition" SG_ 924 Motor_05_alt 0;
BA_ "GenSigFuncType" SG_ 924 Motor_05_alt 5;
BA_ "GenSigStartValue" SG_ 924 Motor_05_alt 1;
BA_ "GenSigSendType" SG_ 924 Motor_05_alt 0;
BA_ "GenSigFuncType" SG_ 924 QSP_01_alt 5;
BA_ "GenSigStartValue" SG_ 924 QSP_01_alt 1;
BA_ "GenSigSendType" SG_ 924 QSP_01_alt 0;
BA_ "GenSigFuncType" SG_ 924 Parkhilfe_01_alt 5;
BA_ "GenSigStartValue" SG_ 924 Parkhilfe_01_alt 1;
BA_ "GenSigSendType" SG_ 924 Parkhilfe_01_alt 0;
BA_ "GenSigFuncType" SG_ 924 Fahrwerk_02_alt 5;
BA_ "GenSigStartValue" SG_ 924 Fahrwerk_02_alt 1;
BA_ "GenSigSendType" SG_ 924 Fahrwerk_02_alt 0;
BA_ "GenSigStartValue" SG_ 924 GW_05_va_27 1;
BA_ "GenSigSendType" SG_ 924 GW_05_va_27 0;
BA_ "GenSigSwitchedByIgnition" SG_ 924 BCM1_MH_WIV_Schalter 0;
BA_ "GenSigSendType" SG_ 924 BCM1_MH_WIV_Schalter 3;
BA_ "GenSigSwitchedByIgnition" SG_ 924 Wischer_vorne_aktiv 0;
BA_ "GenSigSendType" SG_ 924 Wischer_vorne_aktiv 3;
BA_ "GenSigSwitchedByIgnition" SG_ 924 BCM1_Rueckfahrlicht_Schalter 0;
BA_ "GenSigSendType" SG_ 924 BCM1_Rueckfahrlicht_Schalter 0;
BA_ "GenSigSwitchedByIgnition" SG_ 924 MO_Status_Normalbetrieb_01 0;
BA_ "GenSigSendType" SG_ 924 MO_Status_Normalbetrieb_01 0;
BA_ "GenSigSwitchedByIgnition" SG_ 924 KL_Zuheizer_Freigabe 0;
BA_ "GenSigSendType" SG_ 924 KL_Zuheizer_Freigabe 3;
BA_ "GenSigSwitchedByIgnition" SG_ 924 BCM1_Vorwaertsgang_eingelegt 0;
BA_ "GenSigSendType" SG_ 924 BCM1_Vorwaertsgang_eingelegt 0;
BA_ "GenSigSwitchedByIgnition" SG_ 924 ESP_Codierung_ADS 0;
BA_ "GenSigFuncType" SG_ 924 ESP_Codierung_ADS 8;
BA_ "GenSigSendType" SG_ 924 ESP_Codierung_ADS 0;
BA_ "GenSigSendType" SG_ 924 QSP_StartStopp_Info 0;
BA_ "GenSigSendType" SG_ 924 FA_StartStopp_Info 0;
BA_ "GenSigSendType" SG_ 924 PH_StartStopp_Info 3;
BA_ "GenSigSwitchedByIgnition" SG_ 924 KL_Beschlagsgefahr 0;
BA_ "GenSigSendType" SG_ 924 KL_Beschlagsgefahr 3;
BA_ "GenSigSwitchedByIgnition" SG_ 924 BCM1_GLW_Fernlicht_Anf 0;
BA_ "GenSigSendType" SG_ 924 BCM1_GLW_Fernlicht_Anf 3;
BA_ "GenSigSwitchedByIgnition" SG_ 924 BCM1_RFahrlicht_Fzg_Anf 0;
BA_ "GenSigSendType" SG_ 924 BCM1_RFahrlicht_Fzg_Anf 0;
BA_ "GenSigSwitchedByIgnition" SG_ 924 FT_Tuer_geoeffnet 0;
BA_ "GenSigSendType" SG_ 924 FT_Tuer_geoeffnet 3;
BA_ "GenSigSwitchedByIgnition" SG_ 924 MO_Handshake_STH 0;
BA_ "GenSigSendType" SG_ 924 MO_Handshake_STH 3;
BA_ "GenSigSwitchedByIgnition" SG_ 924 FT_Sperrklinke 0;
BA_ "GenSigSendType" SG_ 924 FT_Sperrklinke 3;
BA_ "GenSigSwitchedByIgnition" SG_ 924 BCM1_OBD_FStatus_ATemp 0;
BA_ "GenSigSendType" SG_ 924 BCM1_OBD_FStatus_ATemp 0;
BA_ "Fehlerwert" SG_ 924 BCM1_Aussen_Temp_ungef 255;
BA_ "GenSigSwitchedByIgnition" SG_ 924 BCM1_Aussen_Temp_ungef 0;
BA_ "GenSigStartValue" SG_ 924 BCM1_Aussen_Temp_ungef 254;
BA_ "GenSigSendType" SG_ 924 BCM1_Aussen_Temp_ungef 0;
BA_ "GenSigSwitchedByIgnition" SG_ 924 BCM1_Oeldruck_Schalter 0;
BA_ "GenSigSendType" SG_ 924 BCM1_Oeldruck_Schalter 3;
BA_ "GenSigSwitchedByIgnition" SG_ 924 BCM1_Oeldruck_Schalter_2 0;
BA_ "GenSigSendType" SG_ 924 BCM1_Oeldruck_Schalter_2 3;
BA_ "GenSigSwitchedByIgnition" SG_ 924 BT_Tuer_geoeffnet 0;
BA_ "GenSigSendType" SG_ 924 BT_Tuer_geoeffnet 3;
BA_ "GenSigSendType" SG_ 924 HL_Tuer_geoeffnet 3;
BA_ "GenSigSendType" SG_ 924 HR_Tuer_geoeffnet 3;
BA_ "GenSigSwitchedByIgnition" SG_ 924 BCM1_Adaptive_Lichtvert_Anf 0;
BA_ "GenSigSendType" SG_ 924 BCM1_Adaptive_Lichtvert_Anf 3;
BA_ "GenSigSwitchedByIgnition" SG_ 924 BCM1_Gleitende_Leuchtw_Anf 0;
BA_ "GenSigSendType" SG_ 924 BCM1_Gleitende_Leuchtw_Anf 3;
BA_ "GenSigSwitchedByIgnition" SG_ 924 BCM1_Schalter_StartStopp 0;
BA_ "GenSigStartValue" SG_ 924 BCM1_Schalter_StartStopp 1;
BA_ "GenSigSendType" SG_ 924 BCM1_Schalter_StartStopp 0;
BA_ "GenSigSendType" SG_ 924 ESP_Offroad_Modus 0;
BA_ "GenSigSwitchedByIgnition" SG_ 924 MO_Freig_Reku 0;
BA_ "GenSigSendType" SG_ 924 MO_Freig_Reku 0;
BA_ "GenSigSendType" SG_ 924 KL_HSH_ein_Soll 3;
BA_ "GenSigSendType" SG_ 924 FT_Tuerkontakt_Rohsignal 3;
BA_ "GenSigFuncType" SG_ 1318 Klima_Sensor_02_alt 5;
BA_ "GenSigStartValue" SG_ 1318 Klima_Sensor_02_alt 1;
BA_ "GenSigSendType" SG_ 1318 Klima_Sensor_02_alt 0;
BA_ "GenSigFuncType" SG_ 1318 Wischer_01_alt 5;
BA_ "GenSigStartValue" SG_ 1318 Wischer_01_alt 1;
BA_ "GenSigSendType" SG_ 1318 Wischer_01_alt 0;
BA_ "GenSigFuncType" SG_ 1318 SMLS_01_alt 5;
BA_ "GenSigStartValue" SG_ 1318 SMLS_01_alt 1;
BA_ "GenSigSendType" SG_ 1318 SMLS_01_alt 0;
BA_ "GenSigFuncType" SG_ 1318 Kessy_02_alt 5;
BA_ "GenSigStartValue" SG_ 1318 Kessy_02_alt 1;
BA_ "GenSigSendType" SG_ 1318 Kessy_02_alt 0;
BA_ "GenSigStartValue" SG_ 1318 Blinkmodi_01_inaktiv 1;
BA_ "GenSigSendType" SG_ 1318 Blinkmodi_01_inaktiv 0;
BA_ "GenSigFuncType" SG_ 1318 Anhaenger_01_alt 5;
BA_ "GenSigStartValue" SG_ 1318 Anhaenger_01_alt 1;
BA_ "GenSigSendType" SG_ 1318 Anhaenger_01_alt 0;
BA_ "GenSigFuncType" SG_ 1318 BCM1_01_alt 5;
BA_ "GenSigStartValue" SG_ 1318 BCM1_01_alt 1;
BA_ "GenSigSendType" SG_ 1318 BCM1_01_alt 0;
BA_ "GenSigFuncType" SG_ 1318 BCM1_02_alt 5;
BA_ "GenSigStartValue" SG_ 1318 BCM1_02_alt 1;
BA_ "GenSigSendType" SG_ 1318 BCM1_02_alt 0;
BA_ "GenSigFuncType" SG_ 1318 Innenlicht_01_alt 5;
BA_ "GenSigStartValue" SG_ 1318 Innenlicht_01_alt 1;
BA_ "GenSigSendType" SG_ 1318 Innenlicht_01_alt 0;
BA_ "GenSigFuncType" SG_ 1318 BCM2_02_alt 5;
BA_ "GenSigStartValue" SG_ 1318 BCM2_02_alt 1;
BA_ "GenSigSendType" SG_ 1318 BCM2_02_alt 0;
BA_ "GenSigSwitchedByIgnition" SG_ 1318 Motor_06_alt 0;
BA_ "GenSigFuncType" SG_ 1318 Motor_06_alt 5;
BA_ "GenSigStartValue" SG_ 1318 Motor_06_alt 1;
BA_ "GenSigSendType" SG_ 1318 Motor_06_alt 0;
BA_ "GenSigFuncType" SG_ 1318 HUD_01_alt 5;
BA_ "GenSigStartValue" SG_ 1318 HUD_01_alt 1;
BA_ "GenSigSendType" SG_ 1318 HUD_01_alt 0;
BA_ "GenSigFuncType" SG_ 1318 TSG_FT_01_alt 5;
BA_ "GenSigStartValue" SG_ 1318 TSG_FT_01_alt 1;
BA_ "GenSigSendType" SG_ 1318 TSG_FT_01_alt 0;
BA_ "GenSigStartValue" SG_ 1318 GW_07_va_25 1;
BA_ "GenSigSendType" SG_ 1318 GW_07_va_25 0;
BA_ "GenSigStartValue" SG_ 1318 GW_07_va_26 1;
BA_ "GenSigSendType" SG_ 1318 GW_07_va_26 0;
BA_ "GenSigStartValue" SG_ 1318 GW_07_va_27 1;
BA_ "GenSigSendType" SG_ 1318 GW_07_va_27 0;
BA_ "Fehlerwert" SG_ 1318 BCM1_Aussen_Temp_ungef 255;
BA_ "GenSigStartValue" SG_ 1318 BCM1_Aussen_Temp_ungef 254;
BA_ "GenSigSendType" SG_ 1318 BCM1_Aussen_Temp_ungef 0;
BA_ "GenSigStartValue" SG_ 1318 BCM1_FStatus_Aussentemp_ungef 1;
BA_ "GenSigSendType" SG_ 1318 BCM1_FStatus_Aussentemp_ungef 0;
BA_ "GenSigSendType" SG_ 1318 Wischer_vorne_aktiv 3;
BA_ "GenSigSendType" SG_ 1318 BH_Blinker_li 4;
BA_ "GenSigActiveRepetitions" SG_ 1318 BH_Blinker_li 5;
BA_ "GenSigSendType" SG_ 1318 BH_Blinker_re 4;
BA_ "GenSigActiveRepetitions" SG_ 1318 BH_Blinker_re 5;
BA_ "GenSigSendType" SG_ 1318 KY_Funkschl_Nr 3;
BA_ "GenSigSendType" SG_ 1318 BCM1_Rueckfahrlicht_Schalter 0;
BA_ "GenSigSendType" SG_ 1318 AAG_Anhaenger_erkannt 0;
BA_ "GenSigSendType" SG_ 1318 BM_links 6;
BA_ "GenSigActiveRepetitions" SG_ 1318 BM_links 5;
BA_ "GenSigSendType" SG_ 1318 BM_rechts 6;
BA_ "GenSigActiveRepetitions" SG_ 1318 BM_rechts 5;
BA_ "GenSigSendType" SG_ 1318 BH_Fernlicht 3;
BA_ "GenSigSendType" SG_ 1318 LDW_Taster 3;
BA_ "GenSigSendType" SG_ 1318 LDW_Taster_Fehler 3;
BA_ "GenSigSendType" SG_ 1318 LDW_Vib_Lenkrad_Fehler 3;
BA_ "GenSigSendType" SG_ 1318 LV_Fernlicht_Anzeige 3;
BA_ "GenSigSendType" SG_ 1318 LV_Abblendlicht_Anzeige 3;
BA_ "GenSigSendType" SG_ 1318 LV_Nebellicht_Anzeige 3;
BA_ "GenSigStartValue" SG_ 1318 IL_Innenlicht_aktiv 1;
BA_ "GenSigSendType" SG_ 1318 IL_Innenlicht_aktiv 3;
BA_ "GenSigSendType" SG_ 1318 BCM1_MH_Schalter 3;
BA_ "GenSigSendType" SG_ 1318 ZV_FT_offen 3;
BA_ "GenSigSendType" SG_ 1318 ZV_BT_offen 3;
BA_ "GenSigSendType" SG_ 1318 ZV_HL_offen 3;
BA_ "GenSigSendType" SG_ 1318 ZV_HR_offen 3;
BA_ "GenSigSendType" SG_ 1318 ZV_HD_offen 3;
BA_ "GenSigSendType" SG_ 1318 ZV_verriegelt_extern_ist 3;
BA_ "GenSigSendType" SG_ 1318 ZV_ist_Zustand_verfuegbar 3;
BA_ "GenSigSendType" SG_ 1318 BCM1_NV_Taster 0;
BA_ "GenSigSwitchedByIgnition" SG_ 1318 MO_HYB_Fahrbereitschaft 0;
BA_ "GenSigSendType" SG_ 1318 MO_HYB_Fahrbereitschaft 0;
BA_ "GenSigSendType" SG_ 1318 HUD_VZE_in_Anzeige 3;
BA_ "GenSigSendType" SG_ 1318 FT_SWA_Taster 3;
BA_ "GenSigSendType" SG_ 1318 FT_SWA_Tasterdiagnose 3;
BA_ "GenSigSwitchedByIgnition" SG_ 258 Getriebe_03_CHK 0;
BA_ "GenSigFuncType" SG_ 258 Getriebe_03_CHK 3;
BA_ "GenSigSendType" SG_ 258 Getriebe_03_CHK 0;
BA_ "GenSigSwitchedByIgnition" SG_ 258 Getriebe_03_BZ 0;
BA_ "GenSigFuncType" SG_ 258 Getriebe_03_BZ 1;
BA_ "GenSigSendType" SG_ 258 Getriebe_03_BZ 0;
BA_ "GenSigSwitchedByIgnition" SG_ 258 GE_Freig_Langfr_Schutzmom 0;
BA_ "GenSigSendType" SG_ 258 GE_Freig_Langfr_Schutzmom 0;
BA_ "Fehlerwert" SG_ 258 GE_Uefkt 1023;
BA_ "GenSigSwitchedByIgnition" SG_ 258 GE_Uefkt 0;
BA_ "GenSigSendType" SG_ 258 GE_Uefkt 0;
BA_ "Fehlerwert" SG_ 258 GE_Zielgang 15;
BA_ "GenSigSwitchedByIgnition" SG_ 258 GE_Zielgang 0;
BA_ "GenSigSendType" SG_ 258 GE_Zielgang 0;
BA_ "GenSigSwitchedByIgnition" SG_ 258 GE_StartStopp_Info 0;
BA_ "GenSigSendType" SG_ 258 GE_StartStopp_Info 0;
BA_ "Fehlerwert" SG_ 258 GE_Langfr_Schutzmom 1023;
BA_ "GenSigSwitchedByIgnition" SG_ 258 GE_Langfr_Schutzmom 0;
BA_ "GenSigStartValue" SG_ 258 GE_Langfr_Schutzmom 1022;
BA_ "GenSigSendType" SG_ 258 GE_Langfr_Schutzmom 0;
BA_ "GenSigSwitchedByIgnition" SG_ 258 GE_Performance_Start_LB 0;
BA_ "GenSigSendType" SG_ 258 GE_Performance_Start_LB 0;
BA_ "GenSigSwitchedByIgnition" SG_ 258 GE_reserv_Waehlhebel 0;
BA_ "GenSigSendType" SG_ 258 GE_reserv_Waehlhebel 0;
BA_ "Fehlerwert" SG_ 258 GE_Waehlhebel 15;
BA_ "GenSigSwitchedByIgnition" SG_ 258 GE_Waehlhebel 0;
BA_ "GenSigStartValue" SG_ 258 GE_Waehlhebel 1;
BA_ "GenSigSendType" SG_ 258 GE_Waehlhebel 0;
BA_ "Fehlerwert" SG_ 258 GE_Eingangsdrehz 16383;
BA_ "GenSigSwitchedByIgnition" SG_ 258 GE_Eingangsdrehz 0;
BA_ "GenSigStartValue" SG_ 258 GE_Eingangsdrehz 16382;
BA_ "GenSigSendType" SG_ 258 GE_Eingangsdrehz 0;
BA_ "GenSigSwitchedByIgnition" SG_ 258 GE_Notlauf 0;
BA_ "GenSigSendType" SG_ 258 GE_Notlauf 0;
BA_ "GenSigSwitchedByIgnition" SG_ 258 GE_Codierung_MSG 0;
BA_ "GenSigSendType" SG_ 258 GE_Codierung_MSG 0;
BA_ "GenSigMissingSourceValue" SG_ 1612 GW_Karosserie_Typ 21;
BA_ "GenSigSwitchedByIgnition" SG_ 1612 GW_Karosserie_Typ 0;
BA_ "NWM-WakeupAllowed" SG_ 1612 GW_Karosserie_Typ 1;
BA_ "GenSigSendType" SG_ 1612 GW_Karosserie_Typ 0;
BA_ "GenSigMissingSourceValue" SG_ 1612 GW_Lenker 21;
BA_ "GenSigSwitchedByIgnition" SG_ 1612 GW_Lenker 0;
BA_ "NWM-WakeupAllowed" SG_ 1612 GW_Lenker 1;
BA_ "GenSigSendType" SG_ 1612 GW_Lenker 0;
BA_ "GenSigMissingSourceValue" SG_ 1612 GW_Baureihe 21;
BA_ "GenSigSwitchedByIgnition" SG_ 1612 GW_Baureihe 0;
BA_ "NWM-WakeupAllowed" SG_ 1612 GW_Baureihe 1;
BA_ "GenSigSendType" SG_ 1612 GW_Baureihe 0;
BA_ "GenSigMissingSourceValue" SG_ 1612 GW_Fzg_Antrieb 21;
BA_ "GenSigSwitchedByIgnition" SG_ 1612 GW_Fzg_Antrieb 0;
BA_ "NWM-WakeupAllowed" SG_ 1612 GW_Fzg_Antrieb 1;
BA_ "GenSigSendType" SG_ 1612 GW_Fzg_Antrieb 0;
BA_ "GenSigSwitchedByIgnition" SG_ 909 BCM1_Rueckfahrlicht_Schalter 0;
BA_ "GenSigSendType" SG_ 909 BCM1_Rueckfahrlicht_Schalter 0;
BA_ "GenSigSendType" SG_ 909 HD_Bewegung_zu 0;
BA_ "GenSigSwitchedByIgnition" SG_ 909 KY1_FuSchl_Nr_Zugang 0;
BA_ "GenSigSendType" SG_ 909 KY1_FuSchl_Nr_Zugang 3;
BA_ "GenSigSendType" SG_ 909 VS_VD_Bew_auf 3;
BA_ "GenSigSendType" SG_ 909 VS_VD_Bew_zu 3;
BA_ "GenSigSendType" SG_ 909 VS_VD_Fehler 3;
BA_ "GenSigSwitchedByIgnition" SG_ 909 F_Kessy_01_Mmi 0;
BA_ "NWM-WakeupAllowed" SG_ 909 F_Kessy_01_Mmi 1;
BA_ "GenSigStartValue" SG_ 909 F_Kessy_01_Mmi 1;
BA_ "GenSigSendType" SG_ 909 F_Kessy_01_Mmi 0;
BA_ "NWM-WakeupAllowed" SG_ 909 F_HDSG_01_Mmi 1;
BA_ "GenSigStartValue" SG_ 909 F_HDSG_01_Mmi 1;
BA_ "GenSigSendType" SG_ 909 F_HDSG_01_Mmi 0;
BA_ "GenSigSwitchedByIgnition" SG_ 909 F_BCM1_01_Mmi 0;
BA_ "NWM-WakeupAllowed" SG_ 909 F_BCM1_01_Mmi 1;
BA_ "GenSigStartValue" SG_ 909 F_BCM1_01_Mmi 1;
BA_ "GenSigSendType" SG_ 909 F_BCM1_01_Mmi 0;
BA_ "NWM-WakeupAllowed" SG_ 909 F_VSG_01_Mmi 1;
BA_ "GenSigStartValue" SG_ 909 F_VSG_01_Mmi 1;
BA_ "GenSigSendType" SG_ 909 F_VSG_01_Mmi 0;
BA_ "NWM-WakeupAllowed" SG_ 1514 PDCC_W_gelb 1;
BA_ "GenSigSendType" SG_ 1514 PDCC_W_gelb 0;
BA_ "NWM-WakeupAllowed" SG_ 1514 PDCC_W_rot 1;
BA_ "GenSigSendType" SG_ 1514 PDCC_W_rot 0;
BA_ "GenSigSendType" SG_ 1514 DR_Gelbe_Warnlampe 0;
BA_ "NWM-WakeupAllowed" SG_ 1514 Ni_Anzeige_WaMe_gelb 1;
BA_ "GenSigSendType" SG_ 1514 Ni_Anzeige_WaMe_gelb 3;
BA_ "NWM-WakeupAllowed" SG_ 1514 Ni_Anzeige_WaMe_rot 1;
BA_ "GenSigSendType" SG_ 1514 Ni_Anzeige_WaMe_rot 3;
BA_ "NWM-WakeupAllowed" SG_ 1514 PDCC_St_Stabi 1;
BA_ "GenSigSendType" SG_ 1514 PDCC_St_Stabi 0;
BA_ "NWM-WakeupAllowed" SG_ 1514 PDCC_W_Oel 1;
BA_ "GenSigSendType" SG_ 1514 PDCC_W_Oel 0;
BA_ "GenSigSendType" SG_ 1514 DR_Rote_Warnlampe 0;
BA_ "GenSigSendType" SG_ 1514 DR_DynAGL_Warnlampe 0;
BA_ "NWM-WakeupAllowed" SG_ 1514 F_Fahrwerk_05_Mmi 1;
BA_ "GenSigStartValue" SG_ 1514 F_Fahrwerk_05_Mmi 1;
BA_ "GenSigSendType" SG_ 1514 F_Fahrwerk_05_Mmi 0;
BA_ "GenSigSwitchedByIgnition" SG_ 1514 F_Daempfer_01_FR_Mmi 0;
BA_ "NWM-WakeupAllowed" SG_ 1514 F_Daempfer_01_FR_Mmi 1;
BA_ "GenSigStartValue" SG_ 1514 F_Daempfer_01_FR_Mmi 1;
BA_ "GenSigSendType" SG_ 1514 F_Daempfer_01_FR_Mmi 0;
BA_ "NWM-WakeupAllowed" SG_ 1514 F_PDCC_01_Mmi 1;
BA_ "GenSigStartValue" SG_ 1514 F_PDCC_01_Mmi 1;
BA_ "GenSigSendType" SG_ 1514 F_PDCC_01_Mmi 0;
BA_ "Fehlerwert" SG_ 796 MO_Drehzahl_01 65535;
BA_ "GenSigSwitchedByIgnition" SG_ 796 MO_Drehzahl_01 0;
BA_ "GenSigSendType" SG_ 796 MO_Drehzahl_01 0;
BA_ "Fehlerwert" SG_ 796 MO_Kuehlmittel_Temp 255;
BA_ "GenSigSwitchedByIgnition" SG_ 796 MO_Kuehlmittel_Temp 0;
BA_ "GenSigStartValue" SG_ 796 MO_Kuehlmittel_Temp 254;
BA_ "GenSigSendType" SG_ 796 MO_Kuehlmittel_Temp 0;
BA_ "GenSigSendType" SG_ 796 DR_Daempferreg_Texte 0;
BA_ "GenSigSwitchedByIgnition" SG_ 796 MO_Ext_E_Fahrt_aktiv 0;
BA_ "NWM-WakeupAllowed" SG_ 796 MO_Ext_E_Fahrt_aktiv 1;
BA_ "GenSigSendType" SG_ 796 MO_Ext_E_Fahrt_aktiv 0;
BA_ "GenSigSendType" SG_ 796 MO_HYB_VM_aktiv 0;
BA_ "GenSigSwitchedByIgnition" SG_ 796 MO_Fehler_MSpG 0;
BA_ "GenSigSendType" SG_ 796 MO_Fehler_MSpG 0;
BA_ "GenSigSwitchedByIgnition" SG_ 796 MO_Overboost 0;
BA_ "GenSigSendType" SG_ 796 MO_Overboost 0;
BA_ "GenSigSendType" SG_ 796 DR_Systemstatus 0;
BA_ "GenSigSendType" SG_ 796 FA_Reglerstatus_Niveau 0;
BA_ "GenSigSwitchedByIgnition" SG_ 796 GE_Segel_Status 0;
BA_ "GenSigSendType" SG_ 796 GE_Segel_Status 0;
BA_ "GenSigSwitchedByIgnition" SG_ 796 GE_Status_PaddleNeutral 0;
BA_ "GenSigSendType" SG_ 796 GE_Status_PaddleNeutral 0;
BA_ "GenSigSwitchedByIgnition" SG_ 796 F_Daempfer_01_FR_Mmi 0;
BA_ "NWM-WakeupAllowed" SG_ 796 F_Daempfer_01_FR_Mmi 1;
BA_ "GenSigStartValue" SG_ 796 F_Daempfer_01_FR_Mmi 1;
BA_ "GenSigSendType" SG_ 796 F_Daempfer_01_FR_Mmi 0;
BA_ "NWM-WakeupAllowed" SG_ 796 F_Fahrwerk_02_Mmi 1;
BA_ "GenSigStartValue" SG_ 796 F_Fahrwerk_02_Mmi 1;
BA_ "GenSigSendType" SG_ 796 F_Fahrwerk_02_Mmi 0;
BA_ "GenSigSwitchedByIgnition" SG_ 796 F_Motor_03_Mmi 0;
BA_ "GenSigStartValue" SG_ 796 F_Motor_03_Mmi 1;
BA_ "GenSigSendType" SG_ 796 F_Motor_03_Mmi 0;
BA_ "GenSigSwitchedByIgnition" SG_ 796 F_Motor_07_Mmi 0;
BA_ "GenSigStartValue" SG_ 796 F_Motor_07_Mmi 1;
BA_ "GenSigSendType" SG_ 796 F_Motor_07_Mmi 0;
BA_ "GenSigSwitchedByIgnition" SG_ 796 F_Motor_15_PAG_Mmi 0;
BA_ "GenSigStartValue" SG_ 796 F_Motor_15_PAG_Mmi 1;
BA_ "GenSigSendType" SG_ 796 F_Motor_15_PAG_Mmi 0;
BA_ "GenSigSwitchedByIgnition" SG_ 796 F_Motor_02_Mmi 0;
BA_ "GenSigStartValue" SG_ 796 F_Motor_02_Mmi 1;
BA_ "GenSigSendType" SG_ 796 F_Motor_02_Mmi 0;
BA_ "GenSigSwitchedByIgnition" SG_ 796 F_Motor_Hybrid_01_Mmi 0;
BA_ "GenSigStartValue" SG_ 796 F_Motor_Hybrid_01_Mmi 1;
BA_ "GenSigSendType" SG_ 796 F_Motor_Hybrid_01_Mmi 0;
BA_ "GenSigSwitchedByIgnition" SG_ 796 F_Getriebe_07_PAG 0;
BA_ "GenSigStartValue" SG_ 796 F_Getriebe_07_PAG 1;
BA_ "GenSigSendType" SG_ 796 F_Getriebe_07_PAG 0;
BA_ "GenSigSwitchedByIgnition" SG_ 908 HAL_Warnungen 0;
BA_ "GenSigSendType" SG_ 908 HAL_Warnungen 0;
BA_ "Fehlerwert" SG_ 908 ESP_Querbeschleunigung_Roh 511;
BA_ "GenSigSwitchedByIgnition" SG_ 908 ESP_Querbeschleunigung_Roh 0;
BA_ "GenSigStartValue" SG_ 908 ESP_Querbeschleunigung_Roh 255;
BA_ "GenSigSendType" SG_ 908 ESP_Querbeschleunigung_Roh 0;
BA_ "Fehlerwert" SG_ 908 ESP_Querbeschleunigung_Offset 63;
BA_ "GenSigSwitchedByIgnition" SG_ 908 ESP_Querbeschleunigung_Offset 0;
BA_ "GenSigStartValue" SG_ 908 ESP_Querbeschleunigung_Offset 62;
BA_ "GenSigSendType" SG_ 908 ESP_Querbeschleunigung_Offset 0;
BA_ "GenSigSwitchedByIgnition" SG_ 908 ESP_Eingriff 0;
BA_ "GenSigSendType" SG_ 908 ESP_Eingriff 0;
BA_ "GenSigSwitchedByIgnition" SG_ 908 ESP_Off_Lampe 0;
BA_ "GenSigSendType" SG_ 908 ESP_Off_Lampe 0;
BA_ "GenSigSwitchedByIgnition" SG_ 908 ESP_Rollenmodus 0;
BA_ "NWM-WakeupAllowed" SG_ 908 ESP_Rollenmodus 1;
BA_ "GenSigSendType" SG_ 908 ESP_Rollenmodus 0;
BA_ "GenSigSwitchedByIgnition" SG_ 908 ESP_Stillstandsflag 0;
BA_ "GenSigSendType" SG_ 908 ESP_Stillstandsflag 0;
BA_ "GenSigSwitchedByIgnition" SG_ 908 ESP_Autohold_aktiv 0;
BA_ "GenSigSendType" SG_ 908 ESP_Autohold_aktiv 0;
BA_ "GenSigSwitchedByIgnition" SG_ 908 ESP_HDC_Standby 0;
BA_ "GenSigSendType" SG_ 908 ESP_HDC_Standby 0;
BA_ "GenSigSwitchedByIgnition" SG_ 908 F_ESP_05_Mmi 0;
BA_ "NWM-WakeupAllowed" SG_ 908 F_ESP_05_Mmi 1;
BA_ "GenSigStartValue" SG_ 908 F_ESP_05_Mmi 1;
BA_ "GenSigSendType" SG_ 908 F_ESP_05_Mmi 0;
BA_ "GenSigSwitchedByIgnition" SG_ 908 F_ESP_01_Mmi 0;
BA_ "NWM-WakeupAllowed" SG_ 908 F_ESP_01_Mmi 1;
BA_ "GenSigStartValue" SG_ 908 F_ESP_01_Mmi 1;
BA_ "GenSigSendType" SG_ 908 F_ESP_01_Mmi 0;
BA_ "GenSigSwitchedByIgnition" SG_ 908 F_ESP_04_Mmi 0;
BA_ "NWM-WakeupAllowed" SG_ 908 F_ESP_04_Mmi 1;
BA_ "GenSigStartValue" SG_ 908 F_ESP_04_Mmi 1;
BA_ "GenSigSendType" SG_ 908 F_ESP_04_Mmi 0;
BA_ "GenSigSwitchedByIgnition" SG_ 908 F_ESP_02_Mmi 0;
BA_ "NWM-WakeupAllowed" SG_ 908 F_ESP_02_Mmi 1;
BA_ "GenSigStartValue" SG_ 908 F_ESP_02_Mmi 1;
BA_ "GenSigSendType" SG_ 908 F_ESP_02_Mmi 0;
BA_ "GenSigSwitchedByIgnition" SG_ 908 F_ESP_11_Mmi 0;
BA_ "NWM-WakeupAllowed" SG_ 908 F_ESP_11_Mmi 1;
BA_ "GenSigStartValue" SG_ 908 F_ESP_11_Mmi 1;
BA_ "GenSigSendType" SG_ 908 F_ESP_11_Mmi 0;
BA_ "GenSigSwitchedByIgnition" SG_ 908 F_ESP_13_Mmi 0;
BA_ "NWM-WakeupAllowed" SG_ 908 F_ESP_13_Mmi 1;
BA_ "GenSigStartValue" SG_ 908 F_ESP_13_Mmi 1;
BA_ "GenSigSendType" SG_ 908 F_ESP_13_Mmi 0;
BA_ "GenSigSwitchedByIgnition" SG_ 908 HAL_01_alt 0;
BA_ "GenSigFuncType" SG_ 908 HAL_01_alt 5;
BA_ "GenSigStartValue" SG_ 908 HAL_01_alt 1;
BA_ "GenSigSendType" SG_ 908 HAL_01_alt 0;
BA_ "GenSigSendType" SG_ 1515 FS_MMB_storage 3;
BA_ "GenSigSendType" SG_ 1515 FS_MMB_storage_beep 3;
BA_ "GenSigSendType" SG_ 1515 FS_MMB_store 3;
BA_ "GenSigSendType" SG_ 1515 FS_MMB_tipp 3;
BA_ "GenSigSendType" SG_ 1515 FS_MMB_tast 3;
BA_ "GenSigSendType" SG_ 1515 BFS_MMB_storage 3;
BA_ "GenSigSendType" SG_ 1515 BFS_MMB_storage_beep 3;
BA_ "GenSigSendType" SG_ 1515 BFS_MMB_store 3;
BA_ "GenSigSendType" SG_ 1515 BFS_MMB_tipp 3;
BA_ "GenSigSendType" SG_ 1515 BFS_MMB_tast 3;
BA_ "GenSigSendType" SG_ 1515 BFS_MMB_store_LED_on 3;
BA_ "Fehlerwert" SG_ 1515 LWI_Lenkradwinkel 8191;
BA_ "GenSigStartValue" SG_ 1515 LWI_Lenkradwinkel 8190;
BA_ "GenSigSendType" SG_ 1515 LWI_Lenkradwinkel 0;
BA_ "GenSigSendType" SG_ 1515 LWI_VZ_Lenkradwinkel 0;
BA_ "GenSigSendType" SG_ 1515 LWI_Sensorstatus 0;
BA_ "GenSigStartValue" SG_ 1515 LWI_QBit_Lenkradwinkel 1;
BA_ "GenSigSendType" SG_ 1515 LWI_QBit_Lenkradwinkel 0;
BA_ "GenSigSwitchedByIgnition" SG_ 1515 F_LWI_01_Mmi 0;
BA_ "NWM-WakeupAllowed" SG_ 1515 F_LWI_01_Mmi 1;
BA_ "GenSigStartValue" SG_ 1515 F_LWI_01_Mmi 1;
BA_ "GenSigSendType" SG_ 1515 F_LWI_01_Mmi 0;
BA_ "NWM-WakeupAllowed" SG_ 1515 F_Mem_BFS_01_Mmi 1;
BA_ "GenSigStartValue" SG_ 1515 F_Mem_BFS_01_Mmi 1;
BA_ "GenSigSendType" SG_ 1515 F_Mem_BFS_01_Mmi 0;
BA_ "NWM-WakeupAllowed" SG_ 1515 F_Mem_FS_01_Mmi 1;
BA_ "GenSigStartValue" SG_ 1515 F_Mem_FS_01_Mmi 1;
BA_ "GenSigSendType" SG_ 1515 F_Mem_FS_01_Mmi 0;
BA_REL_ "GenSigTimeoutTime" BU_SG_REL_ Klima_PAG_PF SG_ 1335 ESP_Charisma_FahrPr 2000;
BA_REL_ "GenSigTimeoutTime" BU_SG_REL_ Klima_PAG_PF SG_ 1335 ESP_Charisma_Status 2000;
BA_REL_ "GenSigTimeoutTime" BU_SG_REL_ Klima_PAG_PF SG_ 1335 ESP_Charisma_Umschaltung 2000;
BA_REL_ "GenSigTimeoutTime" BU_SG_REL_ Klima_PAG_PF SG_ 1335 ESP_11_alt 2000;
BA_REL_ "GenSigTimeoutTime" BU_SG_REL_ Klima_PAG_PF SG_ 1335 HAL_Charisma_FahrPr 2000;
BA_REL_ "GenSigTimeoutTime" BU_SG_REL_ Klima_PAG_PF SG_ 1335 HAL_Charisma_Status 2000;
BA_REL_ "GenSigTimeoutTime" BU_SG_REL_ Klima_PAG_PF SG_ 1335 HAL_01_alt 2000;
BA_REL_ "GenSigTimeoutTime" BU_SG_REL_ Klima_PAG_PF SG_ 1335 Lift_Charisma_FahrPr 2000;
BA_REL_ "GenSigTimeoutTime" BU_SG_REL_ Klima_PAG_PF SG_ 1335 Lift_Charisma_Status 2000;
BA_REL_ "GenSigTimeoutTime" BU_SG_REL_ Klima_PAG_PF SG_ 1335 Lift_Charisma_Umschaltung 2000;
BA_REL_ "GenSigTimeoutTime" BU_SG_REL_ Klima_PAG_PF SG_ 1335 Lift_01_alt 2000;
BA_REL_ "GenSigTimeoutTime" BU_SG_REL_ ADR_PAG_X2 SG_ 1714 DGN_Verlernzaehler 5000;
BA_REL_ "GenSigTimeoutTime" BU_SG_REL_ Klima_PAG_PF SG_ 1714 DGN_Verlernzaehler 5000;
BA_REL_ "GenSigTimeoutTime" BU_SG_REL_ Klimakomp_Dash_PAG_PF SG_ 1714 DGN_Verlernzaehler 5000;
BA_REL_ "GenSigTimeoutTime" BU_SG_REL_ Kombi_PAG_PF SG_ 1714 DGN_Verlernzaehler 5000;
BA_REL_ "GenSigTimeoutTime" BU_SG_REL_ Miko_PAG_X2 SG_ 1714 DGN_Verlernzaehler 5000;
BA_REL_ "GenSigTimeoutTime" BU_SG_REL_ OCU_PAG_PF SG_ 1714 DGN_Verlernzaehler 5000;
BA_REL_ "GenSigTimeoutTime" BU_SG_REL_ RDK_High_PAG_PF SG_ 1714 DGN_Verlernzaehler 5000;
BA_REL_ "GenSigTimeoutTime" BU_SG_REL_ ADR_PAG_X2 SG_ 1714 KBI_Kilometerstand 5000;
BA_REL_ "GenSigTimeoutTime" BU_SG_REL_ Klima_PAG_PF SG_ 1714 KBI_Kilometerstand 5000;
BA_REL_ "GenSigTimeoutTime" BU_SG_REL_ Klimakomp_Dash_PAG_PF SG_ 1714 KBI_Kilometerstand 5000;
BA_REL_ "GenSigTimeoutTime" BU_SG_REL_ Miko_PAG_X2 SG_ 1714 KBI_Kilometerstand 5000;
BA_REL_ "GenSigTimeoutTime" BU_SG_REL_ OCU_PAG_PF SG_ 1714 KBI_Kilometerstand 5000;
BA_REL_ "GenSigTimeoutTime" BU_SG_REL_ RDK_High_PAG_PF SG_ 1714 KBI_Kilometerstand 5000;
BA_REL_ "GenSigTimeoutTime" BU_SG_REL_ ADR_PAG_X2 SG_ 1714 UH_Jahr 5000;
BA_REL_ "GenSigTimeoutTime" BU_SG_REL_ Klima_PAG_PF SG_ 1714 UH_Jahr 5000;
BA_REL_ "GenSigTimeoutTime" BU_SG_REL_ Klimakomp_Dash_PAG_PF SG_ 1714 UH_Jahr 5000;
BA_REL_ "GenSigTimeoutTime" BU_SG_REL_ Kombi_PAG_PF SG_ 1714 UH_Jahr 5000;
BA_REL_ "GenSigTimeoutTime" BU_SG_REL_ Miko_PAG_X2 SG_ 1714 UH_Jahr 5000;
BA_REL_ "GenSigTimeoutTime" BU_SG_REL_ OCU_PAG_PF SG_ 1714 UH_Jahr 5000;
BA_REL_ "GenSigTimeoutTime" BU_SG_REL_ RDK_High_PAG_PF SG_ 1714 UH_Jahr 5000;
BA_REL_ "GenSigTimeoutTime" BU_SG_REL_ ADR_PAG_X2 SG_ 1714 UH_Monat 5000;
BA_REL_ "GenSigTimeoutTime" BU_SG_REL_ Klima_PAG_PF SG_ 1714 UH_Monat 5000;
BA_REL_ "GenSigTimeoutTime" BU_SG_REL_ Klimakomp_Dash_PAG_PF SG_ 1714 UH_Monat 5000;
BA_REL_ "GenSigTimeoutTime" BU_SG_REL_ Kombi_PAG_PF SG_ 1714 UH_Monat 5000;
BA_REL_ "GenSigTimeoutTime" BU_SG_REL_ Miko_PAG_X2 SG_ 1714 UH_Monat 5000;
BA_REL_ "GenSigTimeoutTime" BU_SG_REL_ OCU_PAG_PF SG_ 1714 UH_Monat 5000;
BA_REL_ "GenSigTimeoutTime" BU_SG_REL_ RDK_High_PAG_PF SG_ 1714 UH_Monat 5000;
BA_REL_ "GenSigTimeoutTime" BU_SG_REL_ ADR_PAG_X2 SG_ 1714 UH_Tag 5000;
BA_REL_ "GenSigTimeoutTime" BU_SG_REL_ Klima_PAG_PF SG_ 1714 UH_Tag 5000;
BA_REL_ "GenSigTimeoutTime" BU_SG_REL_ Klimakomp_Dash_PAG_PF SG_ 1714 UH_Tag 5000;
BA_REL_ "GenSigTimeoutTime" BU_SG_REL_ Kombi_PAG_PF SG_ 1714 UH_Tag 5000;
BA_REL_ "GenSigTimeoutTime" BU_SG_REL_ Miko_PAG_X2 SG_ 1714 UH_Tag 5000;
BA_REL_ "GenSigTimeoutTime" BU_SG_REL_ OCU_PAG_PF SG_ 1714 UH_Tag 5000;
BA_REL_ "GenSigTimeoutTime" BU_SG_REL_ RDK_High_PAG_PF SG_ 1714 UH_Tag 5000;
BA_REL_ "GenSigTimeoutTime" BU_SG_REL_ ADR_PAG_X2 SG_ 1714 UH_Stunde 5000;
BA_REL_ "GenSigTimeoutTime" BU_SG_REL_ Klima_PAG_PF SG_ 1714 UH_Stunde 5000;
BA_REL_ "GenSigTimeoutTime" BU_SG_REL_ Klimakomp_Dash_PAG_PF SG_ 1714 UH_Stunde 5000;
BA_REL_ "GenSigTimeoutTime" BU_SG_REL_ Kombi_PAG_PF SG_ 1714 UH_Stunde 5000;
BA_REL_ "GenSigTimeoutTime" BU_SG_REL_ Miko_PAG_X2 SG_ 1714 UH_Stunde 5000;
BA_REL_ "GenSigTimeoutTime" BU_SG_REL_ OCU_PAG_PF SG_ 1714 UH_Stunde 5000;
BA_REL_ "GenSigTimeoutTime" BU_SG_REL_ RDK_High_PAG_PF SG_ 1714 UH_Stunde 5000;
BA_REL_ "GenSigTimeoutTime" BU_SG_REL_ ADR_PAG_X2 SG_ 1714 UH_Minute 5000;
BA_REL_ "GenSigTimeoutTime" BU_SG_REL_ Klima_PAG_PF SG_ 1714 UH_Minute 5000;
BA_REL_ "GenSigTimeoutTime" BU_SG_REL_ Klimakomp_Dash_PAG_PF SG_ 1714 UH_Minute 5000;
BA_REL_ "GenSigTimeoutTime" BU_SG_REL_ Kombi_PAG_PF SG_ 1714 UH_Minute 5000;
BA_REL_ "GenSigTimeoutTime" BU_SG_REL_ Miko_PAG_X2 SG_ 1714 UH_Minute 5000;
BA_REL_ "GenSigTimeoutTime" BU_SG_REL_ OCU_PAG_PF SG_ 1714 UH_Minute 5000;
BA_REL_ "GenSigTimeoutTime" BU_SG_REL_ RDK_High_PAG_PF SG_ 1714 UH_Minute 5000;
BA_REL_ "GenSigTimeoutTime" BU_SG_REL_ ADR_PAG_X2 SG_ 1714 UH_Sekunde 5000;
BA_REL_ "GenSigTimeoutTime" BU_SG_REL_ Klima_PAG_PF SG_ 1714 UH_Sekunde 5000;
BA_REL_ "GenSigTimeoutTime" BU_SG_REL_ Klimakomp_Dash_PAG_PF SG_ 1714 UH_Sekunde 5000;
BA_REL_ "GenSigTimeoutTime" BU_SG_REL_ Kombi_PAG_PF SG_ 1714 UH_Sekunde 5000;
BA_REL_ "GenSigTimeoutTime" BU_SG_REL_ Miko_PAG_X2 SG_ 1714 UH_Sekunde 5000;
BA_REL_ "GenSigTimeoutTime" BU_SG_REL_ OCU_PAG_PF SG_ 1714 UH_Sekunde 5000;
BA_REL_ "GenSigTimeoutTime" BU_SG_REL_ RDK_High_PAG_PF SG_ 1714 UH_Sekunde 5000;
BA_REL_ "GenSigTimeoutTime" BU_SG_REL_ ADR_PAG_X2 SG_ 1714 Kombi_02_alt 5000;
BA_REL_ "GenSigTimeoutTime" BU_SG_REL_ Klima_PAG_PF SG_ 1714 Kombi_02_alt 5000;
BA_REL_ "GenSigTimeoutTime" BU_SG_REL_ Klimakomp_Dash_PAG_PF SG_ 1714 Kombi_02_alt 5000;
BA_REL_ "GenSigTimeoutTime" BU_SG_REL_ Miko_PAG_X2 SG_ 1714 Kombi_02_alt 5000;
BA_REL_ "GenSigTimeoutTime" BU_SG_REL_ OCU_PAG_PF SG_ 1714 Kombi_02_alt 5000;
BA_REL_ "GenSigTimeoutTime" BU_SG_REL_ RDK_High_PAG_PF SG_ 1714 Kombi_02_alt 5000;
BA_REL_ "GenSigTimeoutTime" BU_SG_REL_ ADR_PAG_X2 SG_ 1714 Uhrzeit_01_alt 5000;
BA_REL_ "GenSigTimeoutTime" BU_SG_REL_ Klima_PAG_PF SG_ 1714 Uhrzeit_01_alt 5000;
BA_REL_ "GenSigTimeoutTime" BU_SG_REL_ Klimakomp_Dash_PAG_PF SG_ 1714 Uhrzeit_01_alt 5000;
BA_REL_ "GenSigTimeoutTime" BU_SG_REL_ Miko_PAG_X2 SG_ 1714 Uhrzeit_01_alt 5000;
BA_REL_ "GenSigTimeoutTime" BU_SG_REL_ OCU_PAG_PF SG_ 1714 Uhrzeit_01_alt 5000;
BA_REL_ "GenSigTimeoutTime" BU_SG_REL_ RDK_High_PAG_PF SG_ 1714 Uhrzeit_01_alt 5000;
BA_REL_ "GenSigTimeoutTime" BU_SG_REL_ Kombi_PAG_PF SG_ 1603 KBI_Einheit_Datum 5000;
BA_REL_ "GenSigTimeoutTime" BU_SG_REL_ Kombi_PAG_PF SG_ 1603 KBI_Einheit_Druck 5000;
BA_REL_ "GenSigTimeoutTime" BU_SG_REL_ Kombi_PAG_PF SG_ 1603 KBI_Einheit_Streckenanz 5000;
BA_REL_ "GenSigTimeoutTime" BU_SG_REL_ OCU_PAG_PF SG_ 1603 KBI_Einheit_Streckenanz 5000;
BA_REL_ "GenSigTimeoutTime" BU_SG_REL_ Kombi_PAG_PF SG_ 1603 KBI_MFA_v_Einheit_02 5000;
BA_REL_ "GenSigTimeoutTime" BU_SG_REL_ OCU_PAG_PF SG_ 1603 KBI_MFA_v_Einheit_02 5000;
BA_REL_ "GenSigTimeoutTime" BU_SG_REL_ Klima_PAG_PF SG_ 1603 KBI_Einheit_Temp 5000;
BA_REL_ "GenSigTimeoutTime" BU_SG_REL_ Kombi_PAG_PF SG_ 1603 KBI_Einheit_Temp 5000;
BA_REL_ "GenSigTimeoutTime" BU_SG_REL_ Miko_PAG_X2 SG_ 1603 KBI_Einheit_Temp 5000;
BA_REL_ "GenSigTimeoutTime" BU_SG_REL_ OCU_PAG_PF SG_ 1603 KBI_Einheit_Temp 5000;
BA_REL_ "GenSigTimeoutTime" BU_SG_REL_ Kombi_PAG_PF SG_ 1603 KBI_Einheit_Uhrzeit 5000;
BA_REL_ "GenSigTimeoutTime" BU_SG_REL_ Kombi_PAG_PF SG_ 1603 KBI_Einheit_Verbrauch 5000;
BA_REL_ "GenSigTimeoutTime" BU_SG_REL_ OCU_PAG_PF SG_ 1603 KBI_Einheit_Verbrauch 5000;
BA_REL_ "GenSigTimeoutTime" BU_SG_REL_ Kombi_PAG_PF SG_ 1603 KBI_Einheit_Volumen 5000;
BA_REL_ "GenSigTimeoutTime" BU_SG_REL_ Kombi_PAG_PF SG_ 1603 KBI_Einheit_Sprache 5000;
BA_REL_ "GenSigTimeoutTime" BU_SG_REL_ Miko_PAG_X2 SG_ 1603 KBI_Einheit_Sprache 5000;
BA_REL_ "GenSigTimeoutTime" BU_SG_REL_ Kombi_PAG_PF SG_ 781 EPB_Fehlerlampe_Gelb 500;
BA_REL_ "GenSigTimeoutTime" BU_SG_REL_ Kombi_PAG_PF SG_ 781 EPB_Texte 500;
BA_REL_ "GenSigTimeoutTime" BU_SG_REL_ Kombi_PAG_PF SG_ 781 EPB_Akustik 500;
BA_REL_ "GenSigTimeoutTime" BU_SG_REL_ ADR_PAG_X2 SG_ 256 ASR_Tastung_passiv 500;
BA_REL_ "GenSigTimeoutTime" BU_SG_REL_ Klima_PAG_PF SG_ 256 ASR_Tastung_passiv 500;
BA_REL_ "GenSigTimeoutTime" BU_SG_REL_ Kombi_PAG_PF SG_ 256 ASR_Tastung_passiv 500;
BA_REL_ "GenSigTimeoutTime" BU_SG_REL_ ADR_PAG_X2 SG_ 257 ESP_Laengsbeschl 500;
BA_REL_ "GenSigTimeoutTime" BU_SG_REL_ Kombi_PAG_PF SG_ 257 ESP_Laengsbeschl 500;
BA_REL_ "GenSigTimeoutTime" BU_SG_REL_ Kombi_PAG_PF SG_ 259 ESP_VL_Radgeschw 500;
BA_REL_ "GenSigTimeoutTime" BU_SG_REL_ Kombi_PAG_PF SG_ 259 ESP_VR_Radgeschw 500;
BA_REL_ "GenSigTimeoutTime" BU_SG_REL_ Kombi_PAG_PF SG_ 259 ESP_HL_Radgeschw 500;
BA_REL_ "GenSigTimeoutTime" BU_SG_REL_ Kombi_PAG_PF SG_ 259 ESP_HR_Radgeschw 500;
BA_REL_ "GenSigTimeoutTime" BU_SG_REL_ Kombi_PAG_PF SG_ 776 ESP_Meldungen 500;
BA_REL_ "GenSigTimeoutTime" BU_SG_REL_ Kombi_PAG_PF SG_ 776 ESP_Lampe 500;
BA_REL_ "GenSigTimeoutTime" BU_SG_REL_ Kombi_PAG_PF SG_ 776 ABS_Lampe 500;
BA_REL_ "GenSigTimeoutTime" BU_SG_REL_ Kombi_PAG_PF SG_ 776 BK_Lampe 500;
BA_REL_ "GenSigTimeoutTime" BU_SG_REL_ Kombi_PAG_PF SG_ 776 ESP_Diagnose 500;
BA_REL_ "GenSigTimeoutTime" BU_SG_REL_ Kombi_PAG_PF SG_ 776 ESP_Textanzeigen_02 500;
BA_REL_ "GenSigTimeoutTime" BU_SG_REL_ Klima_PAG_PF SG_ 776 ESP_Off_Lampe 500;
BA_REL_ "GenSigTimeoutTime" BU_SG_REL_ Kombi_PAG_PF SG_ 776 ESP_Wegimp_VA 500;
BA_REL_ "GenSigTimeoutTime" BU_SG_REL_ Kombi_PAG_PF SG_ 776 ESP_Wegimp_Ueberlauf 500;
BA_REL_ "GenSigTimeoutTime" BU_SG_REL_ Kombi_PAG_PF SG_ 776 ESP_BKV_Warnung 500;
BA_REL_ "GenSigTimeoutTime" BU_SG_REL_ Kombi_PAG_PF SG_ 776 ESP_Zaehnezahl 500;
BA_REL_ "GenSigTimeoutTime" BU_SG_REL_ ADR_PAG_X2 SG_ 278 ESP_QBit_Wegimpuls_VL 500;
BA_REL_ "GenSigTimeoutTime" BU_SG_REL_ ADR_PAG_X2 SG_ 278 ESP_QBit_Wegimpuls_VR 500;
BA_REL_ "GenSigTimeoutTime" BU_SG_REL_ ADR_PAG_X2 SG_ 278 ESP_QBit_Wegimpuls_HL 500;
BA_REL_ "GenSigTimeoutTime" BU_SG_REL_ ADR_PAG_X2 SG_ 278 ESP_QBit_Wegimpuls_HR 500;
BA_REL_ "GenSigTimeoutTime" BU_SG_REL_ ADR_PAG_X2 SG_ 278 ESP_Wegimpuls_VL 500;
BA_REL_ "GenSigTimeoutTime" BU_SG_REL_ ADR_PAG_X2 SG_ 278 ESP_Wegimpuls_VR 500;
BA_REL_ "GenSigTimeoutTime" BU_SG_REL_ ADR_PAG_X2 SG_ 278 ESP_Wegimpuls_HL 500;
BA_REL_ "GenSigTimeoutTime" BU_SG_REL_ ADR_PAG_X2 SG_ 278 ESP_Wegimpuls_HR 500;
BA_REL_ "GenSigTimeoutTime" BU_SG_REL_ ADR_PAG_X2 SG_ 278 ESP_VL_Fahrtrichtung 500;
BA_REL_ "GenSigTimeoutTime" BU_SG_REL_ ADR_PAG_X2 SG_ 278 ESP_VR_Fahrtrichtung 500;
BA_REL_ "GenSigTimeoutTime" BU_SG_REL_ ADR_PAG_X2 SG_ 278 ESP_HL_Fahrtrichtung 500;
BA_REL_ "GenSigTimeoutTime" BU_SG_REL_ ADR_PAG_X2 SG_ 278 ESP_HR_Fahrtrichtung 500;
BA_REL_ "GenSigTimeoutTime" BU_SG_REL_ ADR_PAG_X2 SG_ 963 Motor_03_alt 1000;
BA_REL_ "GenSigTimeoutTime" BU_SG_REL_ Klima_PAG_PF SG_ 963 Motor_03_alt 1000;
BA_REL_ "GenSigTimeoutTime" BU_SG_REL_ Kombi_PAG_PF SG_ 963 Motor_03_alt 1000;
BA_REL_ "GenSigTimeoutTime" BU_SG_REL_ RDK_High_PAG_PF SG_ 963 Motor_03_alt 1000;
BA_REL_ "GenSigTimeoutTime" BU_SG_REL_ ADR_PAG_X2 SG_ 963 Getriebe_03_alt 1000;
BA_REL_ "GenSigTimeoutTime" BU_SG_REL_ Klima_PAG_PF SG_ 963 Motor_05_alt 1000;
BA_REL_ "GenSigTimeoutTime" BU_SG_REL_ ADR_PAG_X2 SG_ 963 EPB_01_alt 1000;
BA_REL_ "GenSigTimeoutTime" BU_SG_REL_ ADR_PAG_X2 SG_ 963 ESP_01_alt 1000;
BA_REL_ "GenSigTimeoutTime" BU_SG_REL_ Klima_PAG_PF SG_ 963 ESP_01_alt 1000;
BA_REL_ "GenSigTimeoutTime" BU_SG_REL_ Kombi_PAG_PF SG_ 963 ESP_01_alt 1000;
BA_REL_ "GenSigTimeoutTime" BU_SG_REL_ ADR_PAG_X2 SG_ 963 ESP_v_Signal 1000;
BA_REL_ "GenSigTimeoutTime" BU_SG_REL_ Klima_PAG_PF SG_ 963 ESP_v_Signal 1000;
BA_REL_ "GenSigTimeoutTime" BU_SG_REL_ Kombi_PAG_PF SG_ 963 ESP_v_Signal 1000;
BA_REL_ "GenSigTimeoutTime" BU_SG_REL_ ADR_PAG_X2 SG_ 963 EPB_Status 1000;
BA_REL_ "GenSigTimeoutTime" BU_SG_REL_ ADR_PAG_X2 SG_ 963 GE_Waehlhebel 1000;
BA_REL_ "GenSigTimeoutTime" BU_SG_REL_ Klima_PAG_PF SG_ 963 MO_Motor_laeuft 1000;
BA_REL_ "GenSigTimeoutTime" BU_SG_REL_ Kombi_PAG_PF SG_ 963 MO_Motor_laeuft 1000;
BA_REL_ "GenSigTimeoutTime" BU_SG_REL_ ADR_PAG_X2 SG_ 963 MO_Drehzahl_01 1000;
BA_REL_ "GenSigTimeoutTime" BU_SG_REL_ RDK_High_PAG_PF SG_ 963 MO_Drehzahl_01 1000;
BA_REL_ "GenSigTimeoutTime" BU_SG_REL_ Klima_PAG_PF SG_ 963 MO_Klima_Eingr 1000;
BA_REL_ "GenSigTimeoutTime" BU_SG_REL_ RDK_High_PAG_PF SG_ 1643 Kombi_02_alt 5000;
BA_REL_ "GenSigTimeoutTime" BU_SG_REL_ Klima_PAG_PF SG_ 1643 Motor_05_alt 5000;
BA_REL_ "GenSigTimeoutTime" BU_SG_REL_ ADR_PAG_X2 SG_ 1643 Motor_06_alt 5000;
BA_REL_ "GenSigTimeoutTime" BU_SG_REL_ Klima_PAG_PF SG_ 1643 Motor_06_alt 5000;
BA_REL_ "GenSigTimeoutTime" BU_SG_REL_ RDK_High_PAG_PF SG_ 1643 KBI_Aussen_Temp_gef 5000;
BA_REL_ "GenSigTimeoutTime" BU_SG_REL_ RDK_High_PAG_PF SG_ 1643 KBI_QBit_Aussen_Temp_gef 5000;
BA_REL_ "GenSigTimeoutTime" BU_SG_REL_ ADR_PAG_X2 SG_ 1643 MO_HYB_Fahrbereitschaft 5000;
BA_REL_ "GenSigTimeoutTime" BU_SG_REL_ Klima_PAG_PF SG_ 1643 MO_HYB_Fahrbereitschaft 5000;
BA_REL_ "GenSigTimeoutTime" BU_SG_REL_ Klima_PAG_PF SG_ 1643 MO_EKlKomLeiRed 5000;
BA_REL_ "GenSigTimeoutTime" BU_SG_REL_ Klima_PAG_PF SG_ 924 Motor_05_alt 1000;
BA_REL_ "GenSigTimeoutTime" BU_SG_REL_ Klima_PAG_PF SG_ 924 MO_Freig_Reku 1000;
BA_REL_ "GenSigTimeoutTime" BU_SG_REL_ Klimakomp_Dash_PAG_PF SG_ 1318 Motor_06_alt 2000;
BA_REL_ "GenSigTimeoutTime" BU_SG_REL_ Klimakomp_Dash_PAG_PF SG_ 1318 MO_HYB_Fahrbereitschaft 2000;
BA_REL_ "GenSigTimeoutTime" BU_SG_REL_ ADR_PAG_X2 SG_ 258 GE_Zielgang 500;
BA_REL_ "GenSigTimeoutTime" BU_SG_REL_ Klima_PAG_PF SG_ 1612 GW_Karosserie_Typ 5000;
BA_REL_ "GenSigTimeoutTime" BU_SG_REL_ OCU_PAG_PF SG_ 1612 GW_Karosserie_Typ 5000;
BA_REL_ "GenSigTimeoutTime" BU_SG_REL_ Klima_PAG_PF SG_ 1612 GW_Lenker 5000;
BA_REL_ "GenSigTimeoutTime" BU_SG_REL_ OCU_PAG_PF SG_ 1612 GW_Lenker 5000;
BA_REL_ "GenSigTimeoutTime" BU_SG_REL_ Klima_PAG_PF SG_ 1612 GW_Baureihe 5000;
BA_REL_ "GenSigTimeoutTime" BU_SG_REL_ OCU_PAG_PF SG_ 1612 GW_Baureihe 5000;
BA_REL_ "GenSigTimeoutTime" BU_SG_REL_ OCU_PAG_PF SG_ 1612 GW_Fzg_Antrieb 5000;
BA_REL_ "GenSigTimeoutTime" BU_SG_REL_ ADR_PAG_X2 SG_ 909 BCM1_Rueckfahrlicht_Schalter 1000;
BA_REL_ "GenSigTimeoutTime" BU_SG_REL_ Klima_PAG_PF SG_ 909 BCM1_Rueckfahrlicht_Schalter 1000;
BA_REL_ "GenSigTimeoutTime" BU_SG_REL_ Kombi_PAG_PF SG_ 909 BCM1_Rueckfahrlicht_Schalter 1000;
BA_REL_ "GenSigTimeoutTime" BU_SG_REL_ Klima_PAG_PF SG_ 909 KY1_FuSchl_Nr_Zugang 1000;
BA_REL_ "GenSigTimeoutTime" BU_SG_REL_ Klima_PAG_PF SG_ 909 F_Kessy_01_Mmi 1000;
BA_REL_ "GenSigTimeoutTime" BU_SG_REL_ ADR_PAG_X2 SG_ 909 F_BCM1_01_Mmi 1000;
BA_REL_ "GenSigTimeoutTime" BU_SG_REL_ Klima_PAG_PF SG_ 909 F_BCM1_01_Mmi 1000;
BA_REL_ "GenSigTimeoutTime" BU_SG_REL_ Kombi_PAG_PF SG_ 909 F_BCM1_01_Mmi 1000;
BA_REL_ "GenSigTimeoutTime" BU_SG_REL_ Kombi_PAG_PF SG_ 1514 DR_Gelbe_Warnlampe 5000;
BA_REL_ "GenSigTimeoutTime" BU_SG_REL_ Kombi_PAG_PF SG_ 1514 DR_Rote_Warnlampe 5000;
BA_REL_ "GenSigTimeoutTime" BU_SG_REL_ Kombi_PAG_PF SG_ 1514 DR_DynAGL_Warnlampe 5000;
BA_REL_ "GenSigTimeoutTime" BU_SG_REL_ Kombi_PAG_PF SG_ 1514 F_Daempfer_01_FR_Mmi 5000;
BA_REL_ "GenSigTimeoutTime" BU_SG_REL_ Klima_PAG_PF SG_ 796 MO_Drehzahl_01 500;
BA_REL_ "GenSigTimeoutTime" BU_SG_REL_ Klima_PAG_PF SG_ 796 MO_Kuehlmittel_Temp 500;
BA_REL_ "GenSigTimeoutTime" BU_SG_REL_ ADR_PAG_X2 SG_ 796 DR_Daempferreg_Texte 500;
BA_REL_ "GenSigTimeoutTime" BU_SG_REL_ Kombi_PAG_PF SG_ 796 DR_Daempferreg_Texte 500;
BA_REL_ "GenSigTimeoutTime" BU_SG_REL_ ADR_PAG_X2 SG_ 796 MO_HYB_VM_aktiv 500;
BA_REL_ "GenSigTimeoutTime" BU_SG_REL_ Klima_PAG_PF SG_ 796 DR_Systemstatus 500;
BA_REL_ "GenSigTimeoutTime" BU_SG_REL_ Klima_PAG_PF SG_ 796 GE_Segel_Status 500;
BA_REL_ "GenSigTimeoutTime" BU_SG_REL_ Kombi_PAG_PF SG_ 796 GE_Segel_Status 500;
BA_REL_ "GenSigTimeoutTime" BU_SG_REL_ Kombi_PAG_PF SG_ 796 GE_Status_PaddleNeutral 500;
BA_REL_ "GenSigTimeoutTime" BU_SG_REL_ ADR_PAG_X2 SG_ 796 F_Daempfer_01_FR_Mmi 500;
BA_REL_ "GenSigTimeoutTime" BU_SG_REL_ Klima_PAG_PF SG_ 796 F_Daempfer_01_FR_Mmi 500;
BA_REL_ "GenSigTimeoutTime" BU_SG_REL_ Kombi_PAG_PF SG_ 796 F_Daempfer_01_FR_Mmi 500;
BA_REL_ "GenSigTimeoutTime" BU_SG_REL_ Klima_PAG_PF SG_ 796 F_Motor_03_Mmi 500;
BA_REL_ "GenSigTimeoutTime" BU_SG_REL_ Klima_PAG_PF SG_ 796 F_Motor_07_Mmi 500;
BA_REL_ "GenSigTimeoutTime" BU_SG_REL_ ADR_PAG_X2 SG_ 796 F_Motor_Hybrid_01_Mmi 500;
BA_REL_ "GenSigTimeoutTime" BU_SG_REL_ Klima_PAG_PF SG_ 796 F_Getriebe_07_PAG 500;
BA_REL_ "GenSigTimeoutTime" BU_SG_REL_ Kombi_PAG_PF SG_ 796 F_Getriebe_07_PAG 500;
BA_REL_ "GenSigTimeoutTime" BU_SG_REL_ Kombi_PAG_PF SG_ 908 HAL_Warnungen 1000;
BA_REL_ "GenSigTimeoutTime" BU_SG_REL_ ADR_PAG_X2 SG_ 908 ESP_Querbeschleunigung_Roh 1000;
BA_REL_ "GenSigTimeoutTime" BU_SG_REL_ Kombi_PAG_PF SG_ 908 ESP_Querbeschleunigung_Roh 1000;
BA_REL_ "GenSigTimeoutTime" BU_SG_REL_ ADR_PAG_X2 SG_ 908 ESP_Querbeschleunigung_Offset 1000;
BA_REL_ "GenSigTimeoutTime" BU_SG_REL_ Kombi_PAG_PF SG_ 908 ESP_Querbeschleunigung_Offset 1000;
BA_REL_ "GenSigTimeoutTime" BU_SG_REL_ ADR_PAG_X2 SG_ 908 ESP_Off_Lampe 1000;
BA_REL_ "GenSigTimeoutTime" BU_SG_REL_ Kombi_PAG_PF SG_ 908 ESP_Off_Lampe 1000;
BA_REL_ "GenSigTimeoutTime" BU_SG_REL_ Kombi_PAG_PF SG_ 908 ESP_Rollenmodus 1000;
BA_REL_ "GenSigTimeoutTime" BU_SG_REL_ ADR_PAG_X2 SG_ 908 ESP_Stillstandsflag 1000;
BA_REL_ "GenSigTimeoutTime" BU_SG_REL_ Kombi_PAG_PF SG_ 908 ESP_Autohold_aktiv 1000;
BA_REL_ "GenSigTimeoutTime" BU_SG_REL_ Klima_PAG_PF SG_ 908 ESP_HDC_Standby 1000;
BA_REL_ "GenSigTimeoutTime" BU_SG_REL_ Klima_PAG_PF SG_ 908 F_ESP_05_Mmi 1000;
BA_REL_ "GenSigTimeoutTime" BU_SG_REL_ Kombi_PAG_PF SG_ 908 F_ESP_05_Mmi 1000;
BA_REL_ "GenSigTimeoutTime" BU_SG_REL_ ADR_PAG_X2 SG_ 908 F_ESP_04_Mmi 1000;
BA_REL_ "GenSigTimeoutTime" BU_SG_REL_ Kombi_PAG_PF SG_ 908 F_ESP_04_Mmi 1000;
BA_REL_ "GenSigTimeoutTime" BU_SG_REL_ ADR_PAG_X2 SG_ 908 F_ESP_02_Mmi 1000;
BA_REL_ "GenSigTimeoutTime" BU_SG_REL_ Kombi_PAG_PF SG_ 908 F_ESP_11_Mmi 1000;
BA_REL_ "GenSigTimeoutTime" BU_SG_REL_ ADR_PAG_X2 SG_ 908 F_ESP_13_Mmi 1000;
BA_REL_ "GenSigTimeoutTime" BU_SG_REL_ Kombi_PAG_PF SG_ 908 F_ESP_13_Mmi 1000;
BA_REL_ "GenSigTimeoutTime" BU_SG_REL_ Kombi_PAG_PF SG_ 908 HAL_01_alt 1000;
BA_REL_ "GenSigTimeoutTime" BU_SG_REL_ ADR_PAG_X2 SG_ 1515 LWI_Lenkradwinkel 5000;
BA_REL_ "GenSigTimeoutTime" BU_SG_REL_ Klima_PAG_PF SG_ 1515 LWI_Lenkradwinkel 5000;
BA_REL_ "GenSigTimeoutTime" BU_SG_REL_ ADR_PAG_X2 SG_ 1515 LWI_VZ_Lenkradwinkel 5000;
BA_REL_ "GenSigTimeoutTime" BU_SG_REL_ Klima_PAG_PF SG_ 1515 LWI_VZ_Lenkradwinkel 5000;
BA_REL_ "GenSigTimeoutTime" BU_SG_REL_ ADR_PAG_X2 SG_ 1515 F_LWI_01_Mmi 5000;
BA_REL_ "GenSigTimeoutTime" BU_SG_REL_ Klima_PAG_PF SG_ 1515 F_LWI_01_Mmi 5000;
VAL_ 899 CHA_Ziel_FahrPr_HAL 0 "nicht_belegt" 1 "Programm_1" 2 "Programm_2" 3 "Programm_3" 4 "Programm_4" 5 "Programm_5" 6 "Programm_6" 7 "Programm_7" ;
VAL_ 899 CHA_Ziel_FahrPr_BCM 0 "nicht_belegt" 1 "Programm_1" 2 "Programm_2" 3 "Programm_3" 4 "Programm_4" 5 "Programm_5" 6 "Programm_6" 7 "Programm_7" ;
VAL_ 899 CHA_Ziel_FahrPr_HAL_01 0 "nicht_belegt" 1 "Programm_1" 2 "Programm_2" 3 "Programm_3" 4 "Programm_4" 5 "Programm_5" 6 "Programm_6" 7 "Programm_7" ;
VAL_ 899 CHA_Ziel_FahrPr_BMS 0 "nicht_belegt" 1 "Programm_1" 2 "Programm_2" 3 "Programm_3" 4 "Programm_4" 5 "Programm_5" 6 "Programm_6" 7 "Programm_7" ;
VAL_ 899 CHA_Ziel_FahrPr_ALR 0 "nicht_belegt" 1 "Programm_1" 2 "Programm_2" 3 "Programm_3" 4 "Programm_4" 5 "Programm_5" 6 "Programm_6" 7 "Programm_7" ;
VAL_ 899 CHA_Ziel_FahrPr_ESP 0 "nicht_belegt" 1 "Programm_1" 2 "Programm_2" 3 "Programm_3" 4 "Programm_4" 5 "Programm_5" 6 "Programm_6" 7 "Programm_7" ;
VAL_ 899 CHA_Ziel_FahrPr_PDCC 0 "nicht_belegt" 1 "Programm_1" 2 "Programm_2" 3 "Programm_3" 4 "Programm_4" 5 "Programm_5" 6 "Programm_6" 7 "Programm_7" ;
VAL_ 899 CHA_Ziel_FahrPr_QUER 0 "nicht_belegt" 1 "Programm_1" 2 "Programm_2" 3 "Programm_3" 4 "Programm_4" 5 "Programm_5" 6 "Programm_6" 7 "Programm_7" ;
VAL_ 899 CHA_Ziel_FahrPr_MO_01 0 "nicht_belegt" 1 "Programm_1" 2 "Programm_2" 3 "Programm_3" 4 "Programm_4" 5 "Programm_5" 6 "Programm_6" 7 "Programm_7" ;
VAL_ 899 CHA_Ziel_FahrPr_GE_01 0 "nicht_belegt" 1 "Programm_1" 2 "Programm_2" 3 "Programm_3" 4 "Programm_4" 5 "Programm_5" 6 "Programm_6" 7 "Programm_7" ;
VAL_ 899 CHA_Ziel_FahrPr_MO_02 0 "nicht_belegt" 1 "Programm_1" 2 "Programm_2" 3 "Programm_3" 4 "Programm_4" 5 "Programm_5" 6 "Programm_6" 7 "Programm_7" ;
VAL_ 899 CHA_Ziel_FahrPr_GE_02 0 "nicht_belegt" 1 "Programm_1" 2 "Programm_2" 3 "Programm_3" 4 "Programm_4" 5 "Programm_5" 6 "Programm_6" 7 "Programm_7" ;
VAL_ 899 CHA_Ziel_FahrPr_MO_03 0 "nicht_belegt" 1 "Programm_1" 2 "Programm_2" 3 "Programm_3" 4 "Programm_4" 5 "Programm_5" 6 "Programm_6" 7 "Programm_7" ;
VAL_ 899 CHA_Ziel_FahrPr_GE_03 0 "nicht_belegt" 1 "Programm_1" 2 "Programm_2" 3 "Programm_3" 4 "Programm_4" 5 "Programm_5" 6 "Programm_6" 7 "Programm_7" ;
VAL_ 899 CHA_Ziel_FahrPr_DR_01 0 "nicht_belegt" 1 "Programm_1" 2 "Programm_2" 3 "Programm_3" 4 "Programm_4" 5 "Programm_5" 6 "Programm_6" 7 "Programm_7" ;
VAL_ 899 CHA_Ziel_FahrPr_Lift 0 "nicht_belegt" 1 "Programm_1" 2 "Programm_2" 3 "Programm_3" 4 "Programm_4" 5 "Programm_5" 6 "Programm_6" 7 "Programm_7" ;
VAL_ 1335 ALR_Charisma_FahrPr 0 "nicht_belegt" 1 "Programm_1" 2 "Programm_2" 3 "Programm_3" 4 "Programm_4" 5 "Programm_5" 6 "Programm_6" 7 "Programm_7" ;
VAL_ 1335 ALR_Charisma_Status 0 "Init" 1 "verfuegbar" 2 "nicht_verfuegbar" 3 "asynchron_durch_Fahrerwunsch" ;
VAL_ 1335 ALR_Charisma_Umschaltung 0 "Idle" 1 "Erkennung_Umschaltaufforderung" 2 "Steuerbotschaft_nicht_definiert" 3 "Umschaltung_verzoegert" ;
VAL_ 1335 Allrad_02_alt 0 "aktuell" 1 "veraltet" ;
VAL_ 1335 ESP_Charisma_FahrPr 0 "nicht_belegt" 1 "Programm_1" 2 "Programm_2" 3 "Programm_3" 4 "Programm_4" 5 "Programm_5" 6 "Programm_6" 7 "Programm_7" ;
VAL_ 1335 ESP_Charisma_Status 0 "Init" 1 "verfuegbar" 2 "nicht_verfuegbar" 3 "asynchron_durch_Fahrerwunsch" ;
VAL_ 1335 ESP_Charisma_Umschaltung 0 "Idle" 1 "Erkennung_Umschaltaufforderung" 2 "Steuerbotschaft_nicht_definiert" 3 "Umschaltung_verzoegert" ;
VAL_ 1335 ESP_11_alt 0 "aktuell" 1 "veraltet" ;
VAL_ 1335 PDCC_Charisma_FahrPr 0 "nicht_belegt" 1 "Programm_1" 2 "Programm_2" 3 "Programm_3" 4 "Programm_4" 5 "Programm_5" 6 "Programm_6" 7 "Programm_7" ;
VAL_ 1335 PDCC_Charisma_Status 0 "Init" 1 "verfuegbar" 2 "nicht_verfuegbar" 3 "asynchron_durch_Fahrerwunsch" ;
VAL_ 1335 PDCC_Charisma_Umschaltung 0 "Idle" 1 "Erkennung_Umschaltaufforderung" 2 "Steuerbotschaft_nicht_definiert" 3 "Umschaltung_verzoegert" ;
VAL_ 1335 PDCC_01_PAG_alt 0 "aktuell" 1 "veraltet" ;
VAL_ 1335 QUER_Charisma_FahrPr 0 "nicht_belegt" 1 "Programm_1" 2 "Programm_2" 3 "Programm_3" 4 "Programm_4" 5 "Programm_5" 6 "Programm_6" 7 "Programm_7" ;
VAL_ 1335 QUER_Charisma_Status 0 "Init" 1 "verfuegbar" 2 "nicht_verfuegbar" 3 "asynchron_durch_Fahrerwunsch" ;
VAL_ 1335 QUER_Charisma_Umschaltung 0 "Idle" 1 "Erkennung_Umschaltaufforderung" 2 "Steuerbotschaft_nicht_definiert" 3 "Umschaltung_verzoegert" ;
VAL_ 1335 Quersperre_02_PAG_alt 0 "aktuell" 1 "veraltet" ;
VAL_ 1335 HAL_Charisma_FahrPr 0 "nicht_belegt" 1 "Programm_1" 2 "Programm_2" 3 "Programm_3" 4 "Programm_4" 5 "Programm_5" 6 "Programm_6" 7 "Programm_7" ;
VAL_ 1335 HAL_Charisma_Status 0 "Init" 1 "verfuegbar" 2 "nicht_verfuegbar" 3 "asynchron_durch_Fahrerwunsch" ;
VAL_ 1335 HAL_01_alt 0 "aktuell" 1 "veraltet" ;
VAL_ 1335 Lift_Charisma_FahrPr 0 "nicht_belegt" 1 "Programm_1" 2 "Programm_2" 3 "Programm_3" 4 "Programm_4" 5 "Programm_5" 6 "Programm_6" 7 "Programm_7" ;
VAL_ 1335 Lift_Charisma_Status 0 "Init" 1 "verfuegbar" 2 "nicht_verfuegbar" 3 "asynchron_durch_Fahrerwunsch" ;
VAL_ 1335 Lift_Charisma_Umschaltung 0 "Idle" 1 "Erkennung_Umschaltaufforderung" 2 "Steuerbotschaft_nicht_definiert" 3 "Umschaltung_verzoegert" ;
VAL_ 1335 Lift_01_alt 0 "aktuell" 1 "veraltet" ;
VAL_ 1714 DGN_Verlernzaehler 255 "ungültiger Zählerstand oder kein gültiger Fahrzyklus" ;
VAL_ 1714 KBI_Kilometerstand 1048574 "Init" 1048575 "Fehler" ;
VAL_ 1714 UH_Monat 0 "Init" 14 "reserviert" ;
VAL_ 1714 UH_Tag 0 "Init" ;
VAL_ 1714 Kombi_02_alt 0 "aktuell" 1 "veraltet" ;
VAL_ 1714 Uhrzeit_01_alt 0 "aktuell" 1 "veraltet" ;
VAL_ 1009 GW_STH_Anf 0 "keine EIN/AUS-Anf/kein Timer akt." 1 "Standheizung EIN" 2 "Standheizung AUS" 3 "STH Timer aktiv" ;
VAL_ 1603 KBI_Einheit_Datum 0 "Tag/Monat/Jahr" 1 "Monat/Tag/Jahr" 2 "Jahr/Monat/Tag" 3 "reserviert" ;
VAL_ 1603 KBI_Einheit_Druck 0 "Druckangabe in bar" 1 "Druckangabe in psi" 2 "Druckangabe in kPa" 3 "tbd." ;
VAL_ 1603 KBI_Einheit_Streckenanz 0 "Kilometer" 1 "Meilen" ;
VAL_ 1603 KBI_MFA_v_Einheit_02 0 "kmh" 1 "mph" ;
VAL_ 1603 KBI_Einheit_Temp 0 "Grad Celsius °C" 1 "Grad Fahrenheit °F" ;
VAL_ 1603 KBI_Einheit_Uhrzeit 0 "24h" 1 " 12h AM/PM" ;
VAL_ 1603 KBI_Einheit_Verbrauch 0 "mpg UK" 1 "mpg USA" 2 "Liter/100km" 3 "km/Liter" ;
VAL_ 1603 KBI_Einheit_Volumen 0 "Liter" 1 "Gallonen UK" 2 "Gallonen USA" 3 "reserviert" ;
VAL_ 1603 KBI_Einheit_Verbrauch_elektr 0 "kWh_pro_100km" 1 "kWh_pro_100mls" 2 "km_pro_kWh" 3 "mls_pro_kWh" 4 "MPGe" ;
VAL_ 781 EPB_Fehlerlampe_Gelb 0 "Aus" 1 "Ein" ;
VAL_ 781 EPB_Fehlerlampe_BKL 0 "BKL aus" 1 "BKL an" ;
VAL_ 781 EPB_Funktionslampe 0 "Aus" 1 "Ein" ;
VAL_ 781 EPB_Texte 0 "keine_Anzeige" 1 "Neigungswinkel_zu_gross" 2 "Parkbremse_von_Hand_oeffnen" 3 "HU_Modus_oder_EPB_in_Diagnose" 4 "Bremspedal_betaetigen" 5 "tbd" 6 "tbd" 7 "Stoerung_Anfahrassistent" 8 "Abschleppschutz_blockiert" 9 "Feststellbremse_nicht_automatisch_geschlossen" 10 "Parkbremse_loesen_nicht_moeglich_Ladekabel_gesteckt" ;
VAL_ 781 EPB_Akustik 0 "Warnton aus" 1 "Warnton an" ;
VAL_ 781 EPB_Autoholdlampe 0 "Lampe aus (Autohold inaktiv)" 1 "Lampe ein (Autohold aktiv)" ;
VAL_ 781 EPB_Bremsbelag_Warn 0 "Bremsbelag_ok" 1 "Bremsbelag_unter_Minimum" ;
VAL_ 256 ASR_Moment_langsam 1022 "Init" 1023 "Fehler" ;
VAL_ 256 ASR_MSR_Moment_schnell 1022 "Init" 1023 "Fehler" ;
VAL_ 256 ESP_v_Signal 65533 "Unterspannung" 65534 "Init" 65535 "Fehler" ;
VAL_ 256 ASR_Tastung_passiv 0 "ASR_aktiviert" 1 "ASR_passiv_getastet_oder_Schwellen_geaendert" ;
VAL_ 256 ESP_Tastung_passiv 0 "ESP_aktiviert" 1 "ESP_passiv_getastet_oder_Schwellen_geaendert" ;
VAL_ 256 ESP_Systemstatus 0 "iO" 1 "Fehler" ;
VAL_ 256 ASR_Schalteingriff 0 "keine_Anforderung" 1 "ASR_Schaltkennfeld" 2 "Rueckschaltung" 3 "Schaltverbot" ;
VAL_ 256 OBD_Schlechtweg 0 "kein_Schlechtweg_erkannt" 1 "Schlechtweg_erkannt" ;
VAL_ 256 OBD_QBit_Schlechtweg 0 "gueltiger_Wert" 1 "Ersatz_Init_oder_Fehlerwert" ;
VAL_ 256 ESP_QBit_v_Signal 0 "gueltiger_Wert" 1 "Ersatz_Init_oder_Fehlerwert" ;
VAL_ 256 ABS_Bremsung 0 "keine_ABS_Regelung" 1 "ABS_Regelung_aktiv" ;
VAL_ 256 ASR_Anf 0 "keine_Anforderung" 1 "ASR_Anforderung" ;
VAL_ 256 MSR_Anf 0 "keine Anfoderung" 1 "MSR-Anforderung" ;
VAL_ 256 EBV_Eingriff 0 "kein_EBV_Eingriff" 1 "EBV_Eingriff" ;
VAL_ 256 EDS_Eingriff 0 "kein_EDS_Eingriff" 1 "EDS_Eingriff" ;
VAL_ 256 ESP_Eingriff 0 "kein_ESP_Eingriff" 1 "ESP_Eingriff_aktiv" ;
VAL_ 256 ESP_ASP 0 "inaktiv" 1 "aktiv" ;
VAL_ 256 ESP_KD_Fehler 0 "kein_KD_Fehler" 1 "KD_Fehler" ;
VAL_ 257 ESP_QBit_Gierrate 0 "gueltiger_Wert" 1 "Ersatz_Init_oder_Fehlerwert" ;
VAL_ 257 ESP_QBit_Laengsbeschl 0 "gueltiger_Wert" 1 "Ersatz_Init_oder_Fehlerwert" ;
VAL_ 257 ESP_QBit_Querb 0 "gueltiger_Wert" 1 "Ersatz_Init_oder_Fehlerwert" ;
VAL_ 257 ESP_Stillstandsflag 0 "kein_Stillstand_erkannt" 1 "Stillstand_erkannt" ;
VAL_ 257 ESP_Querbeschleunigung 255 "Fehler" ;
VAL_ 257 ESP_Laengsbeschl 1022 "Signal_nicht_vorhanden" 1023 "Fehler" ;
VAL_ 257 ESP_Verteil_Wankmom 30 "Init" 31 "Fehler" ;
VAL_ 257 ESP_QBit_Anf_Vert_Wank 0 "gueltiger_Wert" 1 "Ersatz_Init_oder_Fehlerwert" ;
VAL_ 257 ESP_Gierrate 16383 "Fehler" ;
VAL_ 257 ESP_VZ_Gierrate 0 "positiv" 1 "negativ" ;
VAL_ 257 ESP_Notbremsanzeige 0 "keine_Notbremsung_erkannt" 1 "Notbremsung_erkannt" ;
VAL_ 257 ESP_SpannungsAnf 0 "keine_Anforderung" 1 "Anforderung_Spannungswert_1" ;
VAL_ 257 ESP_PLA_Abbruch 0 "Init" 1 "Geschwindigkeitsueberschreitung" 2 "Falscher_PLA_Status" 3 "Deaktivierung_durch_Abbruch_Lenkung" 4 "PLA_Bremsanforderung_nach_Stillstand" 5 "Abbruch_durch_Kl15_aus" 6 "Abbruch_durch_FT_offen" ;
VAL_ 257 ESP_Status_ESP_PLA 0 "ESP_PLA_deaktiv" 1 "ESP_PLA_Init" 2 "ESP_PLA_Fehler" 4 "ESP_PLA_aktivierbar" 6 "ESP_PLA_Bremse_aktiv" 8 "ESP_PLA_funktionsbereit" 9 "ESP_PLA_Neustart" 10 "ESP_PLA_Abbruch" ;
VAL_ 259 ESP_VL_FR 0 "Vorwaerts" 1 "Rueckwaerts" ;
VAL_ 259 ESP_VR_FR 0 "Vorwaerts" 1 "Rueckwaerts" ;
VAL_ 259 ESP_HL_FR 0 "Vorwaerts" 1 "Rueckwaerts" ;
VAL_ 259 ESP_HR_FR 0 "Vorwaerts" 1 "Rueckwaerts" ;
VAL_ 259 ESP_VL_Radgeschw 4093 "Unterspannung" 4094 "Init" 4095 "Fehler" ;
VAL_ 259 ESP_VR_Radgeschw 4093 "Unterspannung" 4094 "Init" 4095 "Fehler" ;
VAL_ 259 ESP_HL_Radgeschw 4093 "Unterspannung" 4094 "Init" 4095 "Fehler" ;
VAL_ 259 ESP_HR_Radgeschw 4093 "Unterspannung" 4094 "Init" 4095 "Fehler" ;
VAL_ 776 ESP_Meldungen 0 "keine_Anzeige_kein_Gong" 1 "Autohold_Hinweis_1_und_kein_Gong" 2 "Stoerung_Autohold_und_1x_Gong" 3 "Stoerung_Hillholder_und_1x_Gong" 4 "Uebernehmen_und_1x_Gong" ;
VAL_ 776 ESP_HDC_FktLampe 0 "Aus" 1 "Ein" ;
VAL_ 776 ESP_Lampe 0 "Aus" 1 "Ein" ;
VAL_ 776 ABS_Lampe 0 "Aus" 1 "Ein" ;
VAL_ 776 BK_Lampe 0 "Aus" 1 "Ein" ;
VAL_ 776 ESP_Akustik 0 "keine_Akustik" 1 "1x_Beep" ;
VAL_ 776 ESP_Diagnose 0 "ESP_nicht_in_Diagnose" 1 "ESP_in_Diagnose" ;
VAL_ 776 ESP_Textanzeigen_02 0 "kein_Text" 1 "ESP_Stoerung" 2 "ABS_Stoerung" 3 "ESP_ABS_Stoerung" 4 "nicht_definiert" 5 "ASR_Stoerung" 6 "ESP_switched_off" 7 "ASR_off" 8 "ESP_ASR_on" 9 "Stoerung_Hillholder" 10 "keine_Bremskraftverstaerkung" 11 "ASR_aktiviert" 12 "ABS_ASR_Stoerung" 13 "bitte_Reifen_pruefen" 14 "Stoerung_Autohold" 15 "ESP_offroad" 16 "Autohold_Hinweis_1" 17 "ESP_sport" 18 "ESP_Zwangsaktivierung" 19 "ESP_Taster_Info" 20 "reserviert_fuer_TC_aktiv" 21 "Verlassenswarnung" 22 "reserviert_fuer_TC_switched_off" 23 "Verlwarn_akt_Rollsicherung_inakt" ;
VAL_ 776 ESP_Off_Lampe 0 "Lampe_aus" 1 "Lampe_ein" ;
VAL_ 776 ESP_m_Raddrehz 32765 "Unterspannung" 32766 "Init" 32767 "Fehler" ;
VAL_ 776 ESP_ASR_Lampe 0 "ESP_ASR_Lampe_aus" 1 "ESP_ASR_Lampe_an" ;
VAL_ 776 ESP_Fehlerstatus_Wegimp 0 "Wegimpulse_iO" 1 "Fehler" ;
VAL_ 776 ESP_Wegimp_Ueberlauf 0 "Reset_und_kein_Ueberlauf" 1 "mindestens_1x_Ueberlauf" ;
VAL_ 776 ESP_QBit_Wegimp_VA 0 "gueltiger_Wert" 1 "Ersatz_Init_oder_Fehlerwert" ;
VAL_ 776 ESP_Displaywarnungen 0 "keine_Warnung" 1 "BKL_Display_Warnung" 2 "Verlassenswarnung" 3 "Verlwarn_akt_Rollsicherung_inakt" ;
VAL_ 776 ESP_HDC_Regelgeschw 0 "nicht_verbaut" 125 "HDC_Standby" 126 "Init" 127 "Fehler" ;
VAL_ 776 ESP_BKV_Warnung 0 "keine_Anzeige_kein_Gong" 1 "keine_Bremskraftverstaerkung_plus_1x_Gong" ;
VAL_ 278 ESP_QBit_Wegimpuls_VL 0 "gueltiger_Wert" 1 "Ersatz_Init_oder_Fehlerwert" ;
VAL_ 278 ESP_QBit_Wegimpuls_VR 0 "gueltiger_Wert" 1 "Ersatz_Init_oder_Fehlerwert" ;
VAL_ 278 ESP_QBit_Wegimpuls_HL 0 "gueltiger_Wert" 1 "Ersatz_Init_oder_Fehlerwert" ;
VAL_ 278 ESP_QBit_Wegimpuls_HR 0 "gueltiger_Wert" 1 "Ersatz_Init_oder_Fehlerwert" ;
VAL_ 278 ESP_Wegimpuls_VL 1021 "Init" 1022 "Unterspannung" 1023 "Fehler" ;
VAL_ 278 ESP_Wegimpuls_VR 1021 "Init" 1022 "Unterspannung" 1023 "Fehler" ;
VAL_ 278 ESP_Wegimpuls_HL 1021 "Init" 1022 "Unterspannung" 1023 "Fehler" ;
VAL_ 278 ESP_Wegimpuls_HR 1021 "Init" 1022 "Unterspannung" 1023 "Fehler" ;
VAL_ 278 ESP_VL_Fahrtrichtung 0 "Vorwaerts" 1 "Rueckwaerts" 2 "Init" 3 "ungueltig_oder_nicht_verbaut" ;
VAL_ 278 ESP_VR_Fahrtrichtung 0 "Vorwaerts" 1 "Rueckwaerts" 2 "Init" 3 "ungueltig_oder_nicht_verbaut" ;
VAL_ 278 ESP_HL_Fahrtrichtung 0 "Vorwaerts" 1 "Rueckwaerts" 2 "Init" 3 "ungueltig_oder_nicht_verbaut" ;
VAL_ 278 ESP_HR_Fahrtrichtung 0 "Vorwaerts" 1 "Rueckwaerts" 2 "Init" 3 "ungueltig_oder_nicht_verbaut" ;
VAL_ 963 Motor_03_alt 0 "aktuell" 1 "veraltet" ;
VAL_ 963 Getriebe_03_alt 0 "aktuell" 1 "veraltet" ;
VAL_ 963 ESP_02_alt 0 "aktuell" 1 "veraltet" ;
VAL_ 963 Motor_05_alt 0 "aktuell" 1 "veraltet" ;
VAL_ 963 LWR_AFS_01_alt 0 "aktuell" 1 "veraltet" ;
VAL_ 963 EPB_01_alt 0 "aktuell" 1 "veraltet" ;
VAL_ 963 ESP_05_alt 0 "aktuell" 1 "veraltet" ;
VAL_ 963 ESP_01_alt 0 "aktuell" 1 "veraltet" ;
VAL_ 963 ESP_v_Signal 65533 "Unterspannung" 65534 "Init" 65535 "Fehler" ;
VAL_ 963 ESP_Notbremsanzeige 0 "keine_Notbremsung_erkannt" 1 "Notbremsung_erkannt" ;
VAL_ 963 ECD_Bremslicht 0 "Aus" 1 "Ein" ;
VAL_ 963 EPB_Status 0 "offen" 1 "Bremse_geschl_(Spannkraft_voll/reduziert)" 2 "Aktuator_im_Lauf" 3 "Fehler_oder_unbekannt" ;
VAL_ 963 MO_Anf_KL75 0 "Anforderung KL75 ausschalten" 1 "Anforderung KL75 einschalten" ;
VAL_ 963 MO_QBit_Fahrer_bremst 0 "gueltiger_Wert" 1 "Ersatz_Init_oder_Fehlerwert" ;
VAL_ 963 EPB_BCM2_Motor_Wakeup 0 "keine Anforderung" 1 "Anforderung an BCM2 Wakeupleitung zum Motor hochzuziehen aufgrund von Car-Wakeup" ;
VAL_ 963 ESP_QBit_v_Signal 0 "gueltiger_Wert" 1 "Ersatz_Init_oder_Fehlerwert" ;
VAL_ 963 GE_Waehlhebel 0 "Zwischenstellung (Darf nur für Zustandswechsel P/R, R/N, N/D ausgegeben werden, nicht für D/S oder D/Tippgasse wegen Abschaltkriterium GRA/ACC)" 1 "Init" 5 "Position P" 6 "Position R" 7 "Position N" 8 "Position D" 9 "Position S" 10 "Effizienz" 13 "Tipp_in_S" 14 "Tipp_in_D" 15 "Fehler" ;
VAL_ 963 MO_Motor_laeuft 0 "Motor läuft nicht" 1 "Motor läuft autark und stabil und darf mechanisch belastet werden" ;
VAL_ 963 MO_Verbot_EKP 0 "Ansteuerung zugelassen" 1 "Ansteuerung verboten" ;
VAL_ 963 MO_Anf_Pruefimpuls 0 "keine Anforderung" 1 "Anforderung" ;
VAL_ 963 LWR_Touristenmodus_aktiv 0 "Touristenmodus inaktiv" 1 "Touristenmodus aktiv" ;
VAL_ 963 MO_Drehzahl_01 65535 "Fehler" ;
VAL_ 963 MO_Klima_Eingr 0 "kein Eingriff" 1 "Klimakompressor ausschalten" 2 "Klimakompressor Leistungsreduzierung" 3 "Klimakompressor aufgrund der Heissleuchtenvorwarnung ausschalten" ;
VAL_ 963 MO_BLS 0 "kein Bremsen" 1 "Bremse betätigt" ;
VAL_ 963 MO_Fahrer_bremst 0 "kein Bremsen" 1 "Bremse betätigt" ;
VAL_ 963 MO_Aussp_Anlass 0 "Anlasser_darf_angesteuert_werden" 1 "Anlasser_ausspuren__Ansteuerung_nicht_moeglich" ;
VAL_ 963 MO_Freig_Anlass 0 "Start_nicht_zulaessig" 1 "Startfreigabe" ;
VAL_ 963 MO_Kuppl_schalter 0 "Schalter sagt betätigt (Ausgekuppelt)" 1 "Schalter sagt nicht betätigt (Eingekuppelt)" ;
VAL_ 963 MO_Interlock 0 "Interlockschalter nicht betätigt" 1 "Interlockschalter betätigt" ;
VAL_ 1643 Motor_07_alt 0 "aktuell" 1 "veraltet" ;
VAL_ 1643 Motor_Code_01_alt 0 "aktuell" 1 "veraltet" ;
VAL_ 1643 Kombi_02_alt 0 "aktuell" 1 "veraltet" ;
VAL_ 1643 Telefon_01_alt 0 "aktuell" 1 "veraltet" ;
VAL_ 1643 EPB_01_alt 0 "aktuell" 1 "veraltet" ;
VAL_ 1643 Motor_05_alt 0 "aktuell" 1 "veraltet" ;
VAL_ 1643 Motor_06_alt 0 "aktuell" 1 "veraltet" ;
VAL_ 1643 MO_Kuehlmittel_Temp 254 "Init" 255 "Fehler" ;
VAL_ 1643 KBI_Aussen_Temp_gef 253 "nicht verbaut" 254 "Init" 255 "Fehler" ;
VAL_ 1643 MO_Kraftstoffart 0 "Diesel" 1 "Benzin_inkl_E25_E85" 2 "CNG" 3 "LPG" 4 "Wasserstoff" 5 "E100_Ethanol" 15 "kein_Verbrennungskraftstoff" ;
VAL_ 1643 MO_Kennfeldk 0 "keine Kennfeldkühlung vorhanden" 1 "Kennfeldkühlung vorhanden" ;
VAL_ 1643 KBI_QBit_Aussen_Temp_gef 0 "gueltiger_Wert" 1 "Ersatz_Init_oder_Fehlerwert" ;
VAL_ 1643 MO_Absperrventil_oeffnen 0 "nicht_verfuegbar" 1 "Ansteuerung_Ventil_zulaessig" 2 "Ventil_oeffnen_oder_geoeffnet" 3 "Ventil_schliessen_oder_geschlossen" ;
VAL_ 1643 KBI_Reset_Standzeit 0 "Standzeit iO" 1 "KL30 war weg" ;
VAL_ 1643 EPB_QBit_Pedalweg_Kuppl 0 "gültiger Wert" 1 "Ersatz-, Init- oder Fehlerwert" ;
VAL_ 1643 TF_Mute_Msg_Code 0 "Phonecall" 1 "Speech Recognition active" 2 "Emergency Call" 3 "beep-signal" 4 "Operator Call" 5 "Ring" 6 "Phonecall wideband" 7 "Stereo Audio (source mobile)" ;
VAL_ 1643 MO_HYB_Fahrbereitschaft 0 "keine_Fahrbereitschaft" 1 "Fahrbereitschaft" ;
VAL_ 1643 MO_EKlKomLeiRed 0 "keine_Leistungsbegr" 1 "Leistungsbegr_75" 2 "Leistungsbegr_50" 3 "Leistungsbegr_25" ;
VAL_ 1643 EPB_Pedalweg_Kuppl 0 "Init" 255 "Fehler" ;
VAL_ 924 BCM1_02_alt 0 "aktuell" 1 "veraltet" ;
VAL_ 924 Wischer_01_alt 0 "aktuell" 1 "veraltet" ;
VAL_ 924 Klima_02_alt 0 "aktuell" 1 "veraltet" ;
VAL_ 924 BCM1_01_alt 0 "aktuell" 1 "veraltet" ;
VAL_ 924 ESP_07_alt 0 "aktuell" 1 "veraltet" ;
VAL_ 924 TSG_BT_1_alt 0 "aktuell" 1 "veraltet" ;
VAL_ 924 TSG_HL_1_alt 0 "aktuell" 1 "veraltet" ;
VAL_ 924 TSG_HR_1_alt 0 "aktuell" 1 "veraltet" ;
VAL_ 924 Motor_02_alt 0 "aktuell" 1 "veraltet" ;
VAL_ 924 Klima_Sensor_02_alt 0 "aktuell" 1 "veraltet" ;
VAL_ 924 TSG_FT_1_alt 0 "aktuell" 1 "veraltet" ;
VAL_ 924 Motor_05_alt 0 "aktuell" 1 "veraltet" ;
VAL_ 924 QSP_01_alt 0 "aktuell" 1 "veraltet" ;
VAL_ 924 Parkhilfe_01_alt 0 "aktuell" 1 "veraltet" ;
VAL_ 924 Fahrwerk_02_alt 0 "aktuell" 1 "veraltet" ;
VAL_ 924 BCM1_MH_WIV_Schalter 0 "MH_geschlossen" 1 "MH_offen" ;
VAL_ 924 Wischer_vorne_aktiv 1 "Wischer vorne läuft" ;
VAL_ 924 BCM1_Rueckfahrlicht_Schalter 0 "aus" 1 "betaetigt" ;
VAL_ 924 MO_Status_Normalbetrieb_01 0 "kein Normalbetrieb" 1 "Normalbetrieb erreicht" ;
VAL_ 924 KL_Zuheizer_Freigabe 0 "keine_Freigabe_Zuheizer" 1 "Zuheizerfreigabe" ;
VAL_ 924 BCM1_Vorwaertsgang_eingelegt 0 "Rueckwaertsgang bzw. restliche Gaenge eingelegt" 1 "Erster oder zweiter Gang eingelegt" ;
VAL_ 924 ESP_Codierung_ADS 0 "Init" 1 "ESP_nicht_ADS_codiert" 2 "ADS_codiert" 3 "tbd" ;
VAL_ 924 QSP_StartStopp_Info 0 "Motorlauf_nicht_notwendig_(Stoppfreigabe)" 1 "Motoranlauf_nicht_zwingend_notwendig_(Stoppverbot,keine_Startanforderung)" 2 "Motoranlauf_zwingend_notwendig_(Startanforderung)" 3 "Systemfehler" ;
VAL_ 924 FA_StartStopp_Info 0 "Motorlauf_nicht_notwendig_(Stoppfreigabe)" 1 "Motoranlauf_nicht_zwingend_notwendig_(Stoppverbot,keine_Startanforderung)" 2 "Motoranlauf_zwingend_notwendig_(Startanforderung)" 3 "Systemfehler" ;
VAL_ 924 PH_StartStopp_Info 0 "Motorlauf_nicht_notwendig_(Stoppfreigabe)" 1 "Motoranlauf_nicht_zwingend_notwendig_(Stoppverbot,keine_Startanforderung)" 2 "Motoranlauf_zwingend_notwendig_(Startanforderung)" 3 "Systemfehler" ;
VAL_ 924 KL_Beschlagsgefahr 0 "keine_Beschlagsgefahr" 1 "Beschlagsgefahr" ;
VAL_ 924 BCM1_GLW_Fernlicht_Anf 0 "Aus" 1 "Ein" ;
VAL_ 924 BCM1_RFahrlicht_Fzg_Anf 0 "Licht_nicht_angefordert" 1 "Licht ist einzuschalten" ;
VAL_ 924 FT_Tuer_geoeffnet 1 "Tuer offen" ;
VAL_ 924 MO_Handshake_STH 0 "keine EKP-Ansteuerung durch STH-Anforderung" 1 "EKP-Ansteuerung durch STH-Anforderung" ;
VAL_ 924 FT_Sperrklinke 0 "Schloss_in_Vorraste_und_Hauptraste" 1 "Tuer_auf_oder_Tuer_Position_zwischen_Vor_und_Hauptraste" ;
VAL_ 924 BCM1_OBD_FStatus_ATemp 0 "kein Fehler / Init / nicht verbaut" 1 "KS- (Kurzschluss nach minus)" 2 "KS+ (Kurzschluss nach plus)" 3 "OC (Leitungsunterbrechung)" 4 "OOR+ (Signal zu gross)" 5 "OOR- (Signal zu klein)" 6 "RC+ (Signal unplausibel zu gross)" 7 "RC- (Signal unplausibel zu klein)" 8 "KS+/OC (Kurzschluss nach plus/Unterbrechung)" 9 "KS-/OC  (Kurzschluss nach minus/Unterbrechung)" 10 "KS-/KS+  (Kurzschluss nach minus/plus)" 11 "KS-/KS+/OC (Kurzschluss nach minus/plus/Unterbrechung)" 14 "frei" 15 "frei" ;
VAL_ 924 BCM1_Aussen_Temp_ungef 253 "nicht verbaut" 254 "Initwert" 255 "Fehler" ;
VAL_ 924 BCM1_Oeldruck_Schalter 0 "offen" 1 "geschlossen (p > p soll)" ;
VAL_ 924 BCM1_Oeldruck_Schalter_2 0 "offen" 1 "geschlossen" ;
VAL_ 924 BT_Tuer_geoeffnet 1 "Tuer_offen" ;
VAL_ 924 HL_Tuer_geoeffnet 1 "Tuer geoeffnet" ;
VAL_ 924 HR_Tuer_geoeffnet 1 "Tuer offen" ;
VAL_ 924 BCM1_Adaptive_Lichtvert_Anf 0 "Aus" 1 "Ein" ;
VAL_ 924 BCM1_Gleitende_Leuchtw_Anf 0 "Aus" 1 "Ein" ;
VAL_ 924 BCM1_Schalter_StartStopp 0 "Start_Stopp_ueber_Hauptschalter_deaktiviert" 1 "Start_Stopp_ueber_Hauptschalter_aktiviert" ;
VAL_ 924 ESP_Offroad_Modus 0 "kein_ESP_Offroadmodus" 1 "ESP_Offroadmodus" ;
VAL_ 924 MO_Freig_Reku 0 "Rekuperations-Modus aus" 1 "Empfehlung Spannungsanhebung" 2 "Empfehlung Spannungsabsenkung" 3 "Rekuperationsmodus aktiv, Spannungsvariation nicht notwendig" ;
VAL_ 924 KL_HSH_ein_Soll 0 "Fahrerwunsch_HSH_aus" 1 "Fahrerwunsch_HSH_ein" ;
VAL_ 924 FT_Tuerkontakt_Rohsignal 0 "Schalter_geschlossen_Tuer_auf" 1 "Schalter_offen_Tuer_zu" ;
VAL_ 1318 Klima_Sensor_02_alt 0 "aktuell" 1 "veraltet" ;
VAL_ 1318 Wischer_01_alt 0 "aktuell" 1 "veraltet" ;
VAL_ 1318 SMLS_01_alt 0 "aktuell" 1 "veraltet" ;
VAL_ 1318 Kessy_02_alt 0 "aktuell" 1 "veraltet" ;
VAL_ 1318 Blinkmodi_01_inaktiv 0 "aktuell" 1 "veraltet" ;
VAL_ 1318 Anhaenger_01_alt 0 "aktuell" 1 "veraltet" ;
VAL_ 1318 BCM1_01_alt 0 "aktuell" 1 "veraltet" ;
VAL_ 1318 BCM1_02_alt 0 "aktuell" 1 "veraltet" ;
VAL_ 1318 Innenlicht_01_alt 0 "aktuell" 1 "veraltet" ;
VAL_ 1318 BCM2_02_alt 0 "aktuell" 1 "veraltet" ;
VAL_ 1318 Motor_06_alt 0 "aktuell" 1 "veraltet" ;
VAL_ 1318 TSG_FT_01_alt 0 "aktuell" 1 "veraltet" ;
VAL_ 1318 BCM1_Aussen_Temp_ungef 253 "nicht verbaut" 254 "Initwert" 255 "Fehler" ;
VAL_ 1318 BCM1_FStatus_Aussentemp_ungef 0 "iO" 1 "niO" ;
VAL_ 1318 Wischer_vorne_aktiv 1 "Wischer vorne läuft" ;
VAL_ 1318 BH_Blinker_li 0 "nicht_betaetigt" 1 "Blinkerhebel_Richtung_links_betaetigt" ;
VAL_ 1318 BH_Blinker_re 0 "nicht_betaetigt" 1 "Blinkerhebel_Richtung_rechts_betaetigt" ;
VAL_ 1318 KY_Funkschl_Nr 0 "kein authorisierter Schluessel erkannt" 1 "aktive_Funkschluessel_Nr_01" 2 "aktive_Funkschluessel_Nr_02" 3 "aktive_Funkschluessel_Nr_03" 4 "aktive_Funkschluessel_Nr_04" 5 "aktive_Funkschluessel_Nr_05" 6 "aktive_Funkschluessel_Nr_06" 7 "aktive_Funkschluessel_Nr_07" 8 "aktive_Funkschluessel_Nr_08" 9 "ungueltig_09" 10 "ungueltig_10" 11 "ungueltig_11" 12 "ungueltig_12" 13 "ungueltig_13" 14 "ungueltig_14" 15 "ungueltig_15" ;
VAL_ 1318 BCM1_Rueckfahrlicht_Schalter 0 "aus" 1 "betaetigt" ;
VAL_ 1318 AAG_Anhaenger_erkannt 0 "kein_Anhaenger_erkannt" 1 "AAG_Anhaenger_erkannt" ;
VAL_ 1318 BM_links 0 "Richtungsblinken links nicht aktiv " 1 "Richtungsblinken links aktiv " ;
VAL_ 1318 BM_rechts 0 "Richtungsblinken rechts nicht aktiv " 1 "Richtungsblinken rechts aktiv " ;
VAL_ 1318 BH_Fernlicht 0 "nicht_betaetigt" 1 "Blinkerhebel_in_Richtung_Fernlicht_betaetigt" ;
VAL_ 1318 LDW_Taster 0 "unbetätigt" 1 "betaetigt" ;
VAL_ 1318 LDW_Taster_Fehler 0 "kein Fehler" 1 "Fehler" ;
VAL_ 1318 LDW_Vib_Lenkrad_Fehler 0 "kein Fehler" 1 "Fehler" ;
VAL_ 1318 LV_Fernlicht_Anzeige 0 "nicht aktiv" 1 "aktiv" ;
VAL_ 1318 LV_Abblendlicht_Anzeige 0 "nicht aktiv" 1 "aktiv" ;
VAL_ 1318 LV_Nebellicht_Anzeige 0 "nicht aktiv" 1 "aktiv" ;
VAL_ 1318 IL_Innenlicht_aktiv 0 "Innenlicht inaktiv" 1 "Innenlicht aktiv" ;
VAL_ 1318 BCM1_MH_Schalter 0 "MH_geschlossen" 1 "MH_offen" ;
VAL_ 1318 ZV_FT_offen 1 "FT_geoeffnet" ;
VAL_ 1318 ZV_BT_offen 1 "BT_geoeffnet" ;
VAL_ 1318 ZV_HL_offen 1 "Tuer_HL_geoeffnet" ;
VAL_ 1318 ZV_HR_offen 1 "Tuer_HR_geoeffnet" ;
VAL_ 1318 ZV_HD_offen 1 "Heckdeckel_auf" ;
VAL_ 1318 ZV_verriegelt_extern_ist 1 "Fahrzeug_aussen_verriegelt_Istzustand" ;
VAL_ 1318 ZV_ist_Zustand_verfuegbar 0 "nicht_verfuegbar" 1 "verfuegbar_alle_TSGs_am_Bus" ;
VAL_ 1318 BCM1_NV_Taster 0 "Taster_nicht_betaetigt" 1 "Taster_betaetigt" ;
VAL_ 1318 MO_HYB_Fahrbereitschaft 0 "keine_Fahrbereitschaft" 1 "Fahrbereitschaft" ;
VAL_ 1318 HUD_VZE_in_Anzeige 0 "VZE_nicht_in_Anzeige" 1 "VZE_in_Anzeige" ;
VAL_ 1318 FT_SWA_Taster 0 "Taster_unbetaetigt" 1 "Taster_betaetigt" ;
VAL_ 1318 FT_SWA_Tasterdiagnose 0 "Kein_Fehler" 1 "Fehler_Erkannt" ;
VAL_ 258 GE_Freig_Langfr_Schutzmom 0 "nicht freigegeben" 1 "freigegeben" ;
VAL_ 258 GE_Uefkt 1023 "Fehler" ;
VAL_ 258 GE_Zielgang 0 "Gang P/N (ausgekuppelt)" 1 "Gang 1" 2 "Gang 2" 3 "Gang 3" 4 "Gang 4" 5 "Gang 5" 6 "Gang 6" 7 "Gang 7" 8 "Gang R" 11 "Gang 8" 12 "Gang 9" 14 "Istgang nicht definiert" 15 "Fehler" ;
VAL_ 258 GE_StartStopp_Info 0 "Motorlauf_nicht_notwendig_(Stoppfreigabe)" 1 "Motoranlauf_nicht_zwingend_notwendig_(Stoppverbot,keine_Startanforderung)" 2 "Motoranlauf_zwingend_notwendig_(Startanforderung)" 3 "Systemfehler" ;
VAL_ 258 GE_Langfr_Schutzmom 1022 "Init" 1023 "Fehler" ;
VAL_ 258 GE_Performance_Start_LB 0 "nicht_aktiv" 1 "aktiv" ;
VAL_ 258 GE_Waehlhebel 0 "Zwischenstellung (Darf nur für Zustandswechsel P/R, R/N, N/D ausgegeben werden, nicht für D/S oder D/Tippgasse wegen Abschaltkriterium GRA/ACC)" 1 "Init" 5 "Position P" 6 "Position R" 7 "Position N" 8 "Position D" 9 "Position S" 10 "Effizienz" 13 "Tipp_in_S" 14 "Tipp_in_D" 15 "Fehler" ;
VAL_ 258 GE_Eingangsdrehz 16382 "Init" 16383 "Fehler" ;
VAL_ 258 GE_Notlauf 0 "kein Notlauf / Init" 1 "Getriebe im Notlauf" ;
VAL_ 258 GE_Codierung_MSG 0 "Codierung iO / Init" 1 "Codierung niO" ;
VAL_ 1612 GW_Karosserie_Typ 0 "Coupe" 1 "Cabrio" 2 "Targa" 3 "Reserve" 4 "Reserve" 5 "Reserve" 6 "Reserve" 7 "Reserve" 8 "Reserve" 9 "Reserve" 10 "Reserve" 11 "Reserve" 12 "Reserve" 13 "Reserve" 14 "Reserve" 15 "Reserve" ;
VAL_ 1612 GW_Lenker 0 "Linkslenker" 1 "Rechtslenker" ;
VAL_ 1612 GW_Baureihe 0 "Panamera" 1 "Cayenne" 2 "Carrera_oder_918_Spyder" 3 "Boxster" 4 "Cajun" 5 "Reserve" 6 "Reserve" 7 "Reserve" 8 "Reserve" 9 "Reserve" 10 "Reserve" 11 "Reserve" 12 "Reserve" 13 "Reserve" 14 "Reserve" 15 "Reserve" ;
VAL_ 1612 GW_Fzg_Antrieb 0 "Zweiradantrieb" 1 "Vierradantrieb" 2 "Reserve" 3 "Reserve" 4 "Reserve" 5 "Reserve" 6 "Reserve" 7 "Reserve" 8 "Reserve" 9 "Reserve" 10 "Reserve" 11 "Reserve" 12 "Reserve" 13 "Reserve" 14 "Reserve" 15 "Reserve" ;
VAL_ 909 BCM1_Rueckfahrlicht_Schalter 0 "aus" 1 "betaetigt" ;
VAL_ 909 HD_Bewegung_zu 1 "HD in Bewegung zu" ;
VAL_ 909 KY1_FuSchl_Nr_Zugang 0 "kein authorisierter Schluessel erkannt" 1 "aktive_Funkschluessel_Nr_01" 2 "aktive_Funkschluessel_Nr_02" 3 "aktive_Funkschluessel_Nr_03" 4 "aktive_Funkschluessel_Nr_04" 5 "aktive_Funkschluessel_Nr_05" 6 "aktive_Funkschluessel_Nr_06" 7 "aktive_Funkschluessel_Nr_07" 8 "aktive_Funkschluessel_Nr_08" 9 "ungueltig_09" 10 "ungueltig_10" 11 "ungueltig_11" 12 "ungueltig_12" 13 "ungueltig_13" 14 "ungueltig_14" 15 "ungueltig_15" ;
VAL_ 909 VS_VD_Bew_auf 1 "Verdeck in Bewegung auf" ;
VAL_ 909 VS_VD_Bew_zu 1 "Verdeck in Bewegung zu " ;
VAL_ 909 VS_VD_Fehler 1 "Fehlerzustand Verdeck " ;
VAL_ 909 F_Kessy_01_Mmi 0 "aktuell" 1 "veraltet" ;
VAL_ 909 F_HDSG_01_Mmi 0 "aktuell" 1 "veraltet" ;
VAL_ 909 F_BCM1_01_Mmi 0 "aktuell" 1 "veraltet" ;
VAL_ 909 F_VSG_01_Mmi 0 "aktuell" 1 "veraltet" ;
VAL_ 1514 DR_Gelbe_Warnlampe 0 "Warnlampe aus" 1 "Warnlampe ein (Aufprüfen)" 2 "Warnlampe an (Warnung)" 3 "reserviert" ;
VAL_ 1514 Ni_Anzeige_WaMe_gelb 0 "Aus" 1 "Ein" ;
VAL_ 1514 Ni_Anzeige_WaMe_rot 0 "Aus" 1 "Ein" ;
VAL_ 1514 PDCC_W_Oel 0 "Oelstand_i_O" 1 "Oelstand_n_i_O" ;
VAL_ 1514 DR_Rote_Warnlampe 0 "Warnlampe aus" 1 "Warnlampe ein (Aufprüfen)" 2 "Warnlampe an (Warnung)" 3 "reserviert" ;
VAL_ 1514 DR_DynAGL_Warnlampe 0 "Warnlampe aus" 1 "Warnlampe ein" ;
VAL_ 1514 F_Fahrwerk_05_Mmi 0 "aktuell" 1 "veraltet" ;
VAL_ 1514 F_Daempfer_01_FR_Mmi 0 "aktuell" 1 "veraltet" ;
VAL_ 1514 F_PDCC_01_Mmi 0 "aktuell" 1 "veraltet" ;
VAL_ 796 MO_Drehzahl_01 65535 "Fehler" ;
VAL_ 796 MO_Kuehlmittel_Temp 254 "Init" 255 "Fehler" ;
VAL_ 796 DR_Daempferreg_Texte 0 "kein Text" 1 "Daempfer_Sport" 2 "Daempfer_Basis" 3 "Daempfer_Comfort" 15 "Verlademodus" ;
VAL_ 796 MO_Ext_E_Fahrt_aktiv 0 "Rueckmeldung_E_Taster_aus" 1 "Rueckmeldung_E_Taster_ein" ;
VAL_ 796 MO_HYB_VM_aktiv 0 "VM_nicht_aktiv" 1 "VM_aktiv" ;
VAL_ 796 MO_Fehler_MSpG 0 "i.O." 1 "Gebläse defekt oder Motorraumtemp. zu hoch" ;
VAL_ 796 MO_Overboost 0 "inaktiv" 1 "aktiv" ;
VAL_ 796 DR_Systemstatus 0 "Init oder kein Wert verfuegbar" 1 "Komfortabel" 2 "Normal" 3 "Sport 1" 4 "Sport 2" 5 "nicht funktionsfähig" 6 "Funktionseinschränkung aktiv" 7 "Notfahrfunktion" ;
VAL_ 796 FA_Reglerstatus_Niveau 0 "nicht_definiert" 1 "Tiefniveau_2" 2 "Tiefniveau_1" 3 "Normalniveau" 4 "Hochniveau_1" 5 "Hochniveau_2" 6 "nicht_definiert" 7 "Heckabsenkung" 8 "Beladungsniveau" 9 "Verladeniveau" 10 "nicht_definiert" 11 "nicht_definiert" 12 "nicht_definiert" 13 "nicht_definiert" 14 "nicht_definiert" 15 "nicht_definiert" ;
VAL_ 796 GE_Segel_Status 0 "System aktiv (mindestens eine Komponentenfreigabe fehlt)" 1 "System aktiv (Freigaben aller Komponenten liegen vor)" 2 "reserviert" 3 "System in diesem Kl15 Zyklus nicht verfügbar" ;
VAL_ 796 GE_Status_PaddleNeutral 0 "Paddle_Neutral_inaktiv" 1 "Paddle_Neutral_aktiv" 2 "Paddle_Neutral_Ende_Timer_aktiv" 3 "Paddle_Neutral_Zwangsausstieg" ;
VAL_ 796 F_Daempfer_01_FR_Mmi 0 "aktuell" 1 "veraltet" ;
VAL_ 796 F_Fahrwerk_02_Mmi 0 "aktuell" 1 "veraltet" ;
VAL_ 796 F_Motor_03_Mmi 0 "aktuell" 1 "veraltet" ;
VAL_ 796 F_Motor_07_Mmi 0 "aktuell" 1 "veraltet" ;
VAL_ 796 F_Motor_15_PAG_Mmi 0 "aktuell" 1 "veraltet" ;
VAL_ 796 F_Motor_02_Mmi 0 "aktuell" 1 "veraltet" ;
VAL_ 796 F_Motor_Hybrid_01_Mmi 0 "aktuell" 1 "veraltet" ;
VAL_ 796 F_Getriebe_07_PAG 0 "aktuell" 1 "veraltet" ;
VAL_ 908 HAL_Warnungen 0 "keine_Warnung" 1 "Ausfall_rote_Warnung" 2 "Systemstoerung_gelbe_Warnung" 3 "HAL_deaktiviert" ;
VAL_ 908 ESP_Querbeschleunigung_Roh 511 "Fehler" ;
VAL_ 908 ESP_Querbeschleunigung_Offset 62 "Init" 63 "Fehler" ;
VAL_ 908 ESP_Eingriff 0 "kein_ESP_Eingriff" 1 "ESP_Eingriff_aktiv" ;
VAL_ 908 ESP_Off_Lampe 0 "Lampe_aus" 1 "Lampe_ein" ;
VAL_ 908 ESP_Rollenmodus 0 "Rollenmodus_nicht_aktiv" 1 "Rollenmodus_aktiv" ;
VAL_ 908 ESP_Stillstandsflag 0 "kein_Stillstand_erkannt" 1 "Stillstand_erkannt" ;
VAL_ 908 ESP_Autohold_aktiv 0 "Autohold_inaktiv" 1 "Autohold_aktiv" ;
VAL_ 908 ESP_HDC_Standby 0 "HDC_Funktion_nicht_im_Standby" 1 "HDC_Funktion_im_Standby" ;
VAL_ 908 F_ESP_05_Mmi 0 "aktuell" 1 "veraltet" ;
VAL_ 908 F_ESP_01_Mmi 0 "aktuell" 1 "veraltet" ;
VAL_ 908 F_ESP_04_Mmi 0 "aktuell" 1 "veraltet" ;
VAL_ 908 F_ESP_02_Mmi 0 "aktuell" 1 "veraltet" ;
VAL_ 908 F_ESP_11_Mmi 0 "aktuell" 1 "veraltet" ;
VAL_ 908 F_ESP_13_Mmi 0 "aktuell" 1 "veraltet" ;
VAL_ 908 HAL_01_alt 0 "aktuell" 1 "veraltet" ;
VAL_ 1515 FS_MMB_storage 0 "keine Zuweisung" 1 "P1/FP1 Pos Zuweisung" 2 "P2/FP2 Pos Zuweisung" 3 "P3/FP3 Pos Zuweisung" 4 "P4/FP4 Pos Zuweisung; an den im System aktiven Funkschlüssel/FPI ID über MMI" 5 "FS1" 6 "FS2" 7 "FS3" 8 "FS4" ;
VAL_ 1515 FS_MMB_storage_beep 0 "beep aus" 1 "beep ein" ;
VAL_ 1515 FS_MMB_store 0 "nicht speichern__kein keyless verbaut" 1 "abspeichern__keyless verbaut" ;
VAL_ 1515 FS_MMB_tipp 0 "kein_Tippbetrieb" 1 "Tippbetrieb__automatisches Funkschlüsselmemory aktivieren;" ;
VAL_ 1515 FS_MMB_tast 0 "kein_Tastbetrieb" 1 "Tastbetrieb__Fingerprintautomatismus aktivieren über MMI" ;
VAL_ 1515 BFS_MMB_storage 0 "keine Zuweisung" 1 "P1/FP1 Pos Zuweisung" 2 "P2/FP2 Pos Zuweisung" 3 "P3/FP3 Pos Zuweisung" 4 "P4/FP4 Pos Zuweisung an den im System aktiven Funkschlüssel/FPI ID über MMI" 5 "FS1" 6 "FS2" 7 "FS3" 8 "FS4" ;
VAL_ 1515 BFS_MMB_storage_beep 0 "beep_aus" 1 "beep ein" ;
VAL_ 1515 BFS_MMB_store 0 "nicht speichern" 1 "speichern" ;
VAL_ 1515 BFS_MMB_tipp 0 "kein_Tippbetrieb" 1 "Tippbetrieb" ;
VAL_ 1515 BFS_MMB_tast 0 "kein_Tastbetrieb" 1 "Tastbetrieb" ;
VAL_ 1515 BFS_MMB_store_LED_on 0 "LED_aus" 1 "LED ein" ;
VAL_ 1515 LWI_Lenkradwinkel 8190 "Init" 8191 "Fehler" ;
VAL_ 1515 LWI_VZ_Lenkradwinkel 0 "positiv_links_von_der_Nullstellung" 1 "negativ" ;
VAL_ 1515 LWI_Sensorstatus 0 "iO" 1 "nicht kalibriert" ;
VAL_ 1515 LWI_QBit_Lenkradwinkel 0 "gültiger Wert" 1 "ausserhalb der Spezifikation" ;
VAL_ 1515 F_LWI_01_Mmi 0 "aktuell" 1 "veraltet" ;
VAL_ 1515 F_Mem_BFS_01_Mmi 0 "aktuell" 1 "veraltet" ;
VAL_ 1515 F_Mem_FS_01_Mmi 0 "aktuell" 1 "veraltet" ;
